VERSION "HNNBNNNYNNNNNNNNNNNNNNNNNNNNNNNNNNNNNNNNNN/4/%%%/4/'%**4NNN///"

NS_ :

BS_:

BU_: AFS AFS_LMod_L AFS_LMod_R BCM1 BVS FCM GLW_LMod_L GLW_LMod_R LCM_L LCM_R LED_DK3_LM_L LED_DK3_LM_R LED_LM_L LED_LM_R LLP_L LLP_R LWR_MXB_L LWR_MXB_R MXB MXB_LM_L MXB_LM_R ZFAS

BO_ 1389 LED_Mess_LM_L_01: 8 LED_LM_L
 SG_ LED_L_Uspg_Schutz : 23|1@1+ (1,0) [0|1] ""  AFS,BCM1,FCM,MXB
 SG_ LED_L_Spannung_KL15 : 24|7@1+ (0.1,6) [6|18.5] "Unit_Volt"  AFS,BCM1,FCM,MXB
 SG_ LED_L_Spannung_KL56a : 31|7@1+ (0.1,6) [6|18.5] "Unit_Volt"  AFS,BCM1,FCM,MXB
 SG_ LED_L_Spannung_KL56b : 38|7@1+ (0.1,6) [6|18.5] "Unit_Volt"  AFS,BCM1,FCM,MXB
 SG_ LED_L_Spannung_TFL : 45|7@1+ (0.1,6) [6|18.5] "Unit_Volt"  AFS,BCM1,FCM,MXB
 SG_ LED_L_Temp_Schutz : 52|1@1+ (1,0) [0|1] ""  AFS,BCM1,FCM,MXB
 SG_ LED_L_Temp_Mux M : 53|3@1+ (1,0) [0|7] ""  AFS,BCM1,FCM,MXB
 SG_ LED_L_Temp_SG_Intern m0 : 56|8@1+ (1,-50) [-50|204] "Unit_DegreCelsi"  AFS,BCM1,FCM,MXB
 SG_ LED_L_Temp_Kanal1_Master m1 : 56|8@1+ (1,-50) [-50|204] "Unit_DegreCelsi"  AFS,BCM1,FCM,MXB
 SG_ LED_L_Temp_Kanal1_Master2 m2 : 56|8@1+ (1,-50) [-50|204] "Unit_DegreCelsi"  AFS,BCM1,FCM,MXB
 SG_ LED_L_Temp_Kanal1_Slave m3 : 56|8@1+ (1,-50) [-50|204] "Unit_DegreCelsi"  AFS,BCM1,FCM,MXB
 SG_ LED_L_Temp_Kanal2_Master m4 : 56|8@1+ (1,-50) [-50|204] "Unit_DegreCelsi"  AFS,BCM1,FCM,MXB
 SG_ LED_L_Temp_Kanal2_Slave m5 : 56|8@1+ (1,-50) [-50|204] "Unit_DegreCelsi"  AFS,BCM1,FCM,MXB
 SG_ LED_L_Temp_Kanal3_Master m6 : 56|8@1+ (1,-50) [-50|204] "Unit_DegreCelsi"  AFS,BCM1,FCM,MXB
 SG_ LED_L_Temp_Kanal3_Slave m7 : 56|8@1+ (1,-50) [-50|204] "Unit_DegreCelsi"  AFS,BCM1,FCM,MXB

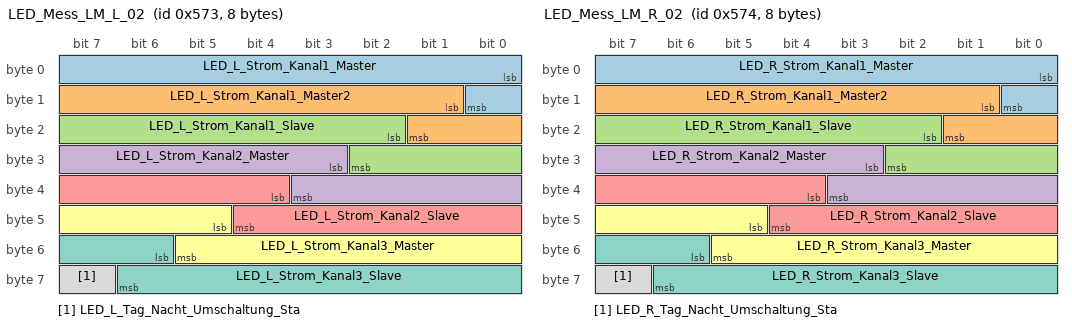
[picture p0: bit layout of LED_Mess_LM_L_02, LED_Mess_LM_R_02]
BO_ 1395 LED_Mess_LM_L_02: 8 LED_LM_L
 SG_ LED_L_Strom_Kanal1_Master : 0|9@1+ (3,0) [0|1515] "Unit_MilliAmper"  AFS,BCM1,FCM,MXB
 SG_ LED_L_Strom_Kanal1_Master2 : 9|9@1+ (3,0) [0|1515] "Unit_MilliAmper"  AFS,BCM1,FCM,MXB
 SG_ LED_L_Strom_Kanal1_Slave : 18|9@1+ (3,0) [0|1515] "Unit_MilliAmper"  AFS,BCM1,FCM,MXB
 SG_ LED_L_Strom_Kanal2_Master : 27|9@1+ (3,0) [0|1515] "Unit_MilliAmper"  AFS,BCM1,FCM,MXB
 SG_ LED_L_Strom_Kanal2_Slave : 36|9@1+ (3,0) [0|1515] "Unit_MilliAmper"  AFS,BCM1,FCM,MXB
 SG_ LED_L_Strom_Kanal3_Master : 45|9@1+ (3,0) [0|1515] "Unit_MilliAmper"  AFS,BCM1,FCM,MXB
 SG_ LED_L_Strom_Kanal3_Slave : 54|9@1+ (3,0) [0|1515] "Unit_MilliAmper"  AFS,BCM1,FCM,MXB
 SG_ LED_L_Tag_Nacht_Umschaltung_Sta : 63|1@1+ (1,0) [0|1] ""  AFS,BCM1,FCM,MXB

BO_ 1390 LED_Mess_LM_R_01: 8 LED_LM_R
 SG_ LED_R_Uspg_Schutz : 23|1@1+ (1,0) [0|1] ""  AFS,BCM1,FCM,MXB
 SG_ LED_R_Spannung_KL15 : 24|7@1+ (0.1,6) [6|18.5] "Unit_Volt"  AFS,BCM1,FCM,MXB
 SG_ LED_R_Spannung_KL56a : 31|7@1+ (0.1,6) [6|18.5] "Unit_Volt"  AFS,BCM1,FCM,MXB
 SG_ LED_R_Spannung_KL56b : 38|7@1+ (0.1,6) [6|18.5] "Unit_Volt"  AFS,BCM1,FCM,MXB
 SG_ LED_R_Spannung_TFL : 45|7@1+ (0.1,6) [6|18.5] "Unit_Volt"  AFS,BCM1,FCM,MXB
 SG_ LED_R_Temp_Schutz : 52|1@1+ (1,0) [0|1] ""  AFS,BCM1,FCM,MXB
 SG_ LED_R_Temp_Mux M : 53|3@1+ (1,0) [0|7] ""  AFS,BCM1,FCM,MXB
 SG_ LED_R_Temp_SG_Intern m0 : 56|8@1+ (1,-50) [-50|204] "Unit_DegreCelsi"  AFS,BCM1,FCM,MXB
 SG_ LED_R_Temp_Kanal1_Master m1 : 56|8@1+ (1,-50) [-50|204] "Unit_DegreCelsi"  AFS,BCM1,FCM,MXB
 SG_ LED_R_Temp_Kanal1_Master2 m2 : 56|8@1+ (1,-50) [-50|204] "Unit_DegreCelsi"  AFS,BCM1,FCM,MXB
 SG_ LED_R_Temp_Kanal1_Slave m3 : 56|8@1+ (1,-50) [-50|204] "Unit_DegreCelsi"  AFS,BCM1,FCM,MXB
 SG_ LED_R_Temp_Kanal2_Master m4 : 56|8@1+ (1,-50) [-50|204] "Unit_DegreCelsi"  AFS,BCM1,FCM,MXB
 SG_ LED_R_Temp_Kanal2_Slave m5 : 56|8@1+ (1,-50) [-50|204] "Unit_DegreCelsi"  AFS,BCM1,FCM,MXB
 SG_ LED_R_Temp_Kanal3_Master m6 : 56|8@1+ (1,-50) [-50|204] "Unit_DegreCelsi"  AFS,BCM1,FCM,MXB
 SG_ LED_R_Temp_Kanal3_Slave m7 : 56|8@1+ (1,-50) [-50|204] "Unit_DegreCelsi"  AFS,BCM1,FCM,MXB

BO_ 1396 LED_Mess_LM_R_02: 8 LED_LM_R
 SG_ LED_R_Strom_Kanal1_Master : 0|9@1+ (3,0) [0|1515] "Unit_MilliAmper"  AFS,BCM1,FCM,MXB
 SG_ LED_R_Strom_Kanal1_Master2 : 9|9@1+ (3,0) [0|1515] "Unit_MilliAmper"  AFS,BCM1,FCM,MXB
 SG_ LED_R_Strom_Kanal1_Slave : 18|9@1+ (3,0) [0|1515] "Unit_MilliAmper"  AFS,BCM1,FCM,MXB
 SG_ LED_R_Strom_Kanal2_Master : 27|9@1+ (3,0) [0|1515] "Unit_MilliAmper"  AFS,BCM1,FCM,MXB
 SG_ LED_R_Strom_Kanal2_Slave : 36|9@1+ (3,0) [0|1515] "Unit_MilliAmper"  AFS,BCM1,FCM,MXB
 SG_ LED_R_Strom_Kanal3_Master : 45|9@1+ (3,0) [0|1515] "Unit_MilliAmper"  AFS,BCM1,FCM,MXB
 SG_ LED_R_Strom_Kanal3_Slave : 54|9@1+ (3,0) [0|1515] "Unit_MilliAmper"  AFS,BCM1,FCM,MXB
 SG_ LED_R_Tag_Nacht_Umschaltung_Sta : 63|1@1+ (1,0) [0|1] ""  AFS,BCM1,FCM,MXB

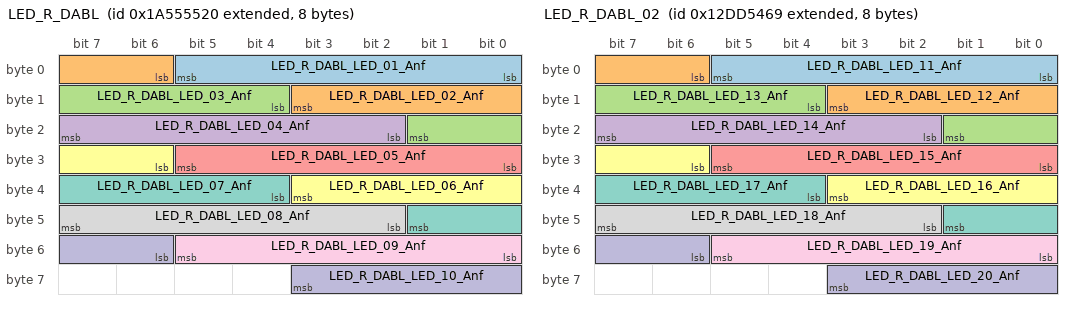
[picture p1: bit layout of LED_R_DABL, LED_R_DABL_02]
BO_ 2589283616 LED_R_DABL: 8 ZFAS
 SG_ LED_R_DABL_LED_01_Anf : 0|6@1+ (1.6,0) [0|100.8] "Unit_PerCent"  LED_DK3_LM_R,LLP_R
 SG_ LED_R_DABL_LED_02_Anf : 6|6@1+ (1.6,0) [0|100.8] "Unit_PerCent"  LED_DK3_LM_R,LLP_R
 SG_ LED_R_DABL_LED_03_Anf : 12|6@1+ (1.6,0) [0|100.8] "Unit_PerCent"  LED_DK3_LM_R,LLP_R
 SG_ LED_R_DABL_LED_04_Anf : 18|6@1+ (1.6,0) [0|100.8] "Unit_PerCent"  LED_DK3_LM_R,LLP_R
 SG_ LED_R_DABL_LED_05_Anf : 24|6@1+ (1.6,0) [0|100.8] "Unit_PerCent"  LED_DK3_LM_R,LLP_R
 SG_ LED_R_DABL_LED_06_Anf : 30|6@1+ (1.6,0) [0|100.8] "Unit_PerCent"  LED_DK3_LM_R,LLP_R
 SG_ LED_R_DABL_LED_07_Anf : 36|6@1+ (1.6,0) [0|100.8] "Unit_PerCent"  LED_DK3_LM_R,LLP_R
 SG_ LED_R_DABL_LED_08_Anf : 42|6@1+ (1.6,0) [0|100.8] "Unit_PerCent"  LED_DK3_LM_R,LLP_R
 SG_ LED_R_DABL_LED_09_Anf : 48|6@1+ (1.6,0) [0|100.8] "Unit_PerCent"  LED_DK3_LM_R,LLP_R
 SG_ LED_R_DABL_LED_10_Anf : 54|6@1+ (1.6,0) [0|100.8] "Unit_PerCent"  LED_DK3_LM_R,LLP_R

BO_ 2463978601 LED_R_DABL_02: 8 ZFAS
 SG_ LED_R_DABL_LED_11_Anf : 0|6@1+ (1.6,0) [0|100.8] "Unit_PerCent"  LED_DK3_LM_R,LLP_R
 SG_ LED_R_DABL_LED_12_Anf : 6|6@1+ (1.6,0) [0|100.8] "Unit_PerCent"  LED_DK3_LM_R,LLP_R
 SG_ LED_R_DABL_LED_13_Anf : 12|6@1+ (1.6,0) [0|100.8] "Unit_PerCent"  LED_DK3_LM_R,LLP_R
 SG_ LED_R_DABL_LED_14_Anf : 18|6@1+ (1.6,0) [0|100.8] "Unit_PerCent"  LED_DK3_LM_R,LLP_R
 SG_ LED_R_DABL_LED_15_Anf : 24|6@1+ (1.6,0) [0|100.8] "Unit_PerCent"  LED_DK3_LM_R,LLP_R
 SG_ LED_R_DABL_LED_16_Anf : 30|6@1+ (1.6,0) [0|100.8] "Unit_PerCent"  LED_DK3_LM_R,LLP_R
 SG_ LED_R_DABL_LED_17_Anf : 36|6@1+ (1.6,0) [0|100.8] "Unit_PerCent"  LED_DK3_LM_R,LLP_R
 SG_ LED_R_DABL_LED_18_Anf : 42|6@1+ (1.6,0) [0|100.8] "Unit_PerCent"  LED_DK3_LM_R,LLP_R
 SG_ LED_R_DABL_LED_19_Anf : 48|6@1+ (1.6,0) [0|100.8] "Unit_PerCent"  LED_DK3_LM_R,LLP_R
 SG_ LED_R_DABL_LED_20_Anf : 54|6@1+ (1.6,0) [0|100.8] "Unit_PerCent"  LED_DK3_LM_R,LLP_R

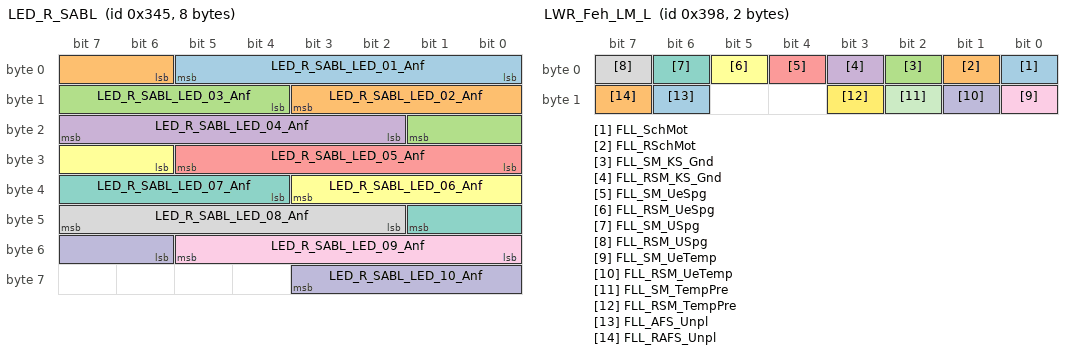
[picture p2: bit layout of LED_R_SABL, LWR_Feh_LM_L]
BO_ 837 LED_R_SABL: 8 BCM1
 SG_ LED_R_SABL_LED_01_Anf : 0|6@1+ (1.6,0) [0|100.8] "Unit_PerCent"  LED_DK3_LM_R,LLP_R
 SG_ LED_R_SABL_LED_02_Anf : 6|6@1+ (1.6,0) [0|100.8] "Unit_PerCent"  LED_DK3_LM_R,LLP_R
 SG_ LED_R_SABL_LED_03_Anf : 12|6@1+ (1.6,0) [0|100.8] "Unit_PerCent"  LED_DK3_LM_R,LLP_R
 SG_ LED_R_SABL_LED_04_Anf : 18|6@1+ (1.6,0) [0|100.8] "Unit_PerCent"  LED_DK3_LM_R,LLP_R
 SG_ LED_R_SABL_LED_05_Anf : 24|6@1+ (1.6,0) [0|100.8] "Unit_PerCent"  LED_DK3_LM_R,LLP_R
 SG_ LED_R_SABL_LED_06_Anf : 30|6@1+ (1.6,0) [0|100.8] "Unit_PerCent"  LED_DK3_LM_R,LLP_R
 SG_ LED_R_SABL_LED_07_Anf : 36|6@1+ (1.6,0) [0|100.8] "Unit_PerCent"  LED_DK3_LM_R,LLP_R
 SG_ LED_R_SABL_LED_08_Anf : 42|6@1+ (1.6,0) [0|100.8] "Unit_PerCent"  LED_DK3_LM_R,LLP_R
 SG_ LED_R_SABL_LED_09_Anf : 48|6@1+ (1.6,0) [0|100.8] "Unit_PerCent"  LED_DK3_LM_R,LLP_R
 SG_ LED_R_SABL_LED_10_Anf : 54|6@1+ (1.6,0) [0|100.8] "Unit_PerCent"  LED_DK3_LM_R,LLP_R

BO_ 404 LED_Soll_Fkt0: 8 AFS
 SG_ LED_L_Abblendl_Anf : 0|1@1+ (1,0) [0|1] ""  BVS,LCM_L,LED_DK3_LM_L,LED_LM_L,LLP_L,ZFAS
 SG_ LED_L_Abblendl_Schaltart : 1|1@1+ (1,0) [0|1] ""  BVS,LED_DK3_LM_L,LED_LM_L,LLP_L,ZFAS
 SG_ LED_R_Abblendl_Anf : 2|1@1+ (1,0) [0|1] ""  BVS,LCM_R,LED_DK3_LM_R,LED_LM_R,LLP_R,ZFAS
 SG_ LED_R_Abblendl_Schaltart : 3|1@1+ (1,0) [0|1] ""  BVS,LED_DK3_LM_R,LED_LM_R,LLP_R,ZFAS
 SG_ LED_L_Fernl_LH_Anf : 4|1@1+ (1,0) [0|1] ""  BVS,LED_DK3_LM_L,LED_LM_L,LLP_L,ZFAS
 SG_ LED_L_Fernl_LH_Schaltart : 5|1@1+ (1,0) [0|1] ""  BVS,LED_DK3_LM_L,LED_LM_L,LLP_L,ZFAS
 SG_ LED_R_Fernl_LH_Anf : 6|1@1+ (1,0) [0|1] ""  BVS,LED_DK3_LM_R,LED_LM_R,LLP_R,ZFAS
 SG_ LED_R_Fernl_LH_Schaltart : 7|1@1+ (1,0) [0|1] ""  BVS,LED_DK3_LM_R,LED_LM_R,LLP_R,ZFAS
 SG_ LED_L_Nebel_All_Anf : 8|1@1+ (1,0) [0|1] ""  BVS,LED_DK3_LM_L,LED_LM_L,LLP_L,ZFAS
 SG_ LED_L_Nebel_All_Schaltart : 9|1@1+ (1,0) [0|1] ""  BVS,LED_DK3_LM_L,LED_LM_L,LLP_L,ZFAS
 SG_ LED_R_Nebel_All_Anf : 10|1@1+ (1,0) [0|1] ""  BVS,LED_DK3_LM_R,LED_LM_R,LLP_R,ZFAS
 SG_ LED_R_Nebel_All_Schaltart : 11|1@1+ (1,0) [0|1] ""  BVS,LED_DK3_LM_R,LED_LM_R,LLP_R,ZFAS
 SG_ LED_Sta_Diag : 12|4@1+ (1,0) [0|15] ""  LED_LM_L,LED_LM_R
 SG_ LED_L_Zus_Fernl_LH_Anf : 16|1@1+ (1,0) [0|1] ""  BVS,LED_DK3_LM_L,LED_LM_L,LLP_L,ZFAS
 SG_ LED_L_Zus_Fernl_LH_Schaltart : 17|1@1+ (1,0) [0|1] ""  BVS,LED_DK3_LM_L,LED_LM_L,LLP_L,ZFAS
 SG_ LED_R_Zus_Fernl_LH_Anf : 18|1@1+ (1,0) [0|1] ""  BVS,LED_DK3_LM_R,LED_LM_R,LLP_R,ZFAS
 SG_ LED_R_Zus_Fernl_LH_Schaltart : 19|1@1+ (1,0) [0|1] ""  BVS,LED_DK3_LM_R,LED_LM_R,LLP_R,ZFAS

BO_ 405 LED_Soll_Fkt1: 8 AFS
 SG_ LED_L_Abbiegel_Anf : 0|1@1+ (1,0) [0|1] ""  BVS,LED_DK3_LM_L,LED_LM_L,LLP_L,ZFAS
 SG_ LED_L_Abbiegel_Schaltart : 1|1@1+ (1,0) [0|1] ""  BVS,LED_DK3_LM_L,LED_LM_L,LLP_L,ZFAS
 SG_ LED_R_Abbiegel_Anf : 2|1@1+ (1,0) [0|1] ""  BVS,LED_DK3_LM_R,LED_LM_R,LLP_R,ZFAS
 SG_ LED_R_Abbiegel_Schaltart : 3|1@1+ (1,0) [0|1] ""  BVS,LED_DK3_LM_R,LED_LM_R,LLP_R,ZFAS
 SG_ LED_L_Autobahnl_Anf : 4|1@1+ (1,0) [0|1] ""  BVS,LED_DK3_LM_L,LED_LM_L,LLP_L,ZFAS
 SG_ LED_L_Autobahnl_Schaltart : 5|1@1+ (1,0) [0|1] ""  BVS,LED_DK3_LM_L,LED_LM_L,LLP_L,ZFAS
 SG_ LED_R_Autobahnl_Anf : 6|1@1+ (1,0) [0|1] ""  BVS,LED_DK3_LM_R,LED_LM_R,LLP_R,ZFAS
 SG_ LED_R_Autobahnl_Schaltart : 7|1@1+ (1,0) [0|1] ""  BVS,LED_DK3_LM_R,LED_LM_R,LLP_R,ZFAS
 SG_ LED_L_Eco_Mode_1_Anf : 8|1@1+ (1,0) [0|1] ""  BVS,LED_DK3_LM_L,LED_LM_L,LLP_L,ZFAS
 SG_ LED_L_Eco_Mode_1_Schaltart : 9|1@1+ (1,0) [0|1] ""  BVS,LED_DK3_LM_L,LED_LM_L,LLP_L,ZFAS
 SG_ LED_R_Eco_Mode_1_Anf : 10|1@1+ (1,0) [0|1] ""  BVS,LED_DK3_LM_R,LED_LM_R,LLP_R,ZFAS
 SG_ LED_R_Eco_Mode_1_Schaltart : 11|1@1+ (1,0) [0|1] ""  BVS,LED_DK3_LM_R,LED_LM_R,LLP_R,ZFAS
 SG_ LED_L_Eco_Mode_2_Anf : 12|1@1+ (1,0) [0|1] ""  BVS,LED_DK3_LM_L,LED_LM_L,LLP_L,ZFAS
 SG_ LED_L_Eco_Mode_2_Schaltart : 13|1@1+ (1,0) [0|1] ""  BVS,LED_DK3_LM_L,LED_LM_L,LLP_L,ZFAS
 SG_ LED_R_Eco_Mode_2_Anf : 14|1@1+ (1,0) [0|1] ""  BVS,LED_DK3_LM_R,LED_LM_R,LLP_R,ZFAS
 SG_ LED_R_Eco_Mode_2_Schaltart : 15|1@1+ (1,0) [0|1] ""  BVS,LED_DK3_LM_R,LED_LM_R,LLP_R,ZFAS
 SG_ LED_L_Rennl_Anf : 16|1@1+ (1,0) [0|1] ""  BVS,LED_DK3_LM_L,LED_LM_L,LLP_L,ZFAS
 SG_ LED_L_Rennl_Schaltart : 17|1@1+ (1,0) [0|1] ""  BVS,LED_DK3_LM_L,LED_LM_L,LLP_L,ZFAS
 SG_ LED_R_Rennl_Anf : 18|1@1+ (1,0) [0|1] ""  BVS,LED_DK3_LM_R,LED_LM_R,LLP_R,ZFAS
 SG_ LED_R_Rennl_Schaltart : 19|1@1+ (1,0) [0|1] ""  BVS,LED_DK3_LM_R,LED_LM_R,LLP_R,ZFAS
 SG_ LED_L_Stadtl_Anf : 20|1@1+ (1,0) [0|1] ""  BVS,LED_DK3_LM_L,LED_LM_L,LLP_L,ZFAS
 SG_ LED_L_Stadtl_Schaltart : 21|1@1+ (1,0) [0|1] ""  BVS,LED_DK3_LM_L,LED_LM_L,LLP_L,ZFAS
 SG_ LED_R_Stadtl_Anf : 22|1@1+ (1,0) [0|1] ""  BVS,LED_DK3_LM_R,LED_LM_R,LLP_R,ZFAS
 SG_ LED_R_Stadtl_Schaltart : 23|1@1+ (1,0) [0|1] ""  BVS,LED_DK3_LM_R,LED_LM_R,LLP_R,ZFAS
 SG_ LED_L_TFL_Anf : 24|2@1+ (1,0) [0|3] ""  BVS,LED_DK3_LM_L,LED_LM_L,LLP_L,ZFAS
 SG_ LED_L_TFL_Schaltart : 26|1@1+ (1,0) [0|1] ""  BVS,LED_DK3_LM_L,LED_LM_L,LLP_L,ZFAS
 SG_ LED_R_TFL_Anf : 27|2@1+ (1,0) [0|3] ""  BVS,LED_DK3_LM_R,LED_LM_R,LLP_R,ZFAS
 SG_ LED_R_TFL_Schaltart : 29|1@1+ (1,0) [0|1] ""  BVS,LED_DK3_LM_R,LED_LM_R,LLP_R,ZFAS
 SG_ LED_L_Touristenl_Anf : 30|1@1+ (1,0) [0|1] ""  BVS,LED_DK3_LM_L,LED_LM_L,LLP_L,ZFAS
 SG_ LED_L_Touristenl_Schaltart : 31|1@1+ (1,0) [0|1] ""  BVS,LED_DK3_LM_L,LED_LM_L,LLP_L,ZFAS
 SG_ LED_R_Touristenl_Anf : 32|1@1+ (1,0) [0|1] ""  BVS,LED_DK3_LM_R,LED_LM_R,LLP_R,ZFAS
 SG_ LED_R_Touristenl_Schaltart : 33|1@1+ (1,0) [0|1] ""  BVS,LED_DK3_LM_R,LED_LM_R,LLP_R,ZFAS
 SG_ LED_ECE_SAE_Umschaltung_Anf : 34|1@1+ (1,0) [0|1] ""  BVS,LED_DK3_LM_L,LED_DK3_LM_R,LED_LM_L,LED_LM_R,LLP_L,LLP_R,ZFAS
 SG_ LED_Tag_Nacht_Umschaltung_Anf : 35|1@1+ (1,0) [0|1] ""  BVS,LED_DK3_LM_L,LED_DK3_LM_R,LED_LM_L,LED_LM_R,LLP_L,LLP_R,ZFAS
 SG_ LED_Sta_Diag : 36|4@1+ (1,0) [0|15] ""  LED_LM_L,LED_LM_R
 SG_ LED_L_Abbiegel_Dimmung : 40|8@1+ (0.4,0) [0|100] "Unit_PerCent"  BVS,LED_DK3_LM_L,LED_LM_L,LLP_L,ZFAS
 SG_ LED_R_Abbiegel_Dimmung : 48|8@1+ (0.4,0) [0|100] "Unit_PerCent"  BVS,LED_DK3_LM_R,LED_LM_R,LLP_R,ZFAS

BO_ 351 LED_Soll_Fkt2: 8 BCM1
 SG_ LED_Soll_Fkt2_CRC : 0|8@1+ (1,0) [0|255] ""  LED_DK3_LM_L,LED_DK3_LM_R,LLP_L,LLP_R
 SG_ LED_Soll_Fkt2_BZ : 8|4@1+ (1,0) [0|15] ""  LED_DK3_LM_L,LED_DK3_LM_R,LLP_L,LLP_R
 SG_ LED_L_Abblendl_Anf : 12|1@1+ (1,0) [0|1] ""  LED_DK3_LM_L,LLP_L
 SG_ LED_L_Abblendl_Schaltart : 13|1@1+ (1,0) [0|1] ""  LED_DK3_LM_L,LLP_L
 SG_ LED_R_Abblendl_Anf : 14|1@1+ (1,0) [0|1] ""  LED_DK3_LM_R,LLP_R
 SG_ LED_R_Abblendl_Schaltart : 15|1@1+ (1,0) [0|1] ""  LED_DK3_LM_R,LLP_R
 SG_ LED_L_Fernl_LH_Anf : 16|1@1+ (1,0) [0|1] ""  LED_DK3_LM_L,LLP_L
 SG_ LED_L_Fernl_LH_Schaltart : 17|1@1+ (1,0) [0|1] ""  LED_DK3_LM_L,LLP_L
 SG_ LED_R_Fernl_LH_Anf : 18|1@1+ (1,0) [0|1] ""  LED_DK3_LM_R,LLP_R
 SG_ LED_R_Fernl_LH_Schaltart : 19|1@1+ (1,0) [0|1] ""  LED_DK3_LM_R,LLP_R
 SG_ LED_L_Nebel_All_Anf : 20|1@1+ (1,0) [0|1] ""  LED_DK3_LM_L,LLP_L
 SG_ LED_L_Nebel_All_Schaltart : 21|1@1+ (1,0) [0|1] ""  LED_DK3_LM_L,LLP_L
 SG_ LED_R_Nebel_All_Anf : 22|1@1+ (1,0) [0|1] ""  LED_DK3_LM_R,LLP_R
 SG_ LED_R_Nebel_All_Schaltart : 23|1@1+ (1,0) [0|1] ""  LED_DK3_LM_R,LLP_R
 SG_ LED_Sta_Diag : 24|4@1+ (1,0) [0|15] ""  LED_DK3_LM_L,LED_DK3_LM_R,LLP_L,LLP_R
 SG_ LED_L_Zus_Fernl_LH_Anf : 28|1@1+ (1,0) [0|1] ""  LED_DK3_LM_L,LLP_L
 SG_ LED_L_Zus_Fernl_LH_Schaltart : 29|1@1+ (1,0) [0|1] ""  LED_DK3_LM_L,LLP_L
 SG_ LED_R_Zus_Fernl_LH_Anf : 30|1@1+ (1,0) [0|1] ""  LED_DK3_LM_R,LLP_R
 SG_ LED_R_Zus_Fernl_LH_Schaltart : 31|1@1+ (1,0) [0|1] ""  LED_DK3_LM_R,LLP_R
 SG_ BCM1_CH_aktiv : 45|1@1+ (1,0) [0|1] ""  LED_DK3_LM_L,LED_DK3_LM_R,LLP_L,LLP_R
 SG_ BCM1_LH_aktiv : 46|1@1+ (1,0) [0|1] ""  LED_DK3_LM_L,LED_DK3_LM_R,LLP_L,LLP_R

BO_ 920 LWR_Feh_LM_L: 2 AFS_LMod_L
 SG_ FLL_SchMot : 0|1@1+ (1,0) [0|1] ""  AFS,BCM1,FCM,MXB
 SG_ FLL_RSchMot : 1|1@1+ (1,0) [0|1] ""  AFS,BCM1,FCM,MXB
 SG_ FLL_SM_KS_Gnd : 2|1@1+ (1,0) [0|1] ""  AFS,BCM1,FCM,MXB
 SG_ FLL_RSM_KS_Gnd : 3|1@1+ (1,0) [0|1] ""  AFS,BCM1,FCM,MXB
 SG_ FLL_SM_UeSpg : 4|1@1+ (1,0) [0|1] ""  AFS,BCM1,FCM,MXB
 SG_ FLL_RSM_UeSpg : 5|1@1+ (1,0) [0|1] ""  AFS,BCM1,FCM,MXB
 SG_ FLL_SM_USpg : 6|1@1+ (1,0) [0|1] ""  AFS,BCM1,FCM,MXB
 SG_ FLL_RSM_USpg : 7|1@1+ (1,0) [0|1] ""  AFS,BCM1,FCM,MXB
 SG_ FLL_SM_UeTemp : 8|1@1+ (1,0) [0|1] ""  AFS,BCM1,FCM,MXB
 SG_ FLL_RSM_UeTemp : 9|1@1+ (1,0) [0|1] ""  AFS,BCM1,FCM,MXB
 SG_ FLL_SM_TempPre : 10|1@1+ (1,0) [0|1] ""  AFS,BCM1,FCM,MXB
 SG_ FLL_RSM_TempPre : 11|1@1+ (1,0) [0|1] ""  AFS,BCM1,FCM,MXB
 SG_ FLL_AFS_Unpl : 14|1@1+ (1,0) [0|1] ""  AFS,BCM1,FCM,MXB
 SG_ FLL_RAFS_Unpl : 15|1@1+ (1,0) [0|1] ""  AFS,BCM1,FCM,MXB

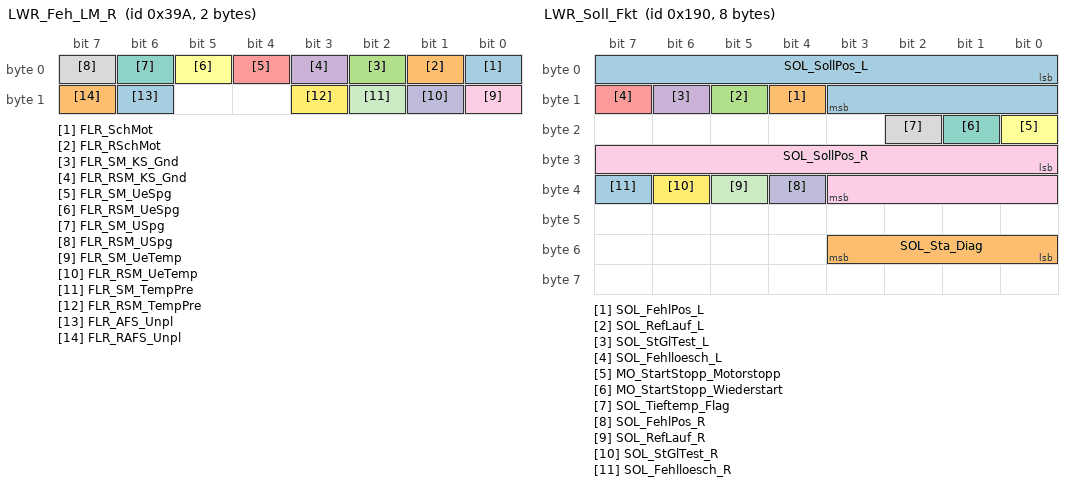
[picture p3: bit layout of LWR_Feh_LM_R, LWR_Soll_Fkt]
BO_ 922 LWR_Feh_LM_R: 2 AFS_LMod_R
 SG_ FLR_SchMot : 0|1@1+ (1,0) [0|1] ""  AFS,BCM1,FCM,MXB
 SG_ FLR_RSchMot : 1|1@1+ (1,0) [0|1] ""  AFS,BCM1,FCM,MXB
 SG_ FLR_SM_KS_Gnd : 2|1@1+ (1,0) [0|1] ""  AFS,BCM1,FCM,MXB
 SG_ FLR_RSM_KS_Gnd : 3|1@1+ (1,0) [0|1] ""  AFS,BCM1,FCM,MXB
 SG_ FLR_SM_UeSpg : 4|1@1+ (1,0) [0|1] ""  AFS,BCM1,FCM,MXB
 SG_ FLR_RSM_UeSpg : 5|1@1+ (1,0) [0|1] ""  AFS,BCM1,FCM,MXB
 SG_ FLR_SM_USpg : 6|1@1+ (1,0) [0|1] ""  AFS,BCM1,FCM,MXB
 SG_ FLR_RSM_USpg : 7|1@1+ (1,0) [0|1] ""  AFS,BCM1,FCM,MXB
 SG_ FLR_SM_UeTemp : 8|1@1+ (1,0) [0|1] ""  AFS,BCM1,FCM,MXB
 SG_ FLR_RSM_UeTemp : 9|1@1+ (1,0) [0|1] ""  AFS,BCM1,FCM,MXB
 SG_ FLR_SM_TempPre : 10|1@1+ (1,0) [0|1] ""  AFS,BCM1,FCM,MXB
 SG_ FLR_RSM_TempPre : 11|1@1+ (1,0) [0|1] ""  AFS,BCM1,FCM,MXB
 SG_ FLR_AFS_Unpl : 14|1@1+ (1,0) [0|1] ""  AFS,BCM1,FCM,MXB
 SG_ FLR_RAFS_Unpl : 15|1@1+ (1,0) [0|1] ""  AFS,BCM1,FCM,MXB

BO_ 400 LWR_Soll_Fkt: 8 AFS
 SG_ SOL_SollPos_L : 0|12@1+ (0.5,-1023) [-1023|1022.5] "Unit_MilliMeter"  AFS_LMod_L,BVS,GLW_LMod_L,LCM_L,LLP_L,LWR_MXB_L,ZFAS
 SG_ SOL_FehlPos_L : 12|1@1+ (1,0) [0|1] ""  AFS_LMod_L,BVS,GLW_LMod_L,LCM_L,LLP_L,LWR_MXB_L,ZFAS
 SG_ SOL_RefLauf_L : 13|1@1+ (1,0) [0|1] ""  AFS_LMod_L,BVS,GLW_LMod_L,LCM_L,LLP_L,LWR_MXB_L,ZFAS
 SG_ SOL_StGlTest_L : 14|1@1+ (1,0) [0|1] ""  AFS_LMod_L,BVS,GLW_LMod_L,LCM_L,LLP_L,LWR_MXB_L,ZFAS
 SG_ SOL_Fehlloesch_L : 15|1@1+ (1,0) [0|1] ""  AFS_LMod_L,GLW_LMod_L,LWR_MXB_L
 SG_ MO_StartStopp_Motorstopp : 16|1@1+ (1,0) [0|1] ""  AFS_LMod_L,AFS_LMod_R,GLW_LMod_L,GLW_LMod_R,LED_DK3_LM_L,LED_DK3_LM_R,LED_LM_L,LED_LM_R,LLP_L,LLP_R,LWR_MXB_L,LWR_MXB_R,MXB_LM_L,MXB_LM_R
 SG_ MO_StartStopp_Wiederstart : 17|1@1+ (1,0) [0|1] ""  AFS_LMod_L,AFS_LMod_R,GLW_LMod_L,GLW_LMod_R,LED_DK3_LM_L,LED_DK3_LM_R,LED_LM_L,LED_LM_R,LLP_L,LLP_R,LWR_MXB_L,LWR_MXB_R,MXB_LM_L,MXB_LM_R
 SG_ SOL_Tieftemp_Flag : 18|1@1+ (1,0) [0|1] ""  AFS_LMod_L,AFS_LMod_R,BVS,GLW_LMod_L,GLW_LMod_R,LCM_L,LCM_R,LLP_L,LLP_R,LWR_MXB_L,LWR_MXB_R,ZFAS
 SG_ SOL_SollPos_R : 24|12@1+ (0.5,-1023) [-1023|1022.5] "Unit_MilliMeter"  AFS_LMod_R,BVS,GLW_LMod_R,LCM_R,LLP_R,LWR_MXB_R,ZFAS
 SG_ SOL_FehlPos_R : 36|1@1+ (1,0) [0|1] ""  AFS_LMod_R,BVS,GLW_LMod_R,LCM_R,LLP_R,LWR_MXB_R,ZFAS
 SG_ SOL_RefLauf_R : 37|1@1+ (1,0) [0|1] ""  AFS_LMod_R,BVS,GLW_LMod_R,LCM_R,LLP_R,LWR_MXB_R,ZFAS
 SG_ SOL_StGlTest_R : 38|1@1+ (1,0) [0|1] ""  AFS_LMod_R,BVS,GLW_LMod_R,LCM_R,LLP_R,LWR_MXB_R,ZFAS
 SG_ SOL_Fehlloesch_R : 39|1@1+ (1,0) [0|1] ""  AFS_LMod_R,GLW_LMod_R,LWR_MXB_R
 SG_ SOL_Sta_Diag : 48|4@1+ (1,0) [0|15] ""  AFS_LMod_L,AFS_LMod_R,BVS,GLW_LMod_L,GLW_LMod_R,LWR_MXB_L,LWR_MXB_R,MXB_LM_L,MXB_LM_R,ZFAS

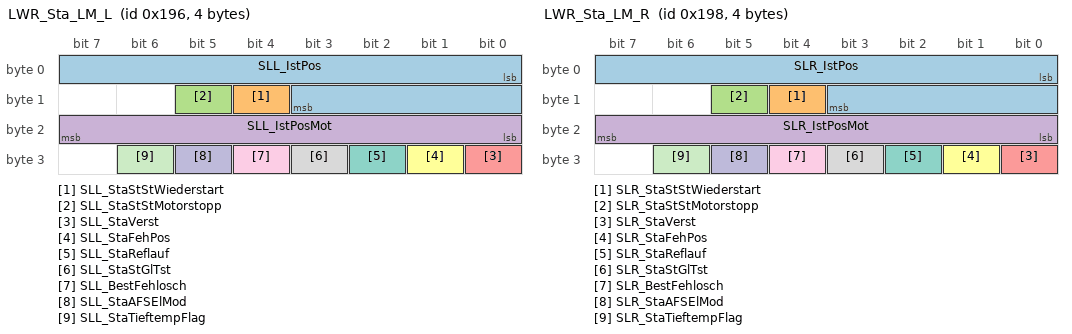
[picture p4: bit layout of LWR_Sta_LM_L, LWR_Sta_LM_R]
BO_ 406 LWR_Sta_LM_L: 4 AFS_LMod_L
 SG_ SLL_IstPos : 0|12@1+ (0.5,-1023) [-1023|1022.5] "Unit_MilliMeter"  AFS,BCM1,FCM,MXB
 SG_ SLL_StaStStWiederstart : 12|1@1+ (1,0) [0|1] ""  AFS,BCM1,FCM,LED_LM_L,MXB,MXB_LM_L
 SG_ SLL_StaStStMotorstopp : 13|1@1+ (1,0) [0|1] ""  AFS,BCM1,FCM,LED_LM_L,MXB,MXB_LM_L
 SG_ SLL_IstPosMot : 16|8@1+ (0.4,0) [0|100] "Unit_PerCent"  AFS,BCM1,FCM,MXB
 SG_ SLL_StaVerst : 24|1@1+ (1,0) [0|1] ""  AFS,BCM1,FCM,MXB
 SG_ SLL_StaFehPos : 25|1@1+ (1,0) [0|1] ""  AFS,BCM1,FCM,MXB
 SG_ SLL_StaReflauf : 26|1@1+ (1,0) [0|1] ""  AFS,BCM1,BVS,FCM,MXB,ZFAS
 SG_ SLL_StaStGlTst : 27|1@1+ (1,0) [0|1] ""  AFS,BCM1,FCM,MXB
 SG_ SLL_BestFehlosch : 28|1@1+ (1,0) [0|1] ""  AFS,BCM1,FCM,MXB
 SG_ SLL_StaAFSElMod : 29|1@1+ (1,0) [0|1] ""  AFS,BCM1,FCM,MXB
 SG_ SLL_StaTieftempFlag : 30|1@1+ (1,0) [0|1] ""  AFS,BCM1,FCM,MXB

BO_ 408 LWR_Sta_LM_R: 4 AFS_LMod_R
 SG_ SLR_IstPos : 0|12@1+ (0.5,-1023) [-1023|1022.5] "Unit_MilliMeter"  AFS,BCM1,FCM,MXB
 SG_ SLR_StaStStWiederstart : 12|1@1+ (1,0) [0|1] ""  AFS,BCM1,FCM,LED_LM_R,MXB,MXB_LM_R
 SG_ SLR_StaStStMotorstopp : 13|1@1+ (1,0) [0|1] ""  AFS,BCM1,FCM,LED_LM_R,MXB,MXB_LM_R
 SG_ SLR_IstPosMot : 16|8@1+ (0.4,0) [0|100] "Unit_PerCent"  AFS,BCM1,FCM,MXB
 SG_ SLR_StaVerst : 24|1@1+ (1,0) [0|1] ""  AFS,BCM1,FCM,MXB
 SG_ SLR_StaFehPos : 25|1@1+ (1,0) [0|1] ""  AFS,BCM1,FCM,MXB
 SG_ SLR_StaReflauf : 26|1@1+ (1,0) [0|1] ""  AFS,BCM1,BVS,FCM,MXB,ZFAS
 SG_ SLR_StaStGlTst : 27|1@1+ (1,0) [0|1] ""  AFS,BCM1,FCM,MXB
 SG_ SLR_BestFehlosch : 28|1@1+ (1,0) [0|1] ""  AFS,BCM1,FCM,MXB
 SG_ SLR_StaAFSElMod : 29|1@1+ (1,0) [0|1] ""  AFS,BCM1,FCM,MXB
 SG_ SLR_StaTieftempFlag : 30|1@1+ (1,0) [0|1] ""  AFS,BCM1,FCM,MXB

BO_ 958 Motor_14: 8 AFS
 SG_ Motor_14_CRC : 0|8@1+ (1,0) [0|255] "" Vector__XXX
 SG_ Motor_14_BZ : 8|4@1+ (1,0) [0|15] "" Vector__XXX
 SG_ MO_StartStopp_Status : 12|2@1+ (1,0) [0|3] "" Vector__XXX
 SG_ MO_StartStopp_Wiederstart : 14|1@1+ (1,0) [0|1] ""  LCM_L,LCM_R,LLP_L,LLP_R
 SG_ MO_StartStopp_Motorstopp : 15|1@1+ (1,0) [0|1] ""  LCM_L,LCM_R,LLP_L,LLP_R
 SG_ MO_Freig_Reku : 16|2@1+ (1,0) [0|3] "" Vector__XXX
 SG_ MO_Kl_75 : 18|1@1+ (1,0) [0|1] ""  LCM_L,LCM_R,LLP_L,LLP_R
 SG_ MO_Kl_50 : 19|1@1+ (1,0) [0|1] "" Vector__XXX
 SG_ MO_Gangposition : 20|4@1+ (1,0) [0|15] "" Vector__XXX
 SG_ MO_StartStopp_Fahrerwunsch : 24|2@1+ (1,0) [0|3] "" Vector__XXX
 SG_ MO_HYB_Fahrbereitschaft : 26|1@1+ (1,0) [0|1] "" Vector__XXX
 SG_ MO_Ext_E_Fahrt_aktiv : 27|1@1+ (1,0) [0|1] "" Vector__XXX
 SG_ MO_Fahrer_bremst : 28|1@1+ (1,0) [0|1] "" Vector__XXX
 SG_ MO_QBit_Fahrer_bremst : 29|1@1+ (1,0) [0|1] "" Vector__XXX
 SG_ MO_BLS : 30|1@1+ (1,0) [0|1] "" Vector__XXX
 SG_ MO_Konsistenz_Bremsped : 31|1@1+ (1,0) [0|1] "" Vector__XXX
 SG_ MO_KomFehler_ESP : 32|1@1+ (1,0) [0|1] "" Vector__XXX
 SG_ MO_Klima_Eingr : 33|2@1+ (1,0) [0|3] "" Vector__XXX
 SG_ MO_Aussp_Anlass : 35|1@1+ (1,0) [0|1] "" Vector__XXX
 SG_ MO_Freig_Anlass : 36|1@1+ (1,0) [0|1] "" Vector__XXX
 SG_ MO_Kuppl_schalter : 37|1@1+ (1,0) [0|1] "" Vector__XXX
 SG_ MO_Interlock : 38|1@1+ (1,0) [0|1] "" Vector__XXX
 SG_ MO_Motor_laeuft : 39|1@1+ (1,0) [0|1] "" Vector__XXX
 SG_ MO_Kickdown : 40|1@1+ (1,0) [0|1] "" Vector__XXX
 SG_ MO_QBit_KL_75 : 41|1@1+ (1,0) [0|1] "" Vector__XXX
 SG_ MO_EKlKomLeiRed : 42|2@1+ (1,0) [0|3] "" Vector__XXX
 SG_ MO_Handshake_STH : 44|1@1+ (1,0) [0|1] "" Vector__XXX
 SG_ MO_BKV_Unterdruckwarnung : 45|1@1+ (1,0) [0|1] "" Vector__XXX
 SG_ MO_Freigabe_Segeln : 46|1@1+ (1,0) [0|1] "" Vector__XXX
 SG_ MO_PTC_Status : 47|3@1+ (1,0) [0|7] "" Vector__XXX
 SG_ MO_QBit_Gangposition : 50|1@1+ (1,0) [0|1] "" Vector__XXX
 SG_ MO_Signalquelle_Gangposition : 51|1@1+ (1,0) [0|1] "" Vector__XXX
 SG_ MO_Remotestart_Betrieb : 52|1@1+ (1,0) [0|1] "" Vector__XXX
 SG_ MO_Remotestart_moeglich : 53|1@1+ (1,0) [0|1] "" Vector__XXX
 SG_ MO_FMAus_aktiv : 55|1@1+ (1,0) [0|1] "" Vector__XXX
 SG_ MO_FMAus_Startvariante : 56|2@1+ (1,0) [0|3] "" Vector__XXX
 SG_ MO_BMS_NV_Anf_stuetzen : 58|1@1+ (1,0) [0|1] "" Vector__XXX
 SG_ MO_Zylinderabschaltung : 59|2@1+ (1,0) [0|3] "" Vector__XXX
 SG_ MO_HYB_VM_aktiv : 61|1@1+ (1,0) [0|1] "" Vector__XXX
 SG_ MO_StartVorauss_erfuellt : 62|2@1+ (1,0) [0|3] "" Vector__XXX

BO_ 994 MXB_01: 8 BVS
 SG_ MXB_Allgemein_li_defekt : 12|1@1+ (1,0) [0|1] ""  BCM1
 SG_ MXB_Allgemein_re_defekt : 13|1@1+ (1,0) [0|1] ""  BCM1
 SG_ MXB_Fernlicht_li_defekt : 14|1@1+ (1,0) [0|1] ""  BCM1
 SG_ MXB_Fernlicht_re_defekt : 15|1@1+ (1,0) [0|1] ""  BCM1
 SG_ MXB_Fernlicht_Status : 16|1@1+ (1,0) [0|1] ""  BCM1
 SG_ MXB_Sicherheitspos_li_Anf : 17|1@1+ (1,0) [0|1] ""  BCM1
 SG_ MXB_Sicherheitspos_re_Anf : 18|1@1+ (1,0) [0|1] ""  BCM1
 SG_ MXB_Verfuegbarkeit : 19|1@1+ (1,0) [0|1] ""  BCM1
 SG_ Kamera_Sensor_blockiert : 20|1@1+ (1,0) [0|1] ""  BCM1
 SG_ AFS_Allwetterlicht_Unterdrueck : 21|1@1+ (1,0) [0|1] ""  BCM1
 SG_ AFS_Autobahnlicht_Unterdrueckung : 22|1@1+ (1,0) [0|1] ""  BCM1
 SG_ AFS_Blinkermode_BVS : 23|1@1+ (1,0) [0|1] ""  BCM1
 SG_ AFS_Fehlertext_BVS : 24|1@1+ (1,0) [0|1] ""  BCM1
 SG_ AFS_Lampe_BVS : 25|1@1+ (1,0) [0|1] ""  BCM1
 SG_ AFS_Stadtlicht_Unterdrueckung : 26|1@1+ (1,0) [0|1] ""  BCM1
 SG_ MXB_Z_Fernlicht_L_Anf : 32|1@1+ (1,0) [0|1] ""  BCM1
 SG_ MXB_Z_Fernlicht_L_Schaltart : 33|1@1+ (1,0) [0|1] ""  BCM1
 SG_ MXB_Z_Fernlicht_R_Anf : 34|1@1+ (1,0) [0|1] ""  BCM1
 SG_ MXB_Z_Fernlicht_R_Schaltart : 35|1@1+ (1,0) [0|1] ""  BCM1

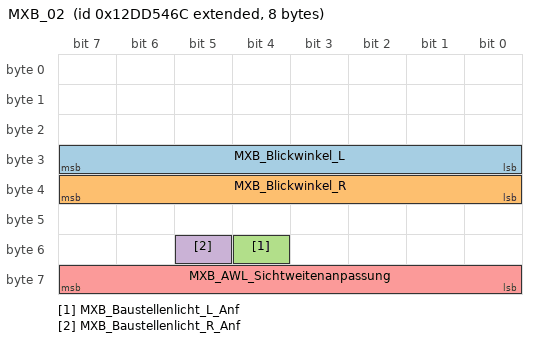
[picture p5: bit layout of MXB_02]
BO_ 2463978604 MXB_02: 8 ZFAS
 SG_ MXB_Blickwinkel_L : 24|8@1+ (0.5,0) [0|90] "Unit_DegreOfArc"  BCM1
 SG_ MXB_Blickwinkel_R : 32|8@1+ (0.5,0) [0|90] "Unit_DegreOfArc"  BCM1
 SG_ MXB_Baustellenlicht_L_Anf : 52|1@1+ (1,0) [0|1] ""  BCM1
 SG_ MXB_Baustellenlicht_R_Anf : 53|1@1+ (1,0) [0|1] ""  BCM1
 SG_ MXB_AWL_Sichtweitenanpassung : 56|8@1+ (2,0) [0|508] "Unit_Meter"  BCM1

BO_ 1358 MXB_Feh_LM_L: 8 LED_DK3_LM_L
 SG_ MXB_L_Fernl_MXB_Def_1 : 0|1@1+ (1,0) [0|1] ""  AFS,FCM,MXB
 SG_ MXB_L_Fernl_MXB_Def_2 : 1|1@1+ (1,0) [0|1] ""  AFS,FCM,MXB
 SG_ MXB_L_Fernl_MXB_Def_3 : 2|1@1+ (1,0) [0|1] ""  AFS,FCM,MXB
 SG_ MXB_L_Fernl_MXB_Def_4 : 3|1@1+ (1,0) [0|1] ""  AFS,FCM,MXB
 SG_ MXB_L_Fernl_MXB_Def_5 : 4|1@1+ (1,0) [0|1] ""  AFS,FCM,MXB
 SG_ MXB_L_Fernl_MXB_Def_6 : 5|1@1+ (1,0) [0|1] ""  AFS,FCM,MXB
 SG_ MXB_L_Fernl_MXB_Def_7 : 6|1@1+ (1,0) [0|1] ""  AFS,FCM,MXB
 SG_ MXB_L_Fernl_MXB_Def_Err_Gultig : 7|1@1+ (1,0) [0|1] ""  AFS,FCM,MXB
 SG_ MXB_L_Allg_Elektr_Def_1 : 8|1@1+ (1,0) [0|1] ""  AFS,FCM,MXB
 SG_ MXB_L_Allg_Elektr_Def_2 : 9|1@1+ (1,0) [0|1] ""  AFS,FCM,MXB
 SG_ MXB_L_Allg_Elektr_Def_3 : 10|1@1+ (1,0) [0|1] ""  AFS,FCM,MXB
 SG_ MXB_L_Allg_Elektr_Def_4 : 11|1@1+ (1,0) [0|1] ""  AFS,FCM,MXB
 SG_ MXB_L_Allg_Elektr_Def_5 : 12|1@1+ (1,0) [0|1] ""  AFS,FCM,MXB
 SG_ MXB_L_Allg_Elektr_Def_6 : 13|1@1+ (1,0) [0|1] ""  AFS,FCM,MXB
 SG_ MXB_L_Allg_Elektr_Def_7 : 14|1@1+ (1,0) [0|1] ""  AFS,FCM,MXB
 SG_ MXB_L_Allg_Elektr_Def_8 : 15|1@1+ (1,0) [0|1] ""  AFS,FCM,MXB
 SG_ MXB_L_Allg_Elektr_Def_Err_Gultig : 16|1@1+ (1,0) [0|1] ""  AFS,FCM,MXB
 SG_ MXB_L_Luefter_1_Def_1 : 17|1@1+ (1,0) [0|1] ""  AFS,FCM,MXB
 SG_ MXB_L_Luefter_1_Def_2 : 18|1@1+ (1,0) [0|1] ""  AFS,FCM,MXB
 SG_ MXB_L_Luefter_1_Def_3 : 19|1@1+ (1,0) [0|1] ""  AFS,FCM,MXB
 SG_ MXB_L_Luefter_1_Def_4 : 20|1@1+ (1,0) [0|1] ""  AFS,FCM,MXB
 SG_ MXB_L_Luefter_2_Def_1 : 21|1@1+ (1,0) [0|1] ""  AFS,FCM,MXB
 SG_ MXB_L_Luefter_2_Def_2 : 22|1@1+ (1,0) [0|1] ""  AFS,FCM,MXB
 SG_ MXB_L_Luefter_2_Def_3 : 23|1@1+ (1,0) [0|1] ""  AFS,FCM,MXB
 SG_ MXB_L_Luefter_2_Def_4 : 24|1@1+ (1,0) [0|1] ""  AFS,FCM,MXB
 SG_ MXB_L_Luefter_1_Def_Err_Gultig : 25|1@1+ (1,0) [0|1] ""  AFS,FCM,MXB
 SG_ MXB_L_Luefter_2_Def_Err_Gultig : 26|1@1+ (1,0) [0|1] ""  AFS,FCM,MXB
 SG_ MXB_L_Allg_Elektr_Def : 27|1@1+ (1,0) [0|1] ""  AFS,BCM1,BVS,FCM,MXB,ZFAS
 SG_ MXB_L_Fernl_MXB_Def : 28|1@1+ (1,0) [0|1] ""  AFS,BCM1,BVS,FCM,MXB,ZFAS

BO_TX_BU_ 404 : AFS,BCM1,FCM,MXB;
BO_TX_BU_ 405 : AFS,BCM1,FCM,MXB;
BO_TX_BU_ 920 : AFS_LMod_L,GLW_LMod_L,LWR_MXB_L;
BO_TX_BU_ 922 : AFS_LMod_R,GLW_LMod_R,LWR_MXB_R;
BO_TX_BU_ 400 : AFS,BCM1,FCM,MXB;
BO_TX_BU_ 406 : AFS_LMod_L,GLW_LMod_L,LCM_L,LLP_L,LWR_MXB_L;
BO_TX_BU_ 408 : AFS_LMod_R,GLW_LMod_R,LCM_R,LLP_R,LWR_MXB_R;
BO_TX_BU_ 958 : AFS,BCM1,FCM,MXB;
BO_TX_BU_ 994 : BVS,ZFAS;
BO_TX_BU_ 1358 : LED_DK3_LM_L,LED_LM_L,LLP_L,LWR_MXB_L,MXB_LM_L;
CM_ SG_ 1389 LED_L_Uspg_Schutz "Stromreduzierung aus Gründen des Unterspannungs-Schutzes in mind. einem der drei Kanäle aktiv";
CM_ SG_ 1389 LED_L_Spannung_KL15 "Klemmenspannung";
CM_ SG_ 1389 LED_L_Spannung_KL56a "Klemmenspannung";
CM_ SG_ 1389 LED_L_Spannung_KL56b "Klemmenspannung";
CM_ SG_ 1389 LED_L_Spannung_TFL "Klemmenspannung";
CM_ SG_ 1389 LED_L_Temp_Schutz "Temperatur-Schutz ";
CM_ SG_ 1389 LED_L_Temp_Mux "Multiplexor zur Umschaltung der verschiedenen Temperaturkanäle";
CM_ SG_ 1389 LED_L_Temp_SG_Intern "Temperaturwert an Hot Spot SG_Intern";
CM_ SG_ 1389 LED_L_Temp_Kanal1_Master "Temperaturwert an Hot Spot Kanal1_Master";
CM_ SG_ 1389 LED_L_Temp_Kanal1_Master2 "Temperaturwert an Hot Spot Kanal1_Master2";
CM_ SG_ 1389 LED_L_Temp_Kanal1_Slave "Temperaturwert an Hot Spot Kanal1_Slave";
CM_ SG_ 1389 LED_L_Temp_Kanal2_Master "Temperaturwert an Hot Spot Kanal2_Master";
CM_ SG_ 1389 LED_L_Temp_Kanal2_Slave "Temperaturwert an Hot Spot Kanal2_Slave";
CM_ SG_ 1389 LED_L_Temp_Kanal3_Master "Temperaturwert an Hot Spot Kanal3_Master";
CM_ SG_ 1389 LED_L_Temp_Kanal3_Slave "Temperaturwert an Hot Spot Kanal3_Slave";
CM_ SG_ 1395 LED_L_Strom_Kanal1_Master "Segment Stromwert";
CM_ SG_ 1395 LED_L_Strom_Kanal1_Master2 "Segment Stromwert";
CM_ SG_ 1395 LED_L_Strom_Kanal1_Slave "Segment Stromwert";
CM_ SG_ 1395 LED_L_Strom_Kanal2_Master "Segment Stromwert";
CM_ SG_ 1395 LED_L_Strom_Kanal2_Slave "Segment Stromwert";
CM_ SG_ 1395 LED_L_Strom_Kanal3_Master "Segment Stromwert";
CM_ SG_ 1395 LED_L_Strom_Kanal3_Slave "Segment Stromwert";
CM_ SG_ 1395 LED_L_Tag_Nacht_Umschaltung_Sta "Status Tag/ Nacht-Umschaltung";
CM_ SG_ 1390 LED_R_Uspg_Schutz "Stromreduzierung aus Gründen des Unterspannungs-Schutzes in mind. einem der drei Kanäle aktiv";
CM_ SG_ 1390 LED_R_Spannung_KL15 "Klemmenspannung";
CM_ SG_ 1390 LED_R_Spannung_KL56a "Klemmenspannung";
CM_ SG_ 1390 LED_R_Spannung_KL56b "Klemmenspannung";
CM_ SG_ 1390 LED_R_Spannung_TFL "Klemmenspannung";
CM_ SG_ 1390 LED_R_Temp_Schutz "Temperatur-Schutz";
CM_ SG_ 1390 LED_R_Temp_Mux "Multiplexor zur Umschaltung der verschiedenen Temperaturkanäle";
CM_ SG_ 1390 LED_R_Temp_SG_Intern "Temperaturwert an Hot Spot SG_Intern";
CM_ SG_ 1390 LED_R_Temp_Kanal1_Master "Temperaturwert an Hot Spot Kanal1_Master";
CM_ SG_ 1390 LED_R_Temp_Kanal1_Master2 "Temperaturwert an Hot Spot Kanal1_Master2";
CM_ SG_ 1390 LED_R_Temp_Kanal1_Slave "Temperaturwert an Hot Spot Kanal1_Slave";
CM_ SG_ 1390 LED_R_Temp_Kanal2_Master "Temperaturwert an Hot Spot Kanal2_Master";
CM_ SG_ 1390 LED_R_Temp_Kanal2_Slave "Temperaturwert an Hot Spot Kanal2_Slave";
CM_ SG_ 1390 LED_R_Temp_Kanal3_Master "Temperaturwert an Hot Spot Kanal3_Master";
CM_ SG_ 1390 LED_R_Temp_Kanal3_Slave "Temperaturwert an Hot Spot Kanal3_Slave";
CM_ SG_ 1396 LED_R_Strom_Kanal1_Master "Segment Stromwert";
CM_ SG_ 1396 LED_R_Strom_Kanal1_Master2 "Segment Stromwert";
CM_ SG_ 1396 LED_R_Strom_Kanal1_Slave "Segment Stromwert";
CM_ SG_ 1396 LED_R_Strom_Kanal2_Master "Segment Stromwert";
CM_ SG_ 1396 LED_R_Strom_Kanal2_Slave "Segment Stromwert";
CM_ SG_ 1396 LED_R_Strom_Kanal3_Master "Segment Stromwert";
CM_ SG_ 1396 LED_R_Strom_Kanal3_Slave "Segment Stromwert";
CM_ SG_ 1396 LED_R_Tag_Nacht_Umschaltung_Sta "Status Tag/ Nacht-Umschaltung";
CM_ SG_ 2589283616 LED_R_DABL_LED_01_Anf "LED PWM Ansteuerung
Die Skalierung erfolgt von 0% - 100%  je nach Kennlinie im LEIMO";
CM_ SG_ 2589283616 LED_R_DABL_LED_02_Anf "LED PWM Ansteuerung
Die Skalierung erfolgt von 0% - 100%  je nach Kennlinie im LEIMO";
CM_ SG_ 2589283616 LED_R_DABL_LED_03_Anf "LED PWM Ansteuerung
Die Skalierung erfolgt von 0% - 100%  je nach Kennlinie im LEIMO";
CM_ SG_ 2589283616 LED_R_DABL_LED_04_Anf "LED PWM Ansteuerung
Die Skalierung erfolgt von 0% - 100%  je nach Kennlinie im LEIMO";
CM_ SG_ 2589283616 LED_R_DABL_LED_05_Anf "LED PWM Ansteuerung
Die Skalierung erfolgt von 0% - 100%  je nach Kennlinie im LEIMO";
CM_ SG_ 2589283616 LED_R_DABL_LED_06_Anf "LED PWM Ansteuerung
Die Skalierung erfolgt von 0% - 100%  je nach Kennlinie im LEIMO";
CM_ SG_ 2589283616 LED_R_DABL_LED_07_Anf "LED PWM Ansteuerung
Die Skalierung erfolgt von 0% - 100%  je nach Kennlinie im LEIMO";
CM_ SG_ 2589283616 LED_R_DABL_LED_08_Anf "LED PWM Ansteuerung
Die Skalierung erfolgt von 0% - 100%  je nach Kennlinie im LEIMO";
CM_ SG_ 2589283616 LED_R_DABL_LED_09_Anf "LED PWM Ansteuerung
Die Skalierung erfolgt von 0% - 100%  je nach Kennlinie im LEIMO";
CM_ SG_ 2589283616 LED_R_DABL_LED_10_Anf "LED PWM Ansteuerung
Die Skalierung erfolgt von 0% - 100%  je nach Kennlinie im LEIMO";
CM_ SG_ 2463978601 LED_R_DABL_LED_11_Anf "LED PWM Ansteuerung
Die Skalierung erfolgt von 0% - 100%  je nach Kennlinie im LEIMO";
CM_ SG_ 2463978601 LED_R_DABL_LED_12_Anf "LED PWM Ansteuerung
Die Skalierung erfolgt von 0% - 100%  je nach Kennlinie im LEIMO";
CM_ SG_ 2463978601 LED_R_DABL_LED_13_Anf "LED PWM Ansteuerung
Die Skalierung erfolgt von 0% - 100%  je nach Kennlinie im LEIMO";
CM_ SG_ 2463978601 LED_R_DABL_LED_14_Anf "LED PWM Ansteuerung
Die Skalierung erfolgt von 0% - 100%  je nach Kennlinie im LEIMO";
CM_ SG_ 2463978601 LED_R_DABL_LED_15_Anf "LED PWM Ansteuerung
Die Skalierung erfolgt von 0% - 100%  je nach Kennlinie im LEIMO";
CM_ SG_ 2463978601 LED_R_DABL_LED_16_Anf "LED PWM Ansteuerung
Die Skalierung erfolgt von 0% - 100%  je nach Kennlinie im LEIMO";
CM_ SG_ 2463978601 LED_R_DABL_LED_17_Anf "LED PWM Ansteuerung
Die Skalierung erfolgt von 0% - 100%  je nach Kennlinie im LEIMO";
CM_ SG_ 2463978601 LED_R_DABL_LED_18_Anf "LED PWM Ansteuerung
Die Skalierung erfolgt von 0% - 100%  je nach Kennlinie im LEIMO";
CM_ SG_ 2463978601 LED_R_DABL_LED_19_Anf "LED PWM Ansteuerung
Die Skalierung erfolgt von 0% - 100%  je nach Kennlinie im LEIMO";
CM_ SG_ 2463978601 LED_R_DABL_LED_20_Anf "LED PWM Ansteuerung
Die Skalierung erfolgt von 0% - 100%  je nach Kennlinie im LEIMO";
CM_ SG_ 837 LED_R_SABL_LED_01_Anf "LED PWM Ansteuerung
Die Skalierung erfolgt von 0% - 100%  je nach Kennlinie im LEIMO";
CM_ SG_ 837 LED_R_SABL_LED_02_Anf "LED PWM Ansteuerung
Die Skalierung erfolgt von 0% - 100%  je nach Kennlinie im LEIMO";
CM_ SG_ 837 LED_R_SABL_LED_03_Anf "LED PWM Ansteuerung
Die Skalierung erfolgt von 0% - 100%  je nach Kennlinie im LEIMO";
CM_ SG_ 837 LED_R_SABL_LED_04_Anf "LED PWM Ansteuerung
Die Skalierung erfolgt von 0% - 100%  je nach Kennlinie im LEIMO";
CM_ SG_ 837 LED_R_SABL_LED_05_Anf "LED PWM Ansteuerung
Die Skalierung erfolgt von 0% - 100%  je nach Kennlinie im LEIMO";
CM_ SG_ 837 LED_R_SABL_LED_06_Anf "LED PWM Ansteuerung
Die Skalierung erfolgt von 0% - 100%  je nach Kennlinie im LEIMO";
CM_ SG_ 837 LED_R_SABL_LED_07_Anf "LED PWM Ansteuerung
Die Skalierung erfolgt von 0% - 100%  je nach Kennlinie im LEIMO";
CM_ SG_ 837 LED_R_SABL_LED_08_Anf "LED PWM Ansteuerung
Die Skalierung erfolgt von 0% - 100%  je nach Kennlinie im LEIMO";
CM_ SG_ 837 LED_R_SABL_LED_09_Anf "LED PWM Ansteuerung
Die Skalierung erfolgt von 0% - 100%  je nach Kennlinie im LEIMO";
CM_ SG_ 837 LED_R_SABL_LED_10_Anf "LED PWM Ansteuerung
Die Skalierung erfolgt von 0% - 100%  je nach Kennlinie im LEIMO";
CM_ SG_ 404 LED_L_Abblendl_Anf "Abblendlicht-Anforderung";
CM_ SG_ 404 LED_L_Abblendl_Schaltart "Signal entscheidet, ob Abblendlicht gedimmt oder unmittelbar ein- bzw. ausgeschaltet wird
(Eine eventuelle Dimmung ist im LED-LM abzulegen)";
CM_ SG_ 404 LED_R_Abblendl_Anf "Abblendlicht-Anforderung";
CM_ SG_ 404 LED_R_Abblendl_Schaltart "Signal entscheidet, ob Abblendlicht gedimmt oder unmittelbar ein- bzw. ausgeschaltet wird
(Eine eventuelle Dimmung ist im LED-LM abzulegen)";
CM_ SG_ 404 LED_L_Fernl_LH_Schaltart "Signal entscheidet, ob Fernlicht gedimmt oder unmittelbar ein- bzw. ausgeschaltet wird (Eine eventuelle Dimmung ist im LED-LM abzulegen)";
CM_ SG_ 404 LED_R_Fernl_LH_Schaltart "Signal entscheidet, ob Fernlicht gedimmt oder unmittelbar ein- bzw. ausgeschaltet wird (Eine eventuelle Dimmung ist im LED-LM abzulegen)";
CM_ SG_ 404 LED_Sta_Diag "1010: Normalbetrieb: Diagnose nicht eingeleitet. Eine Umcodierung, Stellgliedtest, und Fehlerspeicherlöschen der Slaves ist über diese Bitreihenfolge verriegelt!
0101: Diagnosebetrieb. Diagnose mit VAS Tester läuft. Ein Stellgliedtest, und Fehlerspeicher";
CM_ SG_ 404 LED_L_Zus_Fernl_LH_Anf "Anforderung LED Zusatzfernlicht links ";
CM_ SG_ 404 LED_L_Zus_Fernl_LH_Schaltart "Signal entscheidet, ob Fernlicht gedimmt oder unmittelbar ein- bzw. ausgeschaltet wird (Eine eventuelle Dimmung ist im LED-LM abzulegen)";
CM_ SG_ 404 LED_R_Zus_Fernl_LH_Anf "Anforderung LED Zusatzfernlicht rechts";
CM_ SG_ 404 LED_R_Zus_Fernl_LH_Schaltart "Signal entscheidet, ob Fernlicht gedimmt oder unmittelbar ein- bzw. ausgeschaltet wird (Eine eventuelle Dimmung ist im LED-LM abzulegen)";
CM_ SG_ 405 LED_L_Eco_Mode_1_Anf "Anforderung Eco-Mode, d. h. einer gedimmten Ansteuerung des Abblendlichtes (anhand im LED_LM_L/R hinterlegter Dimmwerte)";
CM_ SG_ 405 LED_L_Eco_Mode_1_Schaltart "LED_LM_L (Abblendlicht), LED_LM_R (Abblendlicht)";
CM_ SG_ 405 LED_R_Eco_Mode_1_Anf "Anforderung Eco-Mode, d. h. einer gedimmten Ansteuerung des Abblendlichtes (anhand im LED_LM_L/R hinterlegter Dimmwerte)";
CM_ SG_ 405 LED_R_Eco_Mode_1_Schaltart "LED_LM_L (Abblendlicht), LED_LM_R (Abblendlicht)";
CM_ SG_ 405 LED_L_Eco_Mode_2_Anf "Anforderung Eco-Mode, d. h. einer gedimmten Ansteuerung des Abblendlichtes (anhand im LED_LM_L/R hinterlegter Dimmwerte)";
CM_ SG_ 405 LED_L_Eco_Mode_2_Schaltart "LED_LM_L (Abblendlicht), LED_LM_R (Abblendlicht)";
CM_ SG_ 405 LED_R_Eco_Mode_2_Anf "Anforderung Eco-Mode, d. h. einer gedimmten Ansteuerung des Abblendlichtes (anhand im LED_LM_L/R hinterlegter Dimmwerte)";
CM_ SG_ 405 LED_R_Eco_Mode_2_Schaltart "LED_LM_L (Abblendlicht), LED_LM_R (Abblendlicht)";
CM_ SG_ 405 LED_L_TFL_Schaltart "LED_LM_L (Abblendlicht), LED_LM_R (Abblendlicht)";
CM_ SG_ 405 LED_R_TFL_Schaltart "LED_LM_L (Abblendlicht), LED_LM_R (Abblendlicht)";
CM_ SG_ 405 LED_L_Touristenl_Schaltart "Signal entscheidet, ob Touristenlicht gedimmt oder unmittelbar ein- bzw. ausgeschaltet wird
(Eine eventuelle Dimmung ist im LED-LM abzulegen)";
CM_ SG_ 405 LED_R_Touristenl_Schaltart "Signal entscheidet, ob Touristenlicht gedimmt oder unmittelbar ein- bzw. ausgeschaltet wird
(Eine eventuelle Dimmung ist im LED-LM abzulegen)";
CM_ SG_ 405 LED_Tag_Nacht_Umschaltung_Anf "Anforderung Tag/Nacht-Umschaltung";
CM_ SG_ 405 LED_Sta_Diag "1010: Normalbetrieb: Diagnose nicht eingeleitet. Eine Umcodierung, Stellgliedtest, und Fehlerspeicherlöschen der Slaves ist über diese Bitreihenfolge verriegelt!
0101: Diagnosebetrieb. Diagnose mit VAS Tester läuft. Ein Stellgliedtest, und Fehlerspeicher";
CM_ SG_ 405 LED_L_Abbiegel_Dimmung "Dimmung des linken Abbiegelichtes in %PWM, bezogen auf die Versorgungsspannung";
CM_ SG_ 405 LED_R_Abbiegel_Dimmung "Dimmung des rechten Abbiegelichtes in %PWM, bezogen auf die Versorgungsspannung";
CM_ SG_ 351 LED_Soll_Fkt2_CRC "Checksumme für Botschaft LED_Soll_Fkt2 auf FL-CAN";
CM_ SG_ 351 LED_Soll_Fkt2_BZ "Botschaftszähler für LED_Soll_Fkt2-Botschaft auf FL-CAN";
CM_ SG_ 351 LED_L_Abblendl_Anf "Abblendlicht-Anforderung";
CM_ SG_ 351 LED_L_Abblendl_Schaltart "Signal entscheidet, ob Abblendlicht gedimmt oder unmittelbar ein- bzw. ausgeschaltet wird
(Eine eventuelle Dimmung ist im LED-LM abzulegen)";
CM_ SG_ 351 LED_R_Abblendl_Anf "Abblendlicht-Anforderung";
CM_ SG_ 351 LED_R_Abblendl_Schaltart "Signal entscheidet, ob Abblendlicht gedimmt oder unmittelbar ein- bzw. ausgeschaltet wird
(Eine eventuelle Dimmung ist im LED-LM abzulegen)";
CM_ SG_ 351 LED_L_Fernl_LH_Schaltart "Signal entscheidet, ob Fernlicht gedimmt oder unmittelbar ein- bzw. ausgeschaltet wird (Eine eventuelle Dimmung ist im LED-LM abzulegen)";
CM_ SG_ 351 LED_R_Fernl_LH_Schaltart "Signal entscheidet, ob Fernlicht gedimmt oder unmittelbar ein- bzw. ausgeschaltet wird (Eine eventuelle Dimmung ist im LED-LM abzulegen)";
CM_ SG_ 351 LED_Sta_Diag "1010: Normalbetrieb: Diagnose nicht eingeleitet. Eine Umcodierung, Stellgliedtest, und Fehlerspeicherlöschen der Slaves ist über diese Bitreihenfolge verriegelt!
0101: Diagnosebetrieb. Diagnose mit VAS Tester läuft. Ein Stellgliedtest, und Fehlerspeicher";
CM_ SG_ 351 LED_L_Zus_Fernl_LH_Anf "Anforderung LED Zusatzfernlicht links ";
CM_ SG_ 351 LED_L_Zus_Fernl_LH_Schaltart "Signal entscheidet, ob Fernlicht gedimmt oder unmittelbar ein- bzw. ausgeschaltet wird (Eine eventuelle Dimmung ist im LED-LM abzulegen)";
CM_ SG_ 351 LED_R_Zus_Fernl_LH_Anf "Anforderung LED Zusatzfernlicht rechts";
CM_ SG_ 351 LED_R_Zus_Fernl_LH_Schaltart "Signal entscheidet, ob Fernlicht gedimmt oder unmittelbar ein- bzw. ausgeschaltet wird (Eine eventuelle Dimmung ist im LED-LM abzulegen)";
CM_ SG_ 351 BCM1_CH_aktiv "Coming Home (zusätzlich zum Signal 'BCM1_CH_LH_aktiv' in der Botschaft BCM1_01)";
CM_ SG_ 351 BCM1_LH_aktiv "Leaving Home (zusätzlich zum Signal 'BCM1_CH_LH_aktiv' in der Botschaft BCM1_01)";
CM_ SG_ 920 FLL_SchMot "Kurzschluss nach Plus
Offene Leitung
Kurzschluß gegeneinander";
CM_ SG_ 920 FLL_RSchMot "Das Readyness-Bit dient als Indikator dafür, das der Fehlerbaum sauber durchlaufen wurde. Erst beim Setzen des Readyness-Bits auf '0' wird das dazugehörige Fehlerbit gesetzt";
CM_ SG_ 920 FLL_SM_KS_Gnd "Kurzschluss nach Masse";
CM_ SG_ 920 FLL_RSM_KS_Gnd "Das Readyness-Bit dient als Indikator dafür, das der Fehlerbaum sauber durchlaufen wurde. Erst beim Setzen des Readyness-Bits auf '0' wird das dazugehörige Fehlerbit gesetzt";
CM_ SG_ 920 FLL_SM_UeSpg "Abschaltung Schrittmotor Überspannung";
CM_ SG_ 920 FLL_RSM_UeSpg "Das Readyness-Bit dient als Indikator dafür, das der Fehlerbaum sauber durchlaufen wurde. Erst beim Setzen des Readyness-Bits auf '0' wird das dazugehörige Fehlerbit gesetzt";
CM_ SG_ 920 FLL_SM_USpg "Abschaltung Schrittmotor Unterspannung";
CM_ SG_ 920 FLL_RSM_USpg "Das Readyness-Bit dient als Indikator dafür, das der Fehlerbaum sauber durchlaufen wurde. Erst beim Setzen des Readyness-Bits auf '0' wird das dazugehörige Fehlerbit gesetzt";
CM_ SG_ 920 FLL_SM_UeTemp "Abschaltung Schrittmotor Übertemperatur";
CM_ SG_ 920 FLL_RSM_UeTemp "Das Readyness-Bit dient als Indikator dafür, das der Fehlerbaum sauber durchlaufen wurde. Erst beim Setzen des Readyness-Bits auf '0' wird das dazugehörige Fehlerbit gesetzt";
CM_ SG_ 920 FLL_SM_TempPre "Abschaltung Schrittmotor Übertemperatur";
CM_ SG_ 920 FLL_RSM_TempPre "Das Readyness-Bit dient als Indikator dafür, das der Fehlerbaum sauber durchlaufen wurde. Erst beim Setzen des Readyness-Bits auf '0' wird das dazugehörige Fehlerbit gesetzt";
CM_ SG_ 920 FLL_AFS_Unpl "KL. 15 Überspannung
(eingeschränkte Funktion, aber AFS-CAN läuft!)
siehe VW 801/01";
CM_ SG_ 920 FLL_RAFS_Unpl "Das Readyness-Bit dient als Indikator dafür, das der Fehlerbaum sauber durchlaufen wurde. Erst beim Setzen des Readyness-Bits auf '0' wird das dazugehörige Fehlerbit gesetzt";
CM_ SG_ 922 FLR_SchMot "Kurzschluss nach Plus
Offene Leitung
Kurzschluß gegeneinander";
CM_ SG_ 922 FLR_RSchMot "Das Readyness-Bit dient als Indikator dafür, das der Fehlerbaum sauber durchlaufen wurde. Erst beim Setzen des Readyness-Bits auf '0' wird das dazugehörige Fehlerbit gesetzt";
CM_ SG_ 922 FLR_SM_KS_Gnd "Kurzschluss nach Masse";
CM_ SG_ 922 FLR_RSM_KS_Gnd "Das Readyness-Bit dient als Indikator dafür, das der Fehlerbaum sauber durchlaufen wurde. Erst beim Setzen des Readyness-Bits auf '0' wird das dazugehörige Fehlerbit gesetzt";
CM_ SG_ 922 FLR_SM_UeSpg "Abschaltung Schrittmotor Überspannung";
CM_ SG_ 922 FLR_RSM_UeSpg "Das Readyness-Bit dient als Indikator dafür, das der Fehlerbaum sauber durchlaufen wurde. Erst beim Setzen des Readyness-Bits auf '0' wird das dazugehörige Fehlerbit gesetzt";
CM_ SG_ 922 FLR_SM_USpg "Abschaltung Schrittmotor Überspannung";
CM_ SG_ 922 FLR_RSM_USpg "Das Readyness-Bit dient als Indikator dafür, das der Fehlerbaum sauber durchlaufen wurde. Erst beim Setzen des Readyness-Bits auf '0' wird das dazugehörige Fehlerbit gesetzt";
CM_ SG_ 922 FLR_SM_UeTemp "Abschaltung Schrittmotor Übertemperatur";
CM_ SG_ 922 FLR_RSM_UeTemp "Das Readyness-Bit dient als Indikator dafür, das der Fehlerbaum sauber durchlaufen wurde. Erst beim Setzen des Readyness-Bits auf '0' wird das dazugehörige Fehlerbit gesetzt";
CM_ SG_ 922 FLR_SM_TempPre "Abschaltung Schrittmotor Übertemperatur";
CM_ SG_ 922 FLR_RSM_TempPre "Das Readyness-Bit dient als Indikator dafür, das der Fehlerbaum sauber durchlaufen wurde. Erst beim Setzen des Readyness-Bits auf '0' wird das dazugehörige Fehlerbit gesetzt";
CM_ SG_ 922 FLR_AFS_Unpl "KL. 15 Überspannung
(eingeschränkte Funktion, aber AFS-CAN läuft!)
siehe VW 801/01";
CM_ SG_ 922 FLR_RAFS_Unpl "Das Readyness-Bit dient als Indikator dafür, das der Fehlerbaum sauber durchlaufen wurde. Erst beim Setzen des Readyness-Bits auf '0' wird das dazugehörige Fehlerbit gesetzt";
CM_ SG_ 400 SOL_SollPos_L "Sollneigung in [mm] des linken Abblendlichtbündels in 10 m Entfernung bezogen auf die Grundeinstellung des Abblendlichtes (-1,0% Neigung am leeren Fahrzeug)
z.B. 0 mm heißt -1,0% Neigung des Abblendlichtbündels (Änderung des Wertebereichs)
negatives Vor";
CM_ SG_ 400 SOL_FehlPos_L "LWR Fehlerfallposition des linken Schrittmotors
Fehlerposition bei 'Bus Off' -200 mm";
CM_ SG_ 400 SOL_RefLauf_L "Referenzlauf des linken Schrittmotors
[erfolgt defaultmäßig beim Motorstart]
(Exakte Position siehe: 'Sollposition LWR Schrittmotor')";
CM_ SG_ 400 SOL_StGlTest_L "(Exakte Position siehe: 'Sollposition LWR Schrittmotor')";
CM_ SG_ 400 SOL_Fehlloesch_L "Aufforderung zum Fehlerspeicher löschen im linken AFS Elektronik Modul!";
CM_ SG_ 400 MO_StartStopp_Motorstopp "Motor-Stopp durch Start/Stopp-Koordinator
HYBRID:
Wenn MO_Hybridfahrzeug = 1 gilt:
Verbrennungsmotor durch Hybrid-Koordinator im MSG ausgeschaltet. 
Die definierten Start/Stopp-Signale beziehen sich nur auf den Verbrennungsmotor!";
CM_ SG_ 400 MO_StartStopp_Wiederstart "Motorwiederstart durch Start/Stopp-Koordinator
HYBRID:
Wenn MO_Hybridfahrzeug =1 gilt:
Warnung vor Spannungseinbruch beim Zustart des Verbrennungsmotors. 
-nicht relevant, da derzeit kein Start über 12V-Starter geplant-
Dieses Signal wird nur vom Hyb";
CM_ SG_ 400 SOL_Tieftemp_Flag "Dieses Bit wird bei einer über das Bordnetz gemessenen Außentemperatur kleiner als -30°C auf den Wert '1' gesetzt";
CM_ SG_ 400 SOL_SollPos_R "Sollneigung in [mm] des rechten Abblendlichtbündels in 10 m Entfernung bezogen auf die Grundeinstellung des Abblendlichtes (-1,0% Neigung am leeren Fahrzeug)
z.B. 0 mm heißt -1,0% Neigung des Abblendlichtbündels (Änderung des Wertebereichs)
negatives Vo";
CM_ SG_ 400 SOL_FehlPos_R "LWR Fehlerfallposition des rechten Schrittmotors";
CM_ SG_ 400 SOL_RefLauf_R "Referenzlauf des rechten Schrittmotors
[erfolgt defaultmäßig beim Motorstart]
(Exakte Position siehe: 'Sollposition LWR Schrittmotor')";
CM_ SG_ 400 SOL_StGlTest_R "(Exakte Position siehe: 'Sollposition LWR Schrittmotor')";
CM_ SG_ 400 SOL_Fehlloesch_R "Aufforderung zum Fehlerspeicher löschen im rechten AFS Elektronik Modul!";
CM_ SG_ 400 SOL_Sta_Diag "1010: Normalbetrieb: Diagnose nicht eingeleitet. Eine Umcodierung, Stellgliedtest, und Fehlerspeicherlöschen der Slaves ist über diese Bitreihenfolge verriegelt!
0101: Diagnosebetrieb. Diagnose mit VAS Tester läuft. Ein Stellgliedtest, und Fehlerspeicher";
CM_ SG_ 406 SLL_IstPos "Istneigung des linken Abblendlichtbündels in 10 m Entfernung bezogen auf die Grundeinstellung des Abblendlichtes (-1,0% Neigung am leeren Fahrzeug)
z.B. 0 mm heißt -1,0% Neigung des Abblendlichtbündels
negatives Vorzeichen entspricht Richtung Abblenden";
CM_ SG_ 406 SLL_StaStStWiederstart "gespiegeltes Bit aus der Sollbotschaft:
Der Slave muss die Soll-Information unabhängig von diesem Bit unterstützen.
Master wertet dieses Bit nicht aus!";
CM_ SG_ 406 SLL_StaStStMotorstopp "gespiegeltes Bit aus der Sollbotschaft:
Der Slave muss die Soll-Information unabhängig von diesem Bit unterstützen.
Master wertet dieses Bit nicht aus!";
CM_ SG_ 406 SLL_IstPosMot "Position des Aktuators in Prozent des maximalen Stellweges;
vor dem Initialisierungslauf (z.Zt. Motorstart) wird der Initwert ausgegeben
0% ist tiefste Position (auf Block) des Schrittmotors
100% maximaler Verstellweg des Schrittmotors (nicht die Grenz";
CM_ SG_ 406 SLL_StaReflauf "(Nach erfolgtem Referenzlauf wird Zustand '1' eingenommen.)";
CM_ SG_ 406 SLL_BestFehlosch "Der Fehlerspeicher im linken AFS-Leistungs-Modul wurde gelöscht!";
CM_ SG_ 406 SLL_StaAFSElMod "Betrieb mit reduzierter Verstellgeschwindigkeit für LWR und AFS wegen Unterspannung oder Übertemperatur (dies ist kein Fehler-BIT!)";
CM_ SG_ 406 SLL_StaTieftempFlag "Bei gesetztem Flag unterstützt der Slave die Funktion und die Funktion ist gerade aktiv.
(z.B. Stromerhöhung, um den Anlauf der Schrittmotoren zu verbessern)";
CM_ SG_ 408 SLR_IstPos "Istneigung des rechten Abblendlichtbündels in 10 m Entfernung bezogen auf die Grundeinstellung des Abblendlichtes (-1,0% Neigung am leeren Fahrzeug)
z.B. 0 mm heißt -1,0% Neigung des Abblendlichtbündels
negatives Vorzeichen entspricht Richtung Abblenden";
CM_ SG_ 408 SLR_StaStStWiederstart "gespiegeltes Bit aus der Sollbotschaft:
Der Slave muss die Soll-Information unabhängig von diesem Bit unterstützen.
Master wertet dieses Bit nicht aus!";
CM_ SG_ 408 SLR_StaStStMotorstopp "gespiegeltes Bit aus der Sollbotschaft:
Der Slave muss die Soll-Information unabhängig von diesem Bit unterstützen.
Master wertet dieses Bit nicht aus!";
CM_ SG_ 408 SLR_IstPosMot "Position des Aktuators in Prozent des maximalen Stellweges;
vor dem Initialisierungslauf (z.Zt. Motorstart) wird der Initwert ausgegeben
0% ist tiefste Position (auf Block) des Schrittmotors
100% maximaler Verstellweg des Schrittmotors (nicht die Grenz";
CM_ SG_ 408 SLR_StaReflauf "(Nach erfolgtem Referenzlauf wird Zustand '1' eingenommen.)";
CM_ SG_ 408 SLR_BestFehlosch "Der Fehlerspeicher im rechten AFS-Leistungs-Modul wurde gelöscht!";
CM_ SG_ 408 SLR_StaAFSElMod "Betrieb mit reduzierter Verstellgeschwindigkeit für LWR und AFS wegen Unterspannung oder Übertemperatur (dies ist kein Fehler-BIT!)";
CM_ SG_ 408 SLR_StaTieftempFlag "Bei gesetztem Flag unterstützt der Slave die Funktion und die Funktion ist gerade aktiv.
(z.B. Stromerhöhung, um den Anlauf der Schrittmotoren zu verbessern)";
CM_ SG_ 958 Motor_14_CRC "Ab MQB und MLBevo:
'Berechnung siehe Lastenheft 'End-to-End Kommunikationsabsicherung'

Endwerte siehe Begleitdokument 'S-PDU Kennungsfolgen'";
CM_ SG_ 958 MO_StartStopp_Status "Aktivitätsstatus Start/Stopp-Koordinator
HYBRID:
Wenn MO_Hybridfahrzeug = 1 gilt:
Signal bezieht sich nur auf den Verbrennungsmotor, nicht auf den Hybridantrieb
";
CM_ SG_ 958 MO_StartStopp_Wiederstart "Motorwiederstart durch Start/Stopp-Koordinator
HYBRID:
Wenn MO_Hybridfahrzeug =1 gilt:
Warnung vor Spannungseinbruch beim Zustart des Verbrennungsmotors. 
-nicht relevant, da derzeit kein Start über 12V-Starter geplant-
Dieses Signal wird nur vom Hyb";
CM_ SG_ 958 MO_StartStopp_Motorstopp "Motor-Stopp durch Start/Stopp-Koordinator
HYBRID:
Wenn MO_Hybridfahrzeug = 1 gilt:
Verbrennungsmotor durch Hybrid-Koordinator im MSG ausgeschaltet. 
Die definierten Start/Stopp-Signale beziehen sich nur auf den Verbrennungsmotor!";
CM_ SG_ 958 MO_Freig_Reku "Empfehlung des Motor-SG's zur Spannungsabsenkung/-anhebung für den Rekuperationsbetrieb";
CM_ SG_ 958 MO_Kl_75 "Klemme X
";
CM_ SG_ 958 MO_Kl_50 "Klemme 50: Startausführung

MLB: nicht von allen Motoren gesendet
MQB/MLBevo: gesendet von allen Motoren ";
CM_ SG_ 958 MO_Gangposition "MLB:
Stellung des Wählhebels in der Schaltgasse des Handschaltgetriebes.
MLBevo: 
Ausweitung der Bedienung auch auf Automatikgetriebe;
Routing des Signals GE_Fahrstufe: 
1. Position_R (dez. 6) auf MO_Gangposition: Gang_R (dez. 13) wegen Entfall Signa";
CM_ SG_ 958 MO_StartStopp_Fahrerwunsch "Fahreraktivität Start/Stop";
CM_ SG_ 958 MO_HYB_Fahrbereitschaft "Signal steuert u.a. in der Lenkhilfe zusammen mit weiteren Informationen den Modewechsel in den 'Drivemode'
Grüne Anzeige im Kombiinstrument zur Signalisierung der Bereitschaft des Hybridsystems.";
CM_ SG_ 958 MO_Ext_E_Fahrt_aktiv "Funktionsrückmeldung zum erw. E-Fahr-Betrieb über Lampe/LED im E-Mode-Taster";
CM_ SG_ 958 MO_Fahrer_bremst "Redundante Bremsinformation vom Motor.

MLB:
AUDI D4: Zykluszeit: 10ms (siehe Zykluszeit schnell/Cycletime Fast)
Im AUDI B8 wird in diesem Bit der Wert der ESP-CAN-Information 'ESP_Fahrer_bremst' ausgegeben.

Achtung:
Reduktion der Zykluszeit Motor";
CM_ SG_ 958 MO_QBit_Fahrer_bremst "MLB:
AUDI D4: Zykluszeit: 10ms (siehe Zykluszeit schnell/Cycletime Fast)

Achtung:
Reduktion der Zykluszeit Motor_03 auf 10ms geplant.
Projektabhängig soll künftig mit 10ms gesendet werden.
Empfänger die in weiteren Konzern-Projekten eingesetzt werd";
CM_ SG_ 958 MO_BLS "Ungefiltertes Rohsignal des Bremslichtschalters, nur wenn HW-Eingang bestückt und ausgewertet wird. Bei Motoren ohne genutzten HW-Eingang wird kein Ersatzwert (bspw. SW-Signal über CAN) ausgegeben!
Bei AUDI muss das Signal wg. Bremslichtfunktion immer be";
CM_ SG_ 958 MO_Konsistenz_Bremsped "MLB:

AUDI D4: Zykluszeit: 10ms (siehe Zykluszeit schnell/Cycletime Fast)
Siehe 'Funktionsspezifikation Bremslichtinfo B8'

Achtung:
Reduktion der Zykluszeit Motor_03 auf 10ms geplant.
Projektabhängig soll künftig mit 10ms gesendet werden.
Empfäng";
CM_ SG_ 958 MO_KomFehler_ESP "Anzeige Kommunikationsfehler bei Empfang vom ESP";
CM_ SG_ 958 MO_Klima_Eingr "Eingriffe des Motor bei der Klima";
CM_ SG_ 958 MO_Aussp_Anlass "Das Signal zeigt an, ob die Wiederholstartsperre aktiv ist. D. h. eine Ansteuerung des Anlassers wird auch bei erfüllten Startvoraussetzungen (HS: Interlock betätigt bzw. AT: P/N eingelegt und Bremse betätigt) nicht erfolgen.";
CM_ SG_ 958 MO_Freig_Anlass "Bit wird gesetzt, wenn der Motor beim Automatikstart gestartet werden darf (Motorstillstand, Emissionsmaßnahmen sind erfüllt).";
CM_ SG_ 958 MO_Kuppl_schalter "MLB:
Das Motorsteuergerät gibt die Information aus, ab wann der Kupplungsschalter durch das Motorsteuergerät als getreten gesehen wird
0x0: Schalter sagt betätigt (Ausgekuppelt)
0x1: Schalter sagt nicht betätigt (Eingekuppelt)

MQB:
Nur Handschalter";
CM_ SG_ 958 MO_Interlock "Das Motorsteuergerät gibt die Information aus, ab wann der Kupplungsschalter durch das Motorsteuergerät als getreten gesehen wird.
Bei Systemen für Start Stopp muss das Interlocksignal für einen Start durch das MSG generiert werden, sobald der Schalthebe";
CM_ SG_ 958 MO_Motor_laeuft "Das Motorsteuergerät gibt die Information aus, ab wann der Motor verbrennungsbedingt autark läuft und durch zuschaltbare Nebenaggregate mechanisch belastbar ist (z.B. durch Generator, Klimakompressor, etc.).

Die 'Motor läuft' Information wird ausgegebe";
CM_ SG_ 958 MO_Kickdown "Es gilt: Signalspec MO_Kickdown v1.0";
CM_ SG_ 958 MO_QBit_KL_75 "Q - Bit für das KL 75 Signal zur Vermeidung der fehlerhaften Erkennung von Motorstarts. 
Wird auf 1 gesetzt, solange das Motorsteuergerät KL15 = AUS erkannt hat.";
CM_ SG_ 958 MO_EKlKomLeiRed "Anforderung an die Klimasteuerung, die Leistungsaufnahme des E-Kompressors bei schlechtem SOC und in bestimmten Fahrsituationen zu begrenzen. (Das bereits bestehende Signal 'Klimakompressor aus' als stets umzusetzende Anforderung bleibt unverändert besteh";
CM_ SG_ 958 MO_Handshake_STH "Es gilt: Signalspec MO_Handshake v1.0

Handshake zwischen MSG und STH. Wenn das MSG die EKP aufgrund einer STH-Anforderung ansteuert und kein Fehlereintrag bzgl. EKP/KPE/NDR vorliegt, wird das Bit gesetzt.";
CM_ SG_ 958 MO_BKV_Unterdruckwarnung "Über die Unterdruckwarnung signalisiert das MSG dem ESP, dass kein ausreichender Unterdruck für den BKV zur Verfügung gestellt werden kann.";
CM_ SG_ 958 MO_Freigabe_Segeln "Freigabebit des Segelbetriebs im Getriebe. Bedingt durch bestimmte Diagnosen und Adaptionen des MSGs, die nur im Schub möglich sind, darf nicht jede Schubphase für einen Segelbetrieb genutzt werden. Eine Freigabe bleibt auch außerhalb einer Schubphase bes";
CM_ SG_ 958 MO_PTC_Status "Status-Rückmeldung vom MSG zum aktuellen PTC-Status (stufiges PTC, Relais am MSG). Bei Ansteuerung eines stufigen PTC durch ein anderes SG beschreibt das Signal die vom MSG freigegebene PTC-Stufe.";
CM_ SG_ 958 MO_QBit_Gangposition "Qualitätsbit zum Signal MO_Gangposition";
CM_ SG_ 958 MO_Signalquelle_Gangposition "Signalquelle des Signals MO_Gangposition
0: Signalquelle Gangpositionssensor
1: Signalquelle Modellwert (v/n)";
CM_ SG_ 958 MO_Remotestart_Betrieb "Das MSG ist für den Remotestart-Betrieb bereit. Nach Empfang der Motorstartanforderung für RSt-Betrieb durch BCM wird der Fahrzeugmotor gestartet und solange der Motor läuft, bleibt dieses Bit aktiv. Dieses Signal ist nur zur Verwendung durch das BCM zur ";
CM_ SG_ 958 MO_Remotestart_moeglich "Wenn Bit gesetzt, würde das MSG bei entsprechender Anforderung durch das BCM den Remotestartbetrieb einleiten, d.h. das MSG ist remotestartfähig und es liegen aktuell keine relevanten Fehler oder andere Abbruchgründe vor.";
CM_ SG_ 958 MO_FMAus_aktiv "Das Signal gibt Rückmeldung ob Freilauf Motor aus aktiv ist. Beleibt auch 0km/h (unterhalb der StartStopp Schwelle) weiterhin aktiv.";
CM_ SG_ 958 MO_FMAus_Startvariante "Startvariante beim Motorstart aus der Freilauf-Motor-AUS Phase";
CM_ SG_ 958 MO_BMS_NV_Anf_stuetzen "Garantierte Unterstützung des Zusatzspeichers ist erforderlich. Zusatzspeicher muss an das Versorgungsnezt angebunden werden. ";
CM_ SG_ 958 MO_Zylinderabschaltung "Status Zylinderabschaltung Motor";
CM_ SG_ 958 MO_HYB_VM_aktiv "0 = VMotor wird nicht aktiv gehalten (nVM < n_min und keine LL-Regelung aktiv)
1 = VMotor aktiv (ab der ersten Einspritzung; gilt auch für Schubbetrieb, wenn VMotor spätestens durch LLRegelung befeuert würde)
Verwendet zur Bestimmung des Ist-Zustandes";
CM_ SG_ 958 MO_StartVorauss_erfuellt "Dient der Fallunterscheidung bei ZAT-Betätigung im Zustand 'KL15 ein' (bei nicht gesetztem Signal folgt KL15 aus, bei gesetztem Signal folgt setzen KL50-Anf.)

0: Signal nicht bedient 
1: Voraussetzungen zur Antriebsstrangaktivierung / Startvoraussetzu";
CM_ SG_ 994 MXB_Allgemein_li_defekt "Sammelfehler für die Elektronikumfänge des linken Scheinwerfers";
CM_ SG_ 994 MXB_Allgemein_re_defekt "Sammelfehler für die Elektronikumfänge des rechten Scheinwerfers";
CM_ SG_ 994 MXB_Fernlicht_li_defekt "Beschreibt ob das Fernlicht des linken Scheinwerfers defekt ist";
CM_ SG_ 994 MXB_Fernlicht_re_defekt "Beschreibt ob das Fernlicht des rechten Scheinwerfers defekt ist";
CM_ SG_ 994 MXB_Fernlicht_Status "Beschreibt ob das Fernlicht aktiv oder inaktiv ist";
CM_ SG_ 994 MXB_Sicherheitspos_li_Anf "Anforderung der Sicherheitsposition des linken Scheinwerfers.";
CM_ SG_ 994 MXB_Sicherheitspos_re_Anf "Anforderung der Sicherheitsposition des rechten Scheinwerfers.";
CM_ SG_ 994 MXB_Verfuegbarkeit "Beschreibt die Verfügbarkeit von MatrixBeam/ Fernlichtassistenz - Verfügbarkeit bedeutet, dass die Funktion möglich ist";
CM_ SG_ 994 Kamera_Sensor_blockiert "Das Signal zeigt an, dass die Kamera zur Zeit keine Sicht hat. Verhalten wie Fernlichassistent. Weiterleitung des Signals vom BCM an das Kombi.";
CM_ SG_ 994 AFS_Allwetterlicht_Unterdrueck "Signal zur Unterdrückung des Allwetterlichtes im BCM1";
CM_ SG_ 994 AFS_Autobahnlicht_Unterdrueckung "Signal zur Unterdrückung des Autobahnlichtes im BCM1";
CM_ SG_ 994 AFS_Blinkermode_BVS "Lampe soll im Warnfall mit 1Hz blinken, wenn das Bit gesetzt ist";
CM_ SG_ 994 AFS_Fehlertext_BVS "Fehlertext wird im Kombi angezeigt";
CM_ SG_ 994 AFS_Lampe_BVS "Status der Fehlerlampe: aktuell anliegender Fehlerzustand des MXB-Systems";
CM_ SG_ 994 AFS_Stadtlicht_Unterdrueckung "Signal zur Unterdrückung des Stadtlichtes im BCM";
CM_ SG_ 994 MXB_Z_Fernlicht_L_Anf "Anforderung aus dem MXB Algo zur Aktivierung des Zusatzfernlichtes links";
CM_ SG_ 994 MXB_Z_Fernlicht_L_Schaltart "Schaltart für das über den MXB Algo angeforderte Zusatzfernlicht links";
CM_ SG_ 994 MXB_Z_Fernlicht_R_Anf "Anforderung aus dem MXB Algo zur Aktivierung des Zusatzfernlichtes rechts";
CM_ SG_ 994 MXB_Z_Fernlicht_R_Schaltart "Schaltart für das über den MXB Algo angeforderte Zusatzfernlicht rechts";
CM_ SG_ 2463978604 MXB_Blickwinkel_L "Winkelangabe für blickgeführte Ansteuerung des dynamischen Abblendlichts";
CM_ SG_ 2463978604 MXB_Blickwinkel_R "Winkelangabe für blickgeführte Ansteuerung des dynamischen Abblendlichts";
CM_ SG_ 2463978604 MXB_Baustellenlicht_L_Anf "Anforderung des Baustellenlichts";
CM_ SG_ 2463978604 MXB_Baustellenlicht_R_Anf "Anforderung des Baustellenlichts";
CM_ SG_ 2463978604 MXB_AWL_Sichtweitenanpassung "Steuersignal zur sichtweitenbedingten Anpassung der Allwetterlichts";
CM_ SG_ 1358 MXB_L_Fernl_MXB_Def_1 "Unterspannung";
CM_ SG_ 1358 MXB_L_Fernl_MXB_Def_2 "Ueberspannung";
CM_ SG_ 1358 MXB_L_Fernl_MXB_Def_3 "Abweichung_CAN_Info_zu_Klemmenspg";
CM_ SG_ 1358 MXB_L_Fernl_MXB_Def_4 "Fehler_Stromcodierung";
CM_ SG_ 1358 MXB_L_Fernl_MXB_Def_5 "Fehler_Temperatursensor";
CM_ SG_ 1358 MXB_L_Fernl_MXB_Def_6 "Uebertemperatur";
CM_ SG_ 1358 MXB_L_Fernl_MXB_Def_7 "Fehler_Lichtfunktion";
CM_ SG_ 1358 MXB_L_Allg_Elektr_Def_1 "Fehler_Versorgungsspannung";
CM_ SG_ 1358 MXB_L_Allg_Elektr_Def_2 "Uebertemperatur";
CM_ SG_ 1358 MXB_L_Allg_Elektr_Def_3 "Fehler_RAM_Check";
CM_ SG_ 1358 MXB_L_Allg_Elektr_Def_4 "Fehler_ROM_Check";
CM_ SG_ 1358 MXB_L_Allg_Elektr_Def_5 "Fehler_EEPROM";
CM_ SG_ 1358 MXB_L_Allg_Elektr_Def_6 "Fehler_interner_Temperatursensor";
CM_ SG_ 1358 MXB_L_Allg_Elektr_Def_7 "Fehler_R_L_Erkennung";
CM_ SG_ 1358 MXB_L_Allg_Elektr_Def_8 "Sonstige_Fehler";
CM_ SG_ 1358 MXB_L_Luefter_1_Def_1 "Luefter_1_Open_Load";
CM_ SG_ 1358 MXB_L_Luefter_1_Def_2 "Luefter_1_Kurzschluss";
CM_ SG_ 1358 MXB_L_Luefter_1_Def_3 "Luefter_1_Unterspannung";
CM_ SG_ 1358 MXB_L_Luefter_1_Def_4 "Luefter_1_Ueberspannung";
CM_ SG_ 1358 MXB_L_Luefter_2_Def_1 "Luefter_2_Open_Load";
CM_ SG_ 1358 MXB_L_Luefter_2_Def_2 "Luefter_2_Kurzschluss";
CM_ SG_ 1358 MXB_L_Luefter_2_Def_3 "Luefter_2_Unterspannung";
CM_ SG_ 1358 MXB_L_Luefter_2_Def_4 "Luefter_2_Ueberspannung";
CM_ SG_ 1358 MXB_L_Allg_Elektr_Def "MXB-Leimo defekt";
CM_ SG_ 1358 MXB_L_Fernl_MXB_Def "MXB-Fernlicht defekt";
BA_DEF_ BO_  "DiagRequest" ENUM  "No","Yes";
BA_DEF_ BO_  "DiagResponse" ENUM  "No","Yes";
BA_DEF_ BO_  "DiagState" ENUM  "No","Yes";
BA_DEF_ BO_  "GenMsgChkConstant" HEX 0 4095;
BA_DEF_ BO_  "GenMsgCycleTime" INT 0 65535;
BA_DEF_ BO_  "GenMsgCycleTimeFast" INT 0 65535;
BA_DEF_ BO_  "GenMsgDelayTime" INT 0 100000;
BA_DEF_ BO_  "GenMsgILSupport" ENUM  "No","Yes";
BA_DEF_ BO_  "GenMsgNrOfRepetition" INT 0 100;
BA_DEF_ BO_  "GenMsgPDUConstants" STRING ;
BA_DEF_ BO_  "GenMsgSendType" ENUM  "Cyclic","not_used","not_used","not_used","not_used","not_used","not_used","IfActive","NoMsgSendType";
BA_DEF_ BO_  "GenMsgStartDelayTime" INT 0 100000;
BA_DEF_ BO_  "NmMessage" ENUM  "No","Yes";
BA_DEF_ BO_  "NmhMessage" ENUM  "No","Yes";
BA_DEF_ BO_  "MsgType" ENUM  "Application","NM ","NMH","TP2.0","ISO-TP ","BAP","EID","KS";
BA_DEF_ BO_  "VAGTP20_API" HEX 0 255;
BA_DEF_ BO_  "VAGTP20_DynConnection" ENUM  "No","Yes";
BA_DEF_ BO_  "VAGTP20_DynSetup" ENUM  "No","Yes";
BA_DEF_ BO_  "VAGTP20_StatConnection" ENUM  "No","Yes";
BA_DEF_ SG_  "GenSigActiveRepetitions" INT -2147483648 2147483647;
BA_DEF_ SG_  "GenSigSendType" ENUM  "Cyclic","OnWrite","OnWriteWithRepetition","OnChange","OnChangeWithRepetition","IfActive","IfActiveWithRepetition","NoSigSendType","OnChangeAndIfActive","OnChangeAndIfActiveWithRepetition";
BA_DEF_ SG_  "GenSigStartValue" INT -2147483648 2147483647;
BA_DEF_ SG_  "NWM-WakeupAllowed" ENUM  "No","Yes";
BA_DEF_ SG_  "GenSigFuncType" ENUM  "NoFunction","MsgCounter","CRC-8","XOR","XOR-2","DatedBit","SW-Kl15","CHK","Constant","Protocol","CRC-8-SAE_J1850";
BA_DEF_ SG_  "GenSigSwitchedByIgnition" ENUM  "No","Yes";
BA_DEF_ SG_  "Fehlerwert" HEX 0 2147483647;
BA_DEF_ SG_  "GenSigMissingSourceValue" HEX 0 2147483647;
BA_DEF_REL_ BU_SG_REL_  "GenSigTimeoutTime" INT 0 65535;
BA_DEF_DEF_  "DiagRequest" "No";
BA_DEF_DEF_  "DiagResponse" "No";
BA_DEF_DEF_  "DiagState" "No";
BA_DEF_DEF_  "GenMsgChkConstant" 0;
BA_DEF_DEF_  "GenMsgCycleTime" 0;
BA_DEF_DEF_  "GenMsgCycleTimeFast" 0;
BA_DEF_DEF_  "GenMsgDelayTime" 0;
BA_DEF_DEF_  "GenMsgILSupport" "No";
BA_DEF_DEF_  "GenMsgNrOfRepetition" 0;
BA_DEF_DEF_  "GenMsgPDUConstants" "";
BA_DEF_DEF_  "GenMsgSendType" "NoMsgSendType";
BA_DEF_DEF_  "GenMsgStartDelayTime" 0;
BA_DEF_DEF_  "NmMessage" "No";
BA_DEF_DEF_  "NmhMessage" "No";
BA_DEF_DEF_  "MsgType" "Application";
BA_DEF_DEF_  "VAGTP20_API" 0;
BA_DEF_DEF_  "VAGTP20_DynConnection" "No";
BA_DEF_DEF_  "VAGTP20_DynSetup" "No";
BA_DEF_DEF_  "VAGTP20_StatConnection" "No";
BA_DEF_DEF_  "GenSigActiveRepetitions" 0;
BA_DEF_DEF_  "GenSigSendType" "NoSigSendType";
BA_DEF_DEF_  "GenSigStartValue" 0;
BA_DEF_DEF_  "NWM-WakeupAllowed" "No";
BA_DEF_DEF_  "GenSigFuncType" "NoFunction";
BA_DEF_DEF_  "GenSigSwitchedByIgnition" "Yes";
BA_DEF_DEF_  "Fehlerwert" 0;
BA_DEF_DEF_  "GenSigMissingSourceValue" 0;
BA_DEF_DEF_REL_ "GenSigTimeoutTime" 0;
BA_ "GenMsgCycleTime" BO_ 1389 1000;
BA_ "GenMsgILSupport" BO_ 1389 1;
BA_ "GenMsgSendType" BO_ 1389 0;
BA_ "GenMsgCycleTime" BO_ 1395 1000;
BA_ "GenMsgILSupport" BO_ 1395 1;
BA_ "GenMsgSendType" BO_ 1395 0;
BA_ "GenMsgCycleTime" BO_ 1390 1000;
BA_ "GenMsgILSupport" BO_ 1390 1;
BA_ "GenMsgSendType" BO_ 1390 0;
BA_ "GenMsgCycleTime" BO_ 1396 1000;
BA_ "GenMsgILSupport" BO_ 1396 1;
BA_ "GenMsgSendType" BO_ 1396 0;
BA_ "GenMsgCycleTime" BO_ 2589283616 200;
BA_ "GenMsgDelayTime" BO_ 2589283616 20;
BA_ "GenMsgILSupport" BO_ 2589283616 1;
BA_ "GenMsgSendType" BO_ 2589283616 0;
BA_ "GenMsgCycleTime" BO_ 2463978601 200;
BA_ "GenMsgDelayTime" BO_ 2463978601 20;
BA_ "GenMsgILSupport" BO_ 2463978601 1;
BA_ "GenMsgSendType" BO_ 2463978601 0;
BA_ "GenMsgCycleTime" BO_ 837 200;
BA_ "GenMsgDelayTime" BO_ 837 20;
BA_ "GenMsgILSupport" BO_ 837 1;
BA_ "GenMsgSendType" BO_ 837 0;
BA_ "GenMsgCycleTime" BO_ 404 20;
BA_ "GenMsgILSupport" BO_ 404 1;
BA_ "GenMsgSendType" BO_ 404 0;
BA_ "GenMsgCycleTime" BO_ 405 20;
BA_ "GenMsgILSupport" BO_ 405 1;
BA_ "GenMsgSendType" BO_ 405 0;
BA_ "GenMsgCycleTime" BO_ 351 20;
BA_ "GenMsgILSupport" BO_ 351 1;
BA_ "GenMsgSendType" BO_ 351 0;
BA_ "GenMsgCycleTime" BO_ 920 100;
BA_ "GenMsgILSupport" BO_ 920 1;
BA_ "GenMsgSendType" BO_ 920 0;
BA_ "GenMsgCycleTime" BO_ 922 100;
BA_ "GenMsgILSupport" BO_ 922 1;
BA_ "GenMsgSendType" BO_ 922 0;
BA_ "GenMsgCycleTime" BO_ 400 10;
BA_ "GenMsgILSupport" BO_ 400 1;
BA_ "GenMsgSendType" BO_ 400 0;
BA_ "GenMsgCycleTime" BO_ 406 10;
BA_ "GenMsgILSupport" BO_ 406 1;
BA_ "GenMsgSendType" BO_ 406 0;
BA_ "GenMsgCycleTime" BO_ 408 10;
BA_ "GenMsgILSupport" BO_ 408 1;
BA_ "GenMsgSendType" BO_ 408 0;
BA_ "GenMsgCycleTime" BO_ 958 100;
BA_ "GenMsgDelayTime" BO_ 958 10;
BA_ "GenMsgILSupport" BO_ 958 1;
BA_ "GenMsgSendType" BO_ 958 0;
BA_ "GenMsgCycleTime" BO_ 994 1000;
BA_ "GenMsgDelayTime" BO_ 994 50;
BA_ "GenMsgILSupport" BO_ 994 1;
BA_ "GenMsgSendType" BO_ 994 0;
BA_ "GenMsgCycleTime" BO_ 2463978604 100;
BA_ "GenMsgDelayTime" BO_ 2463978604 20;
BA_ "GenMsgILSupport" BO_ 2463978604 1;
BA_ "GenMsgSendType" BO_ 2463978604 0;
BA_ "GenMsgCycleTime" BO_ 1358 200;
BA_ "GenMsgILSupport" BO_ 1358 1;
BA_ "GenMsgSendType" BO_ 1358 0;
BA_ "GenSigSendType" SG_ 1389 LED_L_Uspg_Schutz 0;
BA_ "GenSigSendType" SG_ 1389 LED_L_Spannung_KL15 0;
BA_ "GenSigStartValue" SG_ 1389 LED_L_Spannung_KL15 126;
BA_ "Fehlerwert" SG_ 1389 LED_L_Spannung_KL15 127;
BA_ "GenSigSendType" SG_ 1389 LED_L_Spannung_KL56a 0;
BA_ "GenSigStartValue" SG_ 1389 LED_L_Spannung_KL56a 126;
BA_ "Fehlerwert" SG_ 1389 LED_L_Spannung_KL56a 127;
BA_ "GenSigSendType" SG_ 1389 LED_L_Spannung_KL56b 0;
BA_ "GenSigStartValue" SG_ 1389 LED_L_Spannung_KL56b 126;
BA_ "Fehlerwert" SG_ 1389 LED_L_Spannung_KL56b 127;
BA_ "GenSigSendType" SG_ 1389 LED_L_Spannung_TFL 0;
BA_ "GenSigStartValue" SG_ 1389 LED_L_Spannung_TFL 126;
BA_ "Fehlerwert" SG_ 1389 LED_L_Spannung_TFL 127;
BA_ "GenSigSendType" SG_ 1389 LED_L_Temp_Schutz 0;
BA_ "GenSigSendType" SG_ 1389 LED_L_Temp_Mux 0;
BA_ "Fehlerwert" SG_ 1389 LED_L_Temp_SG_Intern 255;
BA_ "Fehlerwert" SG_ 1389 LED_L_Temp_Kanal1_Master 255;
BA_ "Fehlerwert" SG_ 1389 LED_L_Temp_Kanal1_Master2 255;
BA_ "Fehlerwert" SG_ 1389 LED_L_Temp_Kanal1_Slave 255;
BA_ "Fehlerwert" SG_ 1389 LED_L_Temp_Kanal2_Master 255;
BA_ "Fehlerwert" SG_ 1389 LED_L_Temp_Kanal2_Slave 255;
BA_ "Fehlerwert" SG_ 1389 LED_L_Temp_Kanal3_Master 255;
BA_ "Fehlerwert" SG_ 1389 LED_L_Temp_Kanal3_Slave 255;
BA_ "GenSigSendType" SG_ 1395 LED_L_Strom_Kanal1_Master 0;
BA_ "GenSigStartValue" SG_ 1395 LED_L_Strom_Kanal1_Master 510;
BA_ "GenSigSendType" SG_ 1395 LED_L_Strom_Kanal1_Master2 0;
BA_ "GenSigStartValue" SG_ 1395 LED_L_Strom_Kanal1_Master2 510;
BA_ "GenSigSendType" SG_ 1395 LED_L_Strom_Kanal1_Slave 0;
BA_ "GenSigStartValue" SG_ 1395 LED_L_Strom_Kanal1_Slave 510;
BA_ "GenSigSendType" SG_ 1395 LED_L_Strom_Kanal2_Master 0;
BA_ "GenSigStartValue" SG_ 1395 LED_L_Strom_Kanal2_Master 510;
BA_ "GenSigSendType" SG_ 1395 LED_L_Strom_Kanal2_Slave 0;
BA_ "GenSigStartValue" SG_ 1395 LED_L_Strom_Kanal2_Slave 510;
BA_ "GenSigSendType" SG_ 1395 LED_L_Strom_Kanal3_Master 0;
BA_ "GenSigStartValue" SG_ 1395 LED_L_Strom_Kanal3_Master 510;
BA_ "GenSigSendType" SG_ 1395 LED_L_Strom_Kanal3_Slave 0;
BA_ "GenSigStartValue" SG_ 1395 LED_L_Strom_Kanal3_Slave 510;
BA_ "GenSigSendType" SG_ 1395 LED_L_Tag_Nacht_Umschaltung_Sta 0;
BA_ "GenSigSendType" SG_ 1390 LED_R_Uspg_Schutz 0;
BA_ "GenSigSendType" SG_ 1390 LED_R_Spannung_KL15 0;
BA_ "GenSigStartValue" SG_ 1390 LED_R_Spannung_KL15 126;
BA_ "Fehlerwert" SG_ 1390 LED_R_Spannung_KL15 127;
BA_ "GenSigSendType" SG_ 1390 LED_R_Spannung_KL56a 0;
BA_ "GenSigStartValue" SG_ 1390 LED_R_Spannung_KL56a 126;
BA_ "Fehlerwert" SG_ 1390 LED_R_Spannung_KL56a 127;
BA_ "GenSigSendType" SG_ 1390 LED_R_Spannung_KL56b 0;
BA_ "GenSigStartValue" SG_ 1390 LED_R_Spannung_KL56b 126;
BA_ "Fehlerwert" SG_ 1390 LED_R_Spannung_KL56b 127;
BA_ "GenSigSendType" SG_ 1390 LED_R_Spannung_TFL 0;
BA_ "GenSigStartValue" SG_ 1390 LED_R_Spannung_TFL 126;
BA_ "Fehlerwert" SG_ 1390 LED_R_Spannung_TFL 127;
BA_ "GenSigSendType" SG_ 1390 LED_R_Temp_Schutz 0;
BA_ "GenSigSendType" SG_ 1390 LED_R_Temp_Mux 0;
BA_ "Fehlerwert" SG_ 1390 LED_R_Temp_SG_Intern 255;
BA_ "Fehlerwert" SG_ 1390 LED_R_Temp_Kanal1_Master 255;
BA_ "Fehlerwert" SG_ 1390 LED_R_Temp_Kanal1_Master2 255;
BA_ "Fehlerwert" SG_ 1390 LED_R_Temp_Kanal1_Slave 255;
BA_ "Fehlerwert" SG_ 1390 LED_R_Temp_Kanal2_Master 255;
BA_ "Fehlerwert" SG_ 1390 LED_R_Temp_Kanal2_Slave 255;
BA_ "Fehlerwert" SG_ 1390 LED_R_Temp_Kanal3_Master 255;
BA_ "Fehlerwert" SG_ 1390 LED_R_Temp_Kanal3_Slave 255;
BA_ "GenSigSendType" SG_ 1396 LED_R_Strom_Kanal1_Master 0;
BA_ "GenSigStartValue" SG_ 1396 LED_R_Strom_Kanal1_Master 510;
BA_ "GenSigSendType" SG_ 1396 LED_R_Strom_Kanal1_Master2 0;
BA_ "GenSigStartValue" SG_ 1396 LED_R_Strom_Kanal1_Master2 510;
BA_ "GenSigSendType" SG_ 1396 LED_R_Strom_Kanal1_Slave 0;
BA_ "GenSigStartValue" SG_ 1396 LED_R_Strom_Kanal1_Slave 510;
BA_ "GenSigSendType" SG_ 1396 LED_R_Strom_Kanal2_Master 0;
BA_ "GenSigStartValue" SG_ 1396 LED_R_Strom_Kanal2_Master 510;
BA_ "GenSigSendType" SG_ 1396 LED_R_Strom_Kanal2_Slave 0;
BA_ "GenSigStartValue" SG_ 1396 LED_R_Strom_Kanal2_Slave 510;
BA_ "GenSigSendType" SG_ 1396 LED_R_Strom_Kanal3_Master 0;
BA_ "GenSigStartValue" SG_ 1396 LED_R_Strom_Kanal3_Master 510;
BA_ "GenSigSendType" SG_ 1396 LED_R_Strom_Kanal3_Slave 0;
BA_ "GenSigStartValue" SG_ 1396 LED_R_Strom_Kanal3_Slave 510;
BA_ "GenSigSendType" SG_ 1396 LED_R_Tag_Nacht_Umschaltung_Sta 0;
BA_ "GenSigSendType" SG_ 2589283616 LED_R_DABL_LED_01_Anf 3;
BA_ "GenSigSendType" SG_ 2589283616 LED_R_DABL_LED_02_Anf 3;
BA_ "GenSigSendType" SG_ 2589283616 LED_R_DABL_LED_03_Anf 3;
BA_ "GenSigSendType" SG_ 2589283616 LED_R_DABL_LED_04_Anf 3;
BA_ "GenSigSendType" SG_ 2589283616 LED_R_DABL_LED_05_Anf 3;
BA_ "GenSigSendType" SG_ 2589283616 LED_R_DABL_LED_06_Anf 3;
BA_ "GenSigSendType" SG_ 2589283616 LED_R_DABL_LED_07_Anf 3;
BA_ "GenSigSendType" SG_ 2589283616 LED_R_DABL_LED_08_Anf 3;
BA_ "GenSigSendType" SG_ 2589283616 LED_R_DABL_LED_09_Anf 3;
BA_ "GenSigSendType" SG_ 2589283616 LED_R_DABL_LED_10_Anf 3;
BA_ "GenSigSendType" SG_ 2463978601 LED_R_DABL_LED_11_Anf 3;
BA_ "GenSigSendType" SG_ 2463978601 LED_R_DABL_LED_12_Anf 3;
BA_ "GenSigSendType" SG_ 2463978601 LED_R_DABL_LED_13_Anf 3;
BA_ "GenSigSendType" SG_ 2463978601 LED_R_DABL_LED_14_Anf 3;
BA_ "GenSigSendType" SG_ 2463978601 LED_R_DABL_LED_15_Anf 3;
BA_ "GenSigSendType" SG_ 2463978601 LED_R_DABL_LED_16_Anf 3;
BA_ "GenSigSendType" SG_ 2463978601 LED_R_DABL_LED_17_Anf 3;
BA_ "GenSigSendType" SG_ 2463978601 LED_R_DABL_LED_18_Anf 3;
BA_ "GenSigSendType" SG_ 2463978601 LED_R_DABL_LED_19_Anf 3;
BA_ "GenSigSendType" SG_ 2463978601 LED_R_DABL_LED_20_Anf 3;
BA_ "GenSigSendType" SG_ 837 LED_R_SABL_LED_01_Anf 3;
BA_ "GenSigSendType" SG_ 837 LED_R_SABL_LED_02_Anf 3;
BA_ "GenSigSendType" SG_ 837 LED_R_SABL_LED_03_Anf 3;
BA_ "GenSigSendType" SG_ 837 LED_R_SABL_LED_04_Anf 3;
BA_ "GenSigSendType" SG_ 837 LED_R_SABL_LED_05_Anf 3;
BA_ "GenSigSendType" SG_ 837 LED_R_SABL_LED_06_Anf 3;
BA_ "GenSigSendType" SG_ 837 LED_R_SABL_LED_07_Anf 3;
BA_ "GenSigSendType" SG_ 837 LED_R_SABL_LED_08_Anf 3;
BA_ "GenSigSendType" SG_ 837 LED_R_SABL_LED_09_Anf 3;
BA_ "GenSigSendType" SG_ 837 LED_R_SABL_LED_10_Anf 3;
BA_ "GenSigSendType" SG_ 404 LED_L_Abblendl_Anf 0;
BA_ "GenSigSendType" SG_ 404 LED_L_Abblendl_Schaltart 0;
BA_ "GenSigSendType" SG_ 404 LED_R_Abblendl_Anf 0;
BA_ "GenSigSendType" SG_ 404 LED_R_Abblendl_Schaltart 0;
BA_ "GenSigSendType" SG_ 404 LED_L_Fernl_LH_Anf 0;
BA_ "GenSigSendType" SG_ 404 LED_L_Fernl_LH_Schaltart 0;
BA_ "GenSigSendType" SG_ 404 LED_R_Fernl_LH_Anf 0;
BA_ "GenSigSendType" SG_ 404 LED_R_Fernl_LH_Schaltart 0;
BA_ "GenSigSendType" SG_ 404 LED_L_Nebel_All_Anf 0;
BA_ "GenSigSendType" SG_ 404 LED_L_Nebel_All_Schaltart 0;
BA_ "GenSigSendType" SG_ 404 LED_R_Nebel_All_Anf 0;
BA_ "GenSigSendType" SG_ 404 LED_R_Nebel_All_Schaltart 0;
BA_ "GenSigSendType" SG_ 404 LED_Sta_Diag 0;
BA_ "GenSigSendType" SG_ 404 LED_L_Zus_Fernl_LH_Anf 0;
BA_ "GenSigSendType" SG_ 404 LED_L_Zus_Fernl_LH_Schaltart 0;
BA_ "GenSigSendType" SG_ 404 LED_R_Zus_Fernl_LH_Anf 0;
BA_ "GenSigSendType" SG_ 404 LED_R_Zus_Fernl_LH_Schaltart 0;
BA_ "GenSigSendType" SG_ 405 LED_L_Abbiegel_Anf 0;
BA_ "GenSigSendType" SG_ 405 LED_L_Abbiegel_Schaltart 0;
BA_ "GenSigSendType" SG_ 405 LED_R_Abbiegel_Anf 0;
BA_ "GenSigSendType" SG_ 405 LED_R_Abbiegel_Schaltart 0;
BA_ "GenSigSendType" SG_ 405 LED_L_Autobahnl_Anf 0;
BA_ "GenSigSendType" SG_ 405 LED_L_Autobahnl_Schaltart 0;
BA_ "GenSigSendType" SG_ 405 LED_R_Autobahnl_Anf 0;
BA_ "GenSigSendType" SG_ 405 LED_R_Autobahnl_Schaltart 0;
BA_ "GenSigSendType" SG_ 405 LED_L_Eco_Mode_1_Anf 0;
BA_ "GenSigSendType" SG_ 405 LED_L_Eco_Mode_1_Schaltart 0;
BA_ "GenSigSendType" SG_ 405 LED_R_Eco_Mode_1_Anf 0;
BA_ "GenSigSendType" SG_ 405 LED_R_Eco_Mode_1_Schaltart 0;
BA_ "GenSigSendType" SG_ 405 LED_L_Eco_Mode_2_Anf 0;
BA_ "GenSigSendType" SG_ 405 LED_L_Eco_Mode_2_Schaltart 0;
BA_ "GenSigSendType" SG_ 405 LED_R_Eco_Mode_2_Anf 0;
BA_ "GenSigSendType" SG_ 405 LED_R_Eco_Mode_2_Schaltart 0;
BA_ "GenSigSendType" SG_ 405 LED_L_Rennl_Anf 0;
BA_ "GenSigSendType" SG_ 405 LED_L_Rennl_Schaltart 0;
BA_ "GenSigSendType" SG_ 405 LED_R_Rennl_Anf 0;
BA_ "GenSigSendType" SG_ 405 LED_R_Rennl_Schaltart 0;
BA_ "GenSigSendType" SG_ 405 LED_L_Stadtl_Anf 0;
BA_ "GenSigSendType" SG_ 405 LED_L_Stadtl_Schaltart 0;
BA_ "GenSigSendType" SG_ 405 LED_R_Stadtl_Anf 0;
BA_ "GenSigSendType" SG_ 405 LED_R_Stadtl_Schaltart 0;
BA_ "GenSigSendType" SG_ 405 LED_L_TFL_Anf 0;
BA_ "GenSigSendType" SG_ 405 LED_L_TFL_Schaltart 0;
BA_ "GenSigSendType" SG_ 405 LED_R_TFL_Anf 0;
BA_ "GenSigSendType" SG_ 405 LED_R_TFL_Schaltart 0;
BA_ "GenSigSendType" SG_ 405 LED_L_Touristenl_Anf 0;
BA_ "GenSigSendType" SG_ 405 LED_L_Touristenl_Schaltart 0;
BA_ "GenSigSendType" SG_ 405 LED_R_Touristenl_Anf 0;
BA_ "GenSigSendType" SG_ 405 LED_R_Touristenl_Schaltart 0;
BA_ "GenSigSendType" SG_ 405 LED_ECE_SAE_Umschaltung_Anf 0;
BA_ "GenSigSendType" SG_ 405 LED_Tag_Nacht_Umschaltung_Anf 0;
BA_ "GenSigSendType" SG_ 405 LED_Sta_Diag 0;
BA_ "GenSigSendType" SG_ 405 LED_L_Abbiegel_Dimmung 0;
BA_ "Fehlerwert" SG_ 405 LED_L_Abbiegel_Dimmung 255;
BA_ "GenSigSendType" SG_ 405 LED_R_Abbiegel_Dimmung 0;
BA_ "Fehlerwert" SG_ 405 LED_R_Abbiegel_Dimmung 255;
BA_ "GenSigSendType" SG_ 351 LED_Soll_Fkt2_CRC 0;
BA_ "GenSigFuncType" SG_ 351 LED_Soll_Fkt2_CRC 2;
BA_ "GenSigSwitchedByIgnition" SG_ 351 LED_Soll_Fkt2_CRC 0;
BA_ "GenSigSendType" SG_ 351 LED_Soll_Fkt2_BZ 0;
BA_ "GenSigFuncType" SG_ 351 LED_Soll_Fkt2_BZ 1;
BA_ "GenSigSwitchedByIgnition" SG_ 351 LED_Soll_Fkt2_BZ 0;
BA_ "GenSigSendType" SG_ 351 LED_L_Abblendl_Anf 0;
BA_ "GenSigSendType" SG_ 351 LED_L_Abblendl_Schaltart 0;
BA_ "GenSigSendType" SG_ 351 LED_R_Abblendl_Anf 0;
BA_ "GenSigSendType" SG_ 351 LED_R_Abblendl_Schaltart 0;
BA_ "GenSigSendType" SG_ 351 LED_L_Fernl_LH_Anf 0;
BA_ "GenSigSendType" SG_ 351 LED_L_Fernl_LH_Schaltart 0;
BA_ "GenSigSendType" SG_ 351 LED_R_Fernl_LH_Anf 0;
BA_ "GenSigSendType" SG_ 351 LED_R_Fernl_LH_Schaltart 0;
BA_ "GenSigSendType" SG_ 351 LED_L_Nebel_All_Anf 0;
BA_ "GenSigSendType" SG_ 351 LED_L_Nebel_All_Schaltart 0;
BA_ "GenSigSendType" SG_ 351 LED_R_Nebel_All_Anf 0;
BA_ "GenSigSendType" SG_ 351 LED_R_Nebel_All_Schaltart 0;
BA_ "GenSigSendType" SG_ 351 LED_Sta_Diag 0;
BA_ "GenSigSendType" SG_ 351 LED_L_Zus_Fernl_LH_Anf 0;
BA_ "GenSigSendType" SG_ 351 LED_L_Zus_Fernl_LH_Schaltart 0;
BA_ "GenSigSendType" SG_ 351 LED_R_Zus_Fernl_LH_Anf 0;
BA_ "GenSigSendType" SG_ 351 LED_R_Zus_Fernl_LH_Schaltart 0;
BA_ "NWM-WakeupAllowed" SG_ 351 BCM1_CH_aktiv 1;
BA_ "GenSigSwitchedByIgnition" SG_ 351 BCM1_CH_aktiv 0;
BA_ "NWM-WakeupAllowed" SG_ 351 BCM1_LH_aktiv 1;
BA_ "GenSigSwitchedByIgnition" SG_ 351 BCM1_LH_aktiv 0;
BA_ "GenSigSendType" SG_ 920 FLL_SchMot 0;
BA_ "Fehlerwert" SG_ 920 FLL_SchMot 1;
BA_ "GenSigSendType" SG_ 920 FLL_RSchMot 0;
BA_ "GenSigStartValue" SG_ 920 FLL_RSchMot 1;
BA_ "GenSigSendType" SG_ 920 FLL_SM_KS_Gnd 0;
BA_ "Fehlerwert" SG_ 920 FLL_SM_KS_Gnd 1;
BA_ "GenSigSendType" SG_ 920 FLL_RSM_KS_Gnd 0;
BA_ "GenSigStartValue" SG_ 920 FLL_RSM_KS_Gnd 1;
BA_ "GenSigSendType" SG_ 920 FLL_SM_UeSpg 0;
BA_ "Fehlerwert" SG_ 920 FLL_SM_UeSpg 1;
BA_ "GenSigSendType" SG_ 920 FLL_RSM_UeSpg 0;
BA_ "GenSigStartValue" SG_ 920 FLL_RSM_UeSpg 1;
BA_ "GenSigSendType" SG_ 920 FLL_SM_USpg 0;
BA_ "Fehlerwert" SG_ 920 FLL_SM_USpg 1;
BA_ "GenSigSendType" SG_ 920 FLL_RSM_USpg 0;
BA_ "GenSigStartValue" SG_ 920 FLL_RSM_USpg 1;
BA_ "GenSigSendType" SG_ 920 FLL_SM_UeTemp 0;
BA_ "Fehlerwert" SG_ 920 FLL_SM_UeTemp 1;
BA_ "GenSigSendType" SG_ 920 FLL_RSM_UeTemp 0;
BA_ "GenSigStartValue" SG_ 920 FLL_RSM_UeTemp 1;
BA_ "GenSigSendType" SG_ 920 FLL_SM_TempPre 0;
BA_ "GenSigSendType" SG_ 920 FLL_RSM_TempPre 0;
BA_ "GenSigStartValue" SG_ 920 FLL_RSM_TempPre 1;
BA_ "GenSigSendType" SG_ 920 FLL_AFS_Unpl 0;
BA_ "GenSigSendType" SG_ 920 FLL_RAFS_Unpl 0;
BA_ "GenSigStartValue" SG_ 920 FLL_RAFS_Unpl 1;
BA_ "GenSigSendType" SG_ 922 FLR_SchMot 0;
BA_ "Fehlerwert" SG_ 922 FLR_SchMot 1;
BA_ "GenSigSendType" SG_ 922 FLR_RSchMot 0;
BA_ "GenSigStartValue" SG_ 922 FLR_RSchMot 1;
BA_ "GenSigSendType" SG_ 922 FLR_SM_KS_Gnd 0;
BA_ "Fehlerwert" SG_ 922 FLR_SM_KS_Gnd 1;
BA_ "GenSigSendType" SG_ 922 FLR_RSM_KS_Gnd 0;
BA_ "GenSigStartValue" SG_ 922 FLR_RSM_KS_Gnd 1;
BA_ "GenSigSendType" SG_ 922 FLR_SM_UeSpg 0;
BA_ "Fehlerwert" SG_ 922 FLR_SM_UeSpg 1;
BA_ "GenSigSendType" SG_ 922 FLR_RSM_UeSpg 0;
BA_ "GenSigStartValue" SG_ 922 FLR_RSM_UeSpg 1;
BA_ "GenSigSendType" SG_ 922 FLR_SM_USpg 0;
BA_ "Fehlerwert" SG_ 922 FLR_SM_USpg 1;
BA_ "GenSigSendType" SG_ 922 FLR_RSM_USpg 0;
BA_ "GenSigStartValue" SG_ 922 FLR_RSM_USpg 1;
BA_ "GenSigSendType" SG_ 922 FLR_SM_UeTemp 0;
BA_ "Fehlerwert" SG_ 922 FLR_SM_UeTemp 1;
BA_ "GenSigSendType" SG_ 922 FLR_RSM_UeTemp 0;
BA_ "GenSigStartValue" SG_ 922 FLR_RSM_UeTemp 1;
BA_ "GenSigSendType" SG_ 922 FLR_SM_TempPre 0;
BA_ "GenSigSendType" SG_ 922 FLR_RSM_TempPre 0;
BA_ "GenSigStartValue" SG_ 922 FLR_RSM_TempPre 1;
BA_ "GenSigSendType" SG_ 922 FLR_AFS_Unpl 0;
BA_ "GenSigSendType" SG_ 922 FLR_RAFS_Unpl 0;
BA_ "GenSigStartValue" SG_ 922 FLR_RAFS_Unpl 1;
BA_ "GenSigSendType" SG_ 400 SOL_SollPos_L 0;
BA_ "GenSigStartValue" SG_ 400 SOL_SollPos_L 4094;
BA_ "Fehlerwert" SG_ 400 SOL_SollPos_L 4095;
BA_ "GenSigSendType" SG_ 400 SOL_FehlPos_L 0;
BA_ "GenSigSendType" SG_ 400 SOL_RefLauf_L 0;
BA_ "GenSigSendType" SG_ 400 SOL_StGlTest_L 0;
BA_ "GenSigSendType" SG_ 400 SOL_Fehlloesch_L 0;
BA_ "GenSigSendType" SG_ 400 MO_StartStopp_Motorstopp 0;
BA_ "GenSigSendType" SG_ 400 MO_StartStopp_Wiederstart 0;
BA_ "GenSigSendType" SG_ 400 SOL_Tieftemp_Flag 0;
BA_ "GenSigSendType" SG_ 400 SOL_SollPos_R 0;
BA_ "GenSigStartValue" SG_ 400 SOL_SollPos_R 4094;
BA_ "Fehlerwert" SG_ 400 SOL_SollPos_R 4095;
BA_ "GenSigSendType" SG_ 400 SOL_FehlPos_R 0;
BA_ "GenSigSendType" SG_ 400 SOL_RefLauf_R 0;
BA_ "GenSigSendType" SG_ 400 SOL_StGlTest_R 0;
BA_ "GenSigSendType" SG_ 400 SOL_Fehlloesch_R 0;
BA_ "GenSigSendType" SG_ 400 SOL_Sta_Diag 0;
BA_ "GenSigSendType" SG_ 406 SLL_IstPos 0;
BA_ "GenSigStartValue" SG_ 406 SLL_IstPos 4094;
BA_ "Fehlerwert" SG_ 406 SLL_IstPos 4095;
BA_ "GenSigSendType" SG_ 406 SLL_StaStStWiederstart 0;
BA_ "GenSigSendType" SG_ 406 SLL_StaStStMotorstopp 0;
BA_ "GenSigSendType" SG_ 406 SLL_IstPosMot 0;
BA_ "GenSigStartValue" SG_ 406 SLL_IstPosMot 254;
BA_ "Fehlerwert" SG_ 406 SLL_IstPosMot 255;
BA_ "GenSigSendType" SG_ 406 SLL_StaVerst 0;
BA_ "GenSigSendType" SG_ 406 SLL_StaFehPos 0;
BA_ "GenSigSendType" SG_ 406 SLL_StaReflauf 0;
BA_ "GenSigSendType" SG_ 406 SLL_StaStGlTst 0;
BA_ "GenSigSendType" SG_ 406 SLL_BestFehlosch 0;
BA_ "GenSigSendType" SG_ 406 SLL_StaAFSElMod 0;
BA_ "GenSigSendType" SG_ 406 SLL_StaTieftempFlag 0;
BA_ "GenSigSendType" SG_ 408 SLR_IstPos 0;
BA_ "GenSigStartValue" SG_ 408 SLR_IstPos 4094;
BA_ "Fehlerwert" SG_ 408 SLR_IstPos 4095;
BA_ "GenSigSendType" SG_ 408 SLR_StaStStWiederstart 0;
BA_ "GenSigSendType" SG_ 408 SLR_StaStStMotorstopp 0;
BA_ "GenSigSendType" SG_ 408 SLR_IstPosMot 0;
BA_ "GenSigStartValue" SG_ 408 SLR_IstPosMot 254;
BA_ "Fehlerwert" SG_ 408 SLR_IstPosMot 255;
BA_ "GenSigSendType" SG_ 408 SLR_StaVerst 0;
BA_ "GenSigSendType" SG_ 408 SLR_StaFehPos 0;
BA_ "GenSigSendType" SG_ 408 SLR_StaReflauf 0;
BA_ "GenSigSendType" SG_ 408 SLR_StaStGlTst 0;
BA_ "GenSigSendType" SG_ 408 SLR_BestFehlosch 0;
BA_ "GenSigSendType" SG_ 408 SLR_StaAFSElMod 0;
BA_ "GenSigSendType" SG_ 408 SLR_StaTieftempFlag 0;
BA_ "GenSigSendType" SG_ 958 Motor_14_CRC 0;
BA_ "GenSigFuncType" SG_ 958 Motor_14_CRC 2;
BA_ "GenSigSendType" SG_ 958 Motor_14_BZ 0;
BA_ "GenSigFuncType" SG_ 958 Motor_14_BZ 1;
BA_ "GenSigSendType" SG_ 958 MO_StartStopp_Status 3;
BA_ "GenSigSendType" SG_ 958 MO_StartStopp_Wiederstart 3;
BA_ "GenSigSendType" SG_ 958 MO_StartStopp_Motorstopp 3;
BA_ "GenSigSendType" SG_ 958 MO_Freig_Reku 0;
BA_ "GenSigSendType" SG_ 958 MO_Kl_75 3;
BA_ "GenSigSendType" SG_ 958 MO_Kl_50 3;
BA_ "GenSigSendType" SG_ 958 MO_Gangposition 3;
BA_ "GenSigStartValue" SG_ 958 MO_Gangposition 14;
BA_ "Fehlerwert" SG_ 958 MO_Gangposition 15;
BA_ "GenSigSendType" SG_ 958 MO_StartStopp_Fahrerwunsch 0;
BA_ "GenSigSendType" SG_ 958 MO_HYB_Fahrbereitschaft 0;
BA_ "GenSigSendType" SG_ 958 MO_Ext_E_Fahrt_aktiv 3;
BA_ "NWM-WakeupAllowed" SG_ 958 MO_Ext_E_Fahrt_aktiv 1;
BA_ "GenSigSendType" SG_ 958 MO_Fahrer_bremst 3;
BA_ "GenSigSendType" SG_ 958 MO_QBit_Fahrer_bremst 3;
BA_ "GenSigStartValue" SG_ 958 MO_QBit_Fahrer_bremst 1;
BA_ "GenSigSendType" SG_ 958 MO_BLS 3;
BA_ "GenSigSendType" SG_ 958 MO_Konsistenz_Bremsped 3;
BA_ "GenSigSendType" SG_ 958 MO_KomFehler_ESP 3;
BA_ "Fehlerwert" SG_ 958 MO_KomFehler_ESP 1;
BA_ "GenSigSendType" SG_ 958 MO_Klima_Eingr 0;
BA_ "GenSigSendType" SG_ 958 MO_Aussp_Anlass 3;
BA_ "GenSigSendType" SG_ 958 MO_Freig_Anlass 3;
BA_ "GenSigSendType" SG_ 958 MO_Kuppl_schalter 3;
BA_ "GenSigSendType" SG_ 958 MO_Interlock 3;
BA_ "GenSigSendType" SG_ 958 MO_Motor_laeuft 3;
BA_ "GenSigSendType" SG_ 958 MO_Kickdown 3;
BA_ "GenSigSendType" SG_ 958 MO_QBit_KL_75 3;
BA_ "GenSigStartValue" SG_ 958 MO_QBit_KL_75 1;
BA_ "GenSigSendType" SG_ 958 MO_EKlKomLeiRed 0;
BA_ "GenSigSendType" SG_ 958 MO_Handshake_STH 0;
BA_ "GenSigSendType" SG_ 958 MO_BKV_Unterdruckwarnung 0;
BA_ "GenSigSendType" SG_ 958 MO_Freigabe_Segeln 0;
BA_ "GenSigSendType" SG_ 958 MO_PTC_Status 0;
BA_ "GenSigSendType" SG_ 958 MO_QBit_Gangposition 3;
BA_ "GenSigStartValue" SG_ 958 MO_QBit_Gangposition 1;
BA_ "GenSigSendType" SG_ 958 MO_Signalquelle_Gangposition 0;
BA_ "GenSigSendType" SG_ 958 MO_Remotestart_Betrieb 3;
BA_ "GenSigSendType" SG_ 958 MO_Remotestart_moeglich 0;
BA_ "GenSigSendType" SG_ 958 MO_FMAus_aktiv 3;
BA_ "GenSigSendType" SG_ 958 MO_FMAus_Startvariante 3;
BA_ "GenSigSendType" SG_ 958 MO_BMS_NV_Anf_stuetzen 3;
BA_ "GenSigSendType" SG_ 958 MO_Zylinderabschaltung 3;
BA_ "GenSigSendType" SG_ 958 MO_HYB_VM_aktiv 3;
BA_ "GenSigSendType" SG_ 958 MO_StartVorauss_erfuellt 3;
BA_ "GenSigStartValue" SG_ 958 MO_StartVorauss_erfuellt 1;
BA_ "GenSigSendType" SG_ 994 MXB_Allgemein_li_defekt 3;
BA_ "Fehlerwert" SG_ 994 MXB_Allgemein_li_defekt 1;
BA_ "GenSigSendType" SG_ 994 MXB_Allgemein_re_defekt 3;
BA_ "Fehlerwert" SG_ 994 MXB_Allgemein_re_defekt 1;
BA_ "GenSigSendType" SG_ 994 MXB_Fernlicht_li_defekt 3;
BA_ "GenSigSendType" SG_ 994 MXB_Fernlicht_re_defekt 3;
BA_ "GenSigSendType" SG_ 994 MXB_Fernlicht_Status 3;
BA_ "GenSigSendType" SG_ 994 MXB_Sicherheitspos_li_Anf 3;
BA_ "GenSigSendType" SG_ 994 MXB_Sicherheitspos_re_Anf 3;
BA_ "GenSigSendType" SG_ 994 MXB_Verfuegbarkeit 3;
BA_ "GenSigSendType" SG_ 994 Kamera_Sensor_blockiert 3;
BA_ "GenSigSendType" SG_ 994 AFS_Allwetterlicht_Unterdrueck 3;
BA_ "GenSigSendType" SG_ 994 AFS_Autobahnlicht_Unterdrueckung 3;
BA_ "GenSigSendType" SG_ 994 AFS_Blinkermode_BVS 3;
BA_ "GenSigSendType" SG_ 994 AFS_Fehlertext_BVS 3;
BA_ "GenSigSendType" SG_ 994 AFS_Lampe_BVS 3;
BA_ "GenSigSendType" SG_ 994 AFS_Stadtlicht_Unterdrueckung 3;
BA_ "GenSigSendType" SG_ 994 MXB_Z_Fernlicht_L_Anf 3;
BA_ "GenSigSendType" SG_ 994 MXB_Z_Fernlicht_L_Schaltart 3;
BA_ "GenSigSendType" SG_ 994 MXB_Z_Fernlicht_R_Anf 3;
BA_ "GenSigSendType" SG_ 994 MXB_Z_Fernlicht_R_Schaltart 3;
BA_ "GenSigSendType" SG_ 2463978604 MXB_Blickwinkel_L 3;
BA_ "GenSigStartValue" SG_ 2463978604 MXB_Blickwinkel_L 254;
BA_ "Fehlerwert" SG_ 2463978604 MXB_Blickwinkel_L 255;
BA_ "GenSigSendType" SG_ 2463978604 MXB_Blickwinkel_R 3;
BA_ "GenSigStartValue" SG_ 2463978604 MXB_Blickwinkel_R 254;
BA_ "Fehlerwert" SG_ 2463978604 MXB_Blickwinkel_R 255;
BA_ "GenSigSendType" SG_ 2463978604 MXB_Baustellenlicht_L_Anf 3;
BA_ "GenSigSwitchedByIgnition" SG_ 2463978604 MXB_Baustellenlicht_L_Anf 0;
BA_ "GenSigSendType" SG_ 2463978604 MXB_Baustellenlicht_R_Anf 3;
BA_ "GenSigSwitchedByIgnition" SG_ 2463978604 MXB_Baustellenlicht_R_Anf 0;
BA_ "GenSigSendType" SG_ 2463978604 MXB_AWL_Sichtweitenanpassung 3;
BA_ "GenSigSwitchedByIgnition" SG_ 2463978604 MXB_AWL_Sichtweitenanpassung 0;
BA_ "Fehlerwert" SG_ 2463978604 MXB_AWL_Sichtweitenanpassung 255;
BA_ "GenSigSendType" SG_ 1358 MXB_L_Fernl_MXB_Def_1 0;
BA_ "Fehlerwert" SG_ 1358 MXB_L_Fernl_MXB_Def_1 1;
BA_ "GenSigSendType" SG_ 1358 MXB_L_Fernl_MXB_Def_2 0;
BA_ "Fehlerwert" SG_ 1358 MXB_L_Fernl_MXB_Def_2 1;
BA_ "GenSigSendType" SG_ 1358 MXB_L_Fernl_MXB_Def_3 0;
BA_ "Fehlerwert" SG_ 1358 MXB_L_Fernl_MXB_Def_3 1;
BA_ "GenSigSendType" SG_ 1358 MXB_L_Fernl_MXB_Def_4 0;
BA_ "Fehlerwert" SG_ 1358 MXB_L_Fernl_MXB_Def_4 1;
BA_ "GenSigSendType" SG_ 1358 MXB_L_Fernl_MXB_Def_5 0;
BA_ "Fehlerwert" SG_ 1358 MXB_L_Fernl_MXB_Def_5 1;
BA_ "GenSigSendType" SG_ 1358 MXB_L_Fernl_MXB_Def_6 0;
BA_ "Fehlerwert" SG_ 1358 MXB_L_Fernl_MXB_Def_6 1;
BA_ "GenSigSendType" SG_ 1358 MXB_L_Fernl_MXB_Def_7 0;
BA_ "Fehlerwert" SG_ 1358 MXB_L_Fernl_MXB_Def_7 1;
BA_ "GenSigSendType" SG_ 1358 MXB_L_Fernl_MXB_Def_Err_Gultig 0;
BA_ "GenSigSendType" SG_ 1358 MXB_L_Allg_Elektr_Def_1 0;
BA_ "Fehlerwert" SG_ 1358 MXB_L_Allg_Elektr_Def_1 1;
BA_ "GenSigSendType" SG_ 1358 MXB_L_Allg_Elektr_Def_2 0;
BA_ "Fehlerwert" SG_ 1358 MXB_L_Allg_Elektr_Def_2 1;
BA_ "GenSigSendType" SG_ 1358 MXB_L_Allg_Elektr_Def_3 0;
BA_ "Fehlerwert" SG_ 1358 MXB_L_Allg_Elektr_Def_3 1;
BA_ "GenSigSendType" SG_ 1358 MXB_L_Allg_Elektr_Def_4 0;
BA_ "Fehlerwert" SG_ 1358 MXB_L_Allg_Elektr_Def_4 1;
BA_ "GenSigSendType" SG_ 1358 MXB_L_Allg_Elektr_Def_5 0;
BA_ "Fehlerwert" SG_ 1358 MXB_L_Allg_Elektr_Def_5 1;
BA_ "GenSigSendType" SG_ 1358 MXB_L_Allg_Elektr_Def_6 0;
BA_ "Fehlerwert" SG_ 1358 MXB_L_Allg_Elektr_Def_6 1;
BA_ "GenSigSendType" SG_ 1358 MXB_L_Allg_Elektr_Def_7 0;
BA_ "Fehlerwert" SG_ 1358 MXB_L_Allg_Elektr_Def_7 1;
BA_ "GenSigSendType" SG_ 1358 MXB_L_Allg_Elektr_Def_8 0;
BA_ "Fehlerwert" SG_ 1358 MXB_L_Allg_Elektr_Def_8 1;
BA_ "GenSigSendType" SG_ 1358 MXB_L_Allg_Elektr_Def_Err_Gultig 0;
BA_ "GenSigSendType" SG_ 1358 MXB_L_Luefter_1_Def_1 0;
BA_ "Fehlerwert" SG_ 1358 MXB_L_Luefter_1_Def_1 1;
BA_ "GenSigSendType" SG_ 1358 MXB_L_Luefter_1_Def_2 0;
BA_ "Fehlerwert" SG_ 1358 MXB_L_Luefter_1_Def_2 1;
BA_ "GenSigSendType" SG_ 1358 MXB_L_Luefter_1_Def_3 0;
BA_ "Fehlerwert" SG_ 1358 MXB_L_Luefter_1_Def_3 1;
BA_ "GenSigSendType" SG_ 1358 MXB_L_Luefter_1_Def_4 0;
BA_ "Fehlerwert" SG_ 1358 MXB_L_Luefter_1_Def_4 1;
BA_ "GenSigSendType" SG_ 1358 MXB_L_Luefter_2_Def_1 0;
BA_ "Fehlerwert" SG_ 1358 MXB_L_Luefter_2_Def_1 1;
BA_ "GenSigSendType" SG_ 1358 MXB_L_Luefter_2_Def_2 0;
BA_ "Fehlerwert" SG_ 1358 MXB_L_Luefter_2_Def_2 1;
BA_ "GenSigSendType" SG_ 1358 MXB_L_Luefter_2_Def_3 0;
BA_ "Fehlerwert" SG_ 1358 MXB_L_Luefter_2_Def_3 1;
BA_ "GenSigSendType" SG_ 1358 MXB_L_Luefter_2_Def_4 0;
BA_ "Fehlerwert" SG_ 1358 MXB_L_Luefter_2_Def_4 1;
BA_ "GenSigSendType" SG_ 1358 MXB_L_Luefter_1_Def_Err_Gultig 0;
BA_ "GenSigSendType" SG_ 1358 MXB_L_Luefter_2_Def_Err_Gultig 0;
BA_ "GenSigSendType" SG_ 1358 MXB_L_Allg_Elektr_Def 0;
BA_ "GenSigSendType" SG_ 1358 MXB_L_Fernl_MXB_Def 0;
BA_REL_ "GenSigTimeoutTime" BU_SG_REL_ AFS SG_ 1389 LED_L_Uspg_Schutz 5000;
BA_REL_ "GenSigTimeoutTime" BU_SG_REL_ BCM1 SG_ 1389 LED_L_Uspg_Schutz 5000;
BA_REL_ "GenSigTimeoutTime" BU_SG_REL_ FCM SG_ 1389 LED_L_Uspg_Schutz 5000;
BA_REL_ "GenSigTimeoutTime" BU_SG_REL_ MXB SG_ 1389 LED_L_Uspg_Schutz 5000;
BA_REL_ "GenSigTimeoutTime" BU_SG_REL_ AFS SG_ 1389 LED_L_Spannung_KL15 5000;
BA_REL_ "GenSigTimeoutTime" BU_SG_REL_ BCM1 SG_ 1389 LED_L_Spannung_KL15 5000;
BA_REL_ "GenSigTimeoutTime" BU_SG_REL_ FCM SG_ 1389 LED_L_Spannung_KL15 5000;
BA_REL_ "GenSigTimeoutTime" BU_SG_REL_ MXB SG_ 1389 LED_L_Spannung_KL15 5000;
BA_REL_ "GenSigTimeoutTime" BU_SG_REL_ AFS SG_ 1389 LED_L_Spannung_KL56a 5000;
BA_REL_ "GenSigTimeoutTime" BU_SG_REL_ BCM1 SG_ 1389 LED_L_Spannung_KL56a 5000;
BA_REL_ "GenSigTimeoutTime" BU_SG_REL_ FCM SG_ 1389 LED_L_Spannung_KL56a 5000;
BA_REL_ "GenSigTimeoutTime" BU_SG_REL_ MXB SG_ 1389 LED_L_Spannung_KL56a 5000;
BA_REL_ "GenSigTimeoutTime" BU_SG_REL_ AFS SG_ 1389 LED_L_Spannung_KL56b 5000;
BA_REL_ "GenSigTimeoutTime" BU_SG_REL_ BCM1 SG_ 1389 LED_L_Spannung_KL56b 5000;
BA_REL_ "GenSigTimeoutTime" BU_SG_REL_ FCM SG_ 1389 LED_L_Spannung_KL56b 5000;
BA_REL_ "GenSigTimeoutTime" BU_SG_REL_ MXB SG_ 1389 LED_L_Spannung_KL56b 5000;
BA_REL_ "GenSigTimeoutTime" BU_SG_REL_ AFS SG_ 1389 LED_L_Spannung_TFL 5000;
BA_REL_ "GenSigTimeoutTime" BU_SG_REL_ BCM1 SG_ 1389 LED_L_Spannung_TFL 5000;
BA_REL_ "GenSigTimeoutTime" BU_SG_REL_ FCM SG_ 1389 LED_L_Spannung_TFL 5000;
BA_REL_ "GenSigTimeoutTime" BU_SG_REL_ MXB SG_ 1389 LED_L_Spannung_TFL 5000;
BA_REL_ "GenSigTimeoutTime" BU_SG_REL_ AFS SG_ 1389 LED_L_Temp_Schutz 5000;
BA_REL_ "GenSigTimeoutTime" BU_SG_REL_ BCM1 SG_ 1389 LED_L_Temp_Schutz 5000;
BA_REL_ "GenSigTimeoutTime" BU_SG_REL_ FCM SG_ 1389 LED_L_Temp_Schutz 5000;
BA_REL_ "GenSigTimeoutTime" BU_SG_REL_ MXB SG_ 1389 LED_L_Temp_Schutz 5000;
BA_REL_ "GenSigTimeoutTime" BU_SG_REL_ AFS SG_ 1389 LED_L_Temp_Mux 5000;
BA_REL_ "GenSigTimeoutTime" BU_SG_REL_ BCM1 SG_ 1389 LED_L_Temp_Mux 5000;
BA_REL_ "GenSigTimeoutTime" BU_SG_REL_ FCM SG_ 1389 LED_L_Temp_Mux 5000;
BA_REL_ "GenSigTimeoutTime" BU_SG_REL_ MXB SG_ 1389 LED_L_Temp_Mux 5000;
BA_REL_ "GenSigTimeoutTime" BU_SG_REL_ AFS SG_ 1389 LED_L_Temp_SG_Intern 5000;
BA_REL_ "GenSigTimeoutTime" BU_SG_REL_ BCM1 SG_ 1389 LED_L_Temp_SG_Intern 5000;
BA_REL_ "GenSigTimeoutTime" BU_SG_REL_ FCM SG_ 1389 LED_L_Temp_SG_Intern 5000;
BA_REL_ "GenSigTimeoutTime" BU_SG_REL_ MXB SG_ 1389 LED_L_Temp_SG_Intern 5000;
BA_REL_ "GenSigTimeoutTime" BU_SG_REL_ AFS SG_ 1389 LED_L_Temp_Kanal1_Master 5000;
BA_REL_ "GenSigTimeoutTime" BU_SG_REL_ BCM1 SG_ 1389 LED_L_Temp_Kanal1_Master 5000;
BA_REL_ "GenSigTimeoutTime" BU_SG_REL_ FCM SG_ 1389 LED_L_Temp_Kanal1_Master 5000;
BA_REL_ "GenSigTimeoutTime" BU_SG_REL_ MXB SG_ 1389 LED_L_Temp_Kanal1_Master 5000;
BA_REL_ "GenSigTimeoutTime" BU_SG_REL_ AFS SG_ 1389 LED_L_Temp_Kanal1_Master2 5000;
BA_REL_ "GenSigTimeoutTime" BU_SG_REL_ BCM1 SG_ 1389 LED_L_Temp_Kanal1_Master2 5000;
BA_REL_ "GenSigTimeoutTime" BU_SG_REL_ FCM SG_ 1389 LED_L_Temp_Kanal1_Master2 5000;
BA_REL_ "GenSigTimeoutTime" BU_SG_REL_ MXB SG_ 1389 LED_L_Temp_Kanal1_Master2 5000;
BA_REL_ "GenSigTimeoutTime" BU_SG_REL_ AFS SG_ 1389 LED_L_Temp_Kanal1_Slave 5000;
BA_REL_ "GenSigTimeoutTime" BU_SG_REL_ BCM1 SG_ 1389 LED_L_Temp_Kanal1_Slave 5000;
BA_REL_ "GenSigTimeoutTime" BU_SG_REL_ FCM SG_ 1389 LED_L_Temp_Kanal1_Slave 5000;
BA_REL_ "GenSigTimeoutTime" BU_SG_REL_ MXB SG_ 1389 LED_L_Temp_Kanal1_Slave 5000;
BA_REL_ "GenSigTimeoutTime" BU_SG_REL_ AFS SG_ 1389 LED_L_Temp_Kanal2_Master 5000;
BA_REL_ "GenSigTimeoutTime" BU_SG_REL_ BCM1 SG_ 1389 LED_L_Temp_Kanal2_Master 5000;
BA_REL_ "GenSigTimeoutTime" BU_SG_REL_ FCM SG_ 1389 LED_L_Temp_Kanal2_Master 5000;
BA_REL_ "GenSigTimeoutTime" BU_SG_REL_ MXB SG_ 1389 LED_L_Temp_Kanal2_Master 5000;
BA_REL_ "GenSigTimeoutTime" BU_SG_REL_ AFS SG_ 1389 LED_L_Temp_Kanal2_Slave 5000;
BA_REL_ "GenSigTimeoutTime" BU_SG_REL_ BCM1 SG_ 1389 LED_L_Temp_Kanal2_Slave 5000;
BA_REL_ "GenSigTimeoutTime" BU_SG_REL_ FCM SG_ 1389 LED_L_Temp_Kanal2_Slave 5000;
BA_REL_ "GenSigTimeoutTime" BU_SG_REL_ MXB SG_ 1389 LED_L_Temp_Kanal2_Slave 5000;
BA_REL_ "GenSigTimeoutTime" BU_SG_REL_ AFS SG_ 1389 LED_L_Temp_Kanal3_Master 5000;
BA_REL_ "GenSigTimeoutTime" BU_SG_REL_ BCM1 SG_ 1389 LED_L_Temp_Kanal3_Master 5000;
BA_REL_ "GenSigTimeoutTime" BU_SG_REL_ FCM SG_ 1389 LED_L_Temp_Kanal3_Master 5000;
BA_REL_ "GenSigTimeoutTime" BU_SG_REL_ MXB SG_ 1389 LED_L_Temp_Kanal3_Master 5000;
BA_REL_ "GenSigTimeoutTime" BU_SG_REL_ AFS SG_ 1389 LED_L_Temp_Kanal3_Slave 5000;
BA_REL_ "GenSigTimeoutTime" BU_SG_REL_ BCM1 SG_ 1389 LED_L_Temp_Kanal3_Slave 5000;
BA_REL_ "GenSigTimeoutTime" BU_SG_REL_ FCM SG_ 1389 LED_L_Temp_Kanal3_Slave 5000;
BA_REL_ "GenSigTimeoutTime" BU_SG_REL_ MXB SG_ 1389 LED_L_Temp_Kanal3_Slave 5000;
BA_REL_ "GenSigTimeoutTime" BU_SG_REL_ AFS SG_ 1395 LED_L_Strom_Kanal1_Master 5000;
BA_REL_ "GenSigTimeoutTime" BU_SG_REL_ BCM1 SG_ 1395 LED_L_Strom_Kanal1_Master 5000;
BA_REL_ "GenSigTimeoutTime" BU_SG_REL_ FCM SG_ 1395 LED_L_Strom_Kanal1_Master 5000;
BA_REL_ "GenSigTimeoutTime" BU_SG_REL_ MXB SG_ 1395 LED_L_Strom_Kanal1_Master 5000;
BA_REL_ "GenSigTimeoutTime" BU_SG_REL_ AFS SG_ 1395 LED_L_Strom_Kanal1_Master2 5000;
BA_REL_ "GenSigTimeoutTime" BU_SG_REL_ BCM1 SG_ 1395 LED_L_Strom_Kanal1_Master2 5000;
BA_REL_ "GenSigTimeoutTime" BU_SG_REL_ FCM SG_ 1395 LED_L_Strom_Kanal1_Master2 5000;
BA_REL_ "GenSigTimeoutTime" BU_SG_REL_ MXB SG_ 1395 LED_L_Strom_Kanal1_Master2 5000;
BA_REL_ "GenSigTimeoutTime" BU_SG_REL_ AFS SG_ 1395 LED_L_Strom_Kanal1_Slave 5000;
BA_REL_ "GenSigTimeoutTime" BU_SG_REL_ BCM1 SG_ 1395 LED_L_Strom_Kanal1_Slave 5000;
BA_REL_ "GenSigTimeoutTime" BU_SG_REL_ FCM SG_ 1395 LED_L_Strom_Kanal1_Slave 5000;
BA_REL_ "GenSigTimeoutTime" BU_SG_REL_ MXB SG_ 1395 LED_L_Strom_Kanal1_Slave 5000;
BA_REL_ "GenSigTimeoutTime" BU_SG_REL_ AFS SG_ 1395 LED_L_Strom_Kanal2_Master 5000;
BA_REL_ "GenSigTimeoutTime" BU_SG_REL_ BCM1 SG_ 1395 LED_L_Strom_Kanal2_Master 5000;
BA_REL_ "GenSigTimeoutTime" BU_SG_REL_ FCM SG_ 1395 LED_L_Strom_Kanal2_Master 5000;
BA_REL_ "GenSigTimeoutTime" BU_SG_REL_ MXB SG_ 1395 LED_L_Strom_Kanal2_Master 5000;
BA_REL_ "GenSigTimeoutTime" BU_SG_REL_ AFS SG_ 1395 LED_L_Strom_Kanal2_Slave 5000;
BA_REL_ "GenSigTimeoutTime" BU_SG_REL_ BCM1 SG_ 1395 LED_L_Strom_Kanal2_Slave 5000;
BA_REL_ "GenSigTimeoutTime" BU_SG_REL_ FCM SG_ 1395 LED_L_Strom_Kanal2_Slave 5000;
BA_REL_ "GenSigTimeoutTime" BU_SG_REL_ MXB SG_ 1395 LED_L_Strom_Kanal2_Slave 5000;
BA_REL_ "GenSigTimeoutTime" BU_SG_REL_ AFS SG_ 1395 LED_L_Strom_Kanal3_Master 5000;
BA_REL_ "GenSigTimeoutTime" BU_SG_REL_ BCM1 SG_ 1395 LED_L_Strom_Kanal3_Master 5000;
BA_REL_ "GenSigTimeoutTime" BU_SG_REL_ FCM SG_ 1395 LED_L_Strom_Kanal3_Master 5000;
BA_REL_ "GenSigTimeoutTime" BU_SG_REL_ MXB SG_ 1395 LED_L_Strom_Kanal3_Master 5000;
BA_REL_ "GenSigTimeoutTime" BU_SG_REL_ AFS SG_ 1395 LED_L_Strom_Kanal3_Slave 5000;
BA_REL_ "GenSigTimeoutTime" BU_SG_REL_ BCM1 SG_ 1395 LED_L_Strom_Kanal3_Slave 5000;
BA_REL_ "GenSigTimeoutTime" BU_SG_REL_ FCM SG_ 1395 LED_L_Strom_Kanal3_Slave 5000;
BA_REL_ "GenSigTimeoutTime" BU_SG_REL_ MXB SG_ 1395 LED_L_Strom_Kanal3_Slave 5000;
BA_REL_ "GenSigTimeoutTime" BU_SG_REL_ AFS SG_ 1395 LED_L_Tag_Nacht_Umschaltung_Sta 5000;
BA_REL_ "GenSigTimeoutTime" BU_SG_REL_ BCM1 SG_ 1395 LED_L_Tag_Nacht_Umschaltung_Sta 5000;
BA_REL_ "GenSigTimeoutTime" BU_SG_REL_ FCM SG_ 1395 LED_L_Tag_Nacht_Umschaltung_Sta 5000;
BA_REL_ "GenSigTimeoutTime" BU_SG_REL_ MXB SG_ 1395 LED_L_Tag_Nacht_Umschaltung_Sta 5000;
BA_REL_ "GenSigTimeoutTime" BU_SG_REL_ AFS SG_ 1390 LED_R_Uspg_Schutz 5000;
BA_REL_ "GenSigTimeoutTime" BU_SG_REL_ BCM1 SG_ 1390 LED_R_Uspg_Schutz 5000;
BA_REL_ "GenSigTimeoutTime" BU_SG_REL_ FCM SG_ 1390 LED_R_Uspg_Schutz 5000;
BA_REL_ "GenSigTimeoutTime" BU_SG_REL_ MXB SG_ 1390 LED_R_Uspg_Schutz 5000;
BA_REL_ "GenSigTimeoutTime" BU_SG_REL_ AFS SG_ 1390 LED_R_Spannung_KL15 5000;
BA_REL_ "GenSigTimeoutTime" BU_SG_REL_ BCM1 SG_ 1390 LED_R_Spannung_KL15 5000;
BA_REL_ "GenSigTimeoutTime" BU_SG_REL_ FCM SG_ 1390 LED_R_Spannung_KL15 5000;
BA_REL_ "GenSigTimeoutTime" BU_SG_REL_ MXB SG_ 1390 LED_R_Spannung_KL15 5000;
BA_REL_ "GenSigTimeoutTime" BU_SG_REL_ AFS SG_ 1390 LED_R_Spannung_KL56a 5000;
BA_REL_ "GenSigTimeoutTime" BU_SG_REL_ BCM1 SG_ 1390 LED_R_Spannung_KL56a 5000;
BA_REL_ "GenSigTimeoutTime" BU_SG_REL_ FCM SG_ 1390 LED_R_Spannung_KL56a 5000;
BA_REL_ "GenSigTimeoutTime" BU_SG_REL_ MXB SG_ 1390 LED_R_Spannung_KL56a 5000;
BA_REL_ "GenSigTimeoutTime" BU_SG_REL_ AFS SG_ 1390 LED_R_Spannung_KL56b 5000;
BA_REL_ "GenSigTimeoutTime" BU_SG_REL_ BCM1 SG_ 1390 LED_R_Spannung_KL56b 5000;
BA_REL_ "GenSigTimeoutTime" BU_SG_REL_ FCM SG_ 1390 LED_R_Spannung_KL56b 5000;
BA_REL_ "GenSigTimeoutTime" BU_SG_REL_ MXB SG_ 1390 LED_R_Spannung_KL56b 5000;
BA_REL_ "GenSigTimeoutTime" BU_SG_REL_ AFS SG_ 1390 LED_R_Spannung_TFL 5000;
BA_REL_ "GenSigTimeoutTime" BU_SG_REL_ BCM1 SG_ 1390 LED_R_Spannung_TFL 5000;
BA_REL_ "GenSigTimeoutTime" BU_SG_REL_ FCM SG_ 1390 LED_R_Spannung_TFL 5000;
BA_REL_ "GenSigTimeoutTime" BU_SG_REL_ MXB SG_ 1390 LED_R_Spannung_TFL 5000;
BA_REL_ "GenSigTimeoutTime" BU_SG_REL_ AFS SG_ 1390 LED_R_Temp_Schutz 5000;
BA_REL_ "GenSigTimeoutTime" BU_SG_REL_ BCM1 SG_ 1390 LED_R_Temp_Schutz 5000;
BA_REL_ "GenSigTimeoutTime" BU_SG_REL_ FCM SG_ 1390 LED_R_Temp_Schutz 5000;
BA_REL_ "GenSigTimeoutTime" BU_SG_REL_ MXB SG_ 1390 LED_R_Temp_Schutz 5000;
BA_REL_ "GenSigTimeoutTime" BU_SG_REL_ AFS SG_ 1390 LED_R_Temp_Mux 5000;
BA_REL_ "GenSigTimeoutTime" BU_SG_REL_ BCM1 SG_ 1390 LED_R_Temp_Mux 5000;
BA_REL_ "GenSigTimeoutTime" BU_SG_REL_ FCM SG_ 1390 LED_R_Temp_Mux 5000;
BA_REL_ "GenSigTimeoutTime" BU_SG_REL_ MXB SG_ 1390 LED_R_Temp_Mux 5000;
BA_REL_ "GenSigTimeoutTime" BU_SG_REL_ AFS SG_ 1390 LED_R_Temp_SG_Intern 5000;
BA_REL_ "GenSigTimeoutTime" BU_SG_REL_ BCM1 SG_ 1390 LED_R_Temp_SG_Intern 5000;
BA_REL_ "GenSigTimeoutTime" BU_SG_REL_ FCM SG_ 1390 LED_R_Temp_SG_Intern 5000;
BA_REL_ "GenSigTimeoutTime" BU_SG_REL_ MXB SG_ 1390 LED_R_Temp_SG_Intern 5000;
BA_REL_ "GenSigTimeoutTime" BU_SG_REL_ AFS SG_ 1390 LED_R_Temp_Kanal1_Master 5000;
BA_REL_ "GenSigTimeoutTime" BU_SG_REL_ BCM1 SG_ 1390 LED_R_Temp_Kanal1_Master 5000;
BA_REL_ "GenSigTimeoutTime" BU_SG_REL_ FCM SG_ 1390 LED_R_Temp_Kanal1_Master 5000;
BA_REL_ "GenSigTimeoutTime" BU_SG_REL_ MXB SG_ 1390 LED_R_Temp_Kanal1_Master 5000;
BA_REL_ "GenSigTimeoutTime" BU_SG_REL_ AFS SG_ 1390 LED_R_Temp_Kanal1_Master2 5000;
BA_REL_ "GenSigTimeoutTime" BU_SG_REL_ BCM1 SG_ 1390 LED_R_Temp_Kanal1_Master2 5000;
BA_REL_ "GenSigTimeoutTime" BU_SG_REL_ FCM SG_ 1390 LED_R_Temp_Kanal1_Master2 5000;
BA_REL_ "GenSigTimeoutTime" BU_SG_REL_ MXB SG_ 1390 LED_R_Temp_Kanal1_Master2 5000;
BA_REL_ "GenSigTimeoutTime" BU_SG_REL_ AFS SG_ 1390 LED_R_Temp_Kanal1_Slave 5000;
BA_REL_ "GenSigTimeoutTime" BU_SG_REL_ BCM1 SG_ 1390 LED_R_Temp_Kanal1_Slave 5000;
BA_REL_ "GenSigTimeoutTime" BU_SG_REL_ FCM SG_ 1390 LED_R_Temp_Kanal1_Slave 5000;
BA_REL_ "GenSigTimeoutTime" BU_SG_REL_ MXB SG_ 1390 LED_R_Temp_Kanal1_Slave 5000;
BA_REL_ "GenSigTimeoutTime" BU_SG_REL_ AFS SG_ 1390 LED_R_Temp_Kanal2_Master 5000;
BA_REL_ "GenSigTimeoutTime" BU_SG_REL_ BCM1 SG_ 1390 LED_R_Temp_Kanal2_Master 5000;
BA_REL_ "GenSigTimeoutTime" BU_SG_REL_ FCM SG_ 1390 LED_R_Temp_Kanal2_Master 5000;
BA_REL_ "GenSigTimeoutTime" BU_SG_REL_ MXB SG_ 1390 LED_R_Temp_Kanal2_Master 5000;
BA_REL_ "GenSigTimeoutTime" BU_SG_REL_ AFS SG_ 1390 LED_R_Temp_Kanal2_Slave 5000;
BA_REL_ "GenSigTimeoutTime" BU_SG_REL_ BCM1 SG_ 1390 LED_R_Temp_Kanal2_Slave 5000;
BA_REL_ "GenSigTimeoutTime" BU_SG_REL_ FCM SG_ 1390 LED_R_Temp_Kanal2_Slave 5000;
BA_REL_ "GenSigTimeoutTime" BU_SG_REL_ MXB SG_ 1390 LED_R_Temp_Kanal2_Slave 5000;
BA_REL_ "GenSigTimeoutTime" BU_SG_REL_ AFS SG_ 1390 LED_R_Temp_Kanal3_Master 5000;
BA_REL_ "GenSigTimeoutTime" BU_SG_REL_ BCM1 SG_ 1390 LED_R_Temp_Kanal3_Master 5000;
BA_REL_ "GenSigTimeoutTime" BU_SG_REL_ FCM SG_ 1390 LED_R_Temp_Kanal3_Master 5000;
BA_REL_ "GenSigTimeoutTime" BU_SG_REL_ MXB SG_ 1390 LED_R_Temp_Kanal3_Master 5000;
BA_REL_ "GenSigTimeoutTime" BU_SG_REL_ AFS SG_ 1390 LED_R_Temp_Kanal3_Slave 5000;
BA_REL_ "GenSigTimeoutTime" BU_SG_REL_ BCM1 SG_ 1390 LED_R_Temp_Kanal3_Slave 5000;
BA_REL_ "GenSigTimeoutTime" BU_SG_REL_ FCM SG_ 1390 LED_R_Temp_Kanal3_Slave 5000;
BA_REL_ "GenSigTimeoutTime" BU_SG_REL_ MXB SG_ 1390 LED_R_Temp_Kanal3_Slave 5000;
BA_REL_ "GenSigTimeoutTime" BU_SG_REL_ AFS SG_ 1396 LED_R_Strom_Kanal1_Master 5000;
BA_REL_ "GenSigTimeoutTime" BU_SG_REL_ BCM1 SG_ 1396 LED_R_Strom_Kanal1_Master 5000;
BA_REL_ "GenSigTimeoutTime" BU_SG_REL_ FCM SG_ 1396 LED_R_Strom_Kanal1_Master 5000;
BA_REL_ "GenSigTimeoutTime" BU_SG_REL_ MXB SG_ 1396 LED_R_Strom_Kanal1_Master 5000;
BA_REL_ "GenSigTimeoutTime" BU_SG_REL_ AFS SG_ 1396 LED_R_Strom_Kanal1_Master2 5000;
BA_REL_ "GenSigTimeoutTime" BU_SG_REL_ BCM1 SG_ 1396 LED_R_Strom_Kanal1_Master2 5000;
BA_REL_ "GenSigTimeoutTime" BU_SG_REL_ FCM SG_ 1396 LED_R_Strom_Kanal1_Master2 5000;
BA_REL_ "GenSigTimeoutTime" BU_SG_REL_ MXB SG_ 1396 LED_R_Strom_Kanal1_Master2 5000;
BA_REL_ "GenSigTimeoutTime" BU_SG_REL_ AFS SG_ 1396 LED_R_Strom_Kanal1_Slave 5000;
BA_REL_ "GenSigTimeoutTime" BU_SG_REL_ BCM1 SG_ 1396 LED_R_Strom_Kanal1_Slave 5000;
BA_REL_ "GenSigTimeoutTime" BU_SG_REL_ FCM SG_ 1396 LED_R_Strom_Kanal1_Slave 5000;
BA_REL_ "GenSigTimeoutTime" BU_SG_REL_ MXB SG_ 1396 LED_R_Strom_Kanal1_Slave 5000;
BA_REL_ "GenSigTimeoutTime" BU_SG_REL_ AFS SG_ 1396 LED_R_Strom_Kanal2_Master 5000;
BA_REL_ "GenSigTimeoutTime" BU_SG_REL_ BCM1 SG_ 1396 LED_R_Strom_Kanal2_Master 5000;
BA_REL_ "GenSigTimeoutTime" BU_SG_REL_ FCM SG_ 1396 LED_R_Strom_Kanal2_Master 5000;
BA_REL_ "GenSigTimeoutTime" BU_SG_REL_ MXB SG_ 1396 LED_R_Strom_Kanal2_Master 5000;
BA_REL_ "GenSigTimeoutTime" BU_SG_REL_ AFS SG_ 1396 LED_R_Strom_Kanal2_Slave 5000;
BA_REL_ "GenSigTimeoutTime" BU_SG_REL_ BCM1 SG_ 1396 LED_R_Strom_Kanal2_Slave 5000;
BA_REL_ "GenSigTimeoutTime" BU_SG_REL_ FCM SG_ 1396 LED_R_Strom_Kanal2_Slave 5000;
BA_REL_ "GenSigTimeoutTime" BU_SG_REL_ MXB SG_ 1396 LED_R_Strom_Kanal2_Slave 5000;
BA_REL_ "GenSigTimeoutTime" BU_SG_REL_ AFS SG_ 1396 LED_R_Strom_Kanal3_Master 5000;
BA_REL_ "GenSigTimeoutTime" BU_SG_REL_ BCM1 SG_ 1396 LED_R_Strom_Kanal3_Master 5000;
BA_REL_ "GenSigTimeoutTime" BU_SG_REL_ FCM SG_ 1396 LED_R_Strom_Kanal3_Master 5000;
BA_REL_ "GenSigTimeoutTime" BU_SG_REL_ MXB SG_ 1396 LED_R_Strom_Kanal3_Master 5000;
BA_REL_ "GenSigTimeoutTime" BU_SG_REL_ AFS SG_ 1396 LED_R_Strom_Kanal3_Slave 5000;
BA_REL_ "GenSigTimeoutTime" BU_SG_REL_ BCM1 SG_ 1396 LED_R_Strom_Kanal3_Slave 5000;
BA_REL_ "GenSigTimeoutTime" BU_SG_REL_ FCM SG_ 1396 LED_R_Strom_Kanal3_Slave 5000;
BA_REL_ "GenSigTimeoutTime" BU_SG_REL_ MXB SG_ 1396 LED_R_Strom_Kanal3_Slave 5000;
BA_REL_ "GenSigTimeoutTime" BU_SG_REL_ AFS SG_ 1396 LED_R_Tag_Nacht_Umschaltung_Sta 5000;
BA_REL_ "GenSigTimeoutTime" BU_SG_REL_ BCM1 SG_ 1396 LED_R_Tag_Nacht_Umschaltung_Sta 5000;
BA_REL_ "GenSigTimeoutTime" BU_SG_REL_ FCM SG_ 1396 LED_R_Tag_Nacht_Umschaltung_Sta 5000;
BA_REL_ "GenSigTimeoutTime" BU_SG_REL_ MXB SG_ 1396 LED_R_Tag_Nacht_Umschaltung_Sta 5000;
BA_REL_ "GenSigTimeoutTime" BU_SG_REL_ LED_DK3_LM_R SG_ 2589283616 LED_R_DABL_LED_01_Anf 2000;
BA_REL_ "GenSigTimeoutTime" BU_SG_REL_ LLP_R SG_ 2589283616 LED_R_DABL_LED_01_Anf 2000;
BA_REL_ "GenSigTimeoutTime" BU_SG_REL_ LED_DK3_LM_R SG_ 2589283616 LED_R_DABL_LED_02_Anf 2000;
BA_REL_ "GenSigTimeoutTime" BU_SG_REL_ LLP_R SG_ 2589283616 LED_R_DABL_LED_02_Anf 2000;
BA_REL_ "GenSigTimeoutTime" BU_SG_REL_ LED_DK3_LM_R SG_ 2589283616 LED_R_DABL_LED_03_Anf 2000;
BA_REL_ "GenSigTimeoutTime" BU_SG_REL_ LLP_R SG_ 2589283616 LED_R_DABL_LED_03_Anf 2000;
BA_REL_ "GenSigTimeoutTime" BU_SG_REL_ LED_DK3_LM_R SG_ 2589283616 LED_R_DABL_LED_04_Anf 2000;
BA_REL_ "GenSigTimeoutTime" BU_SG_REL_ LLP_R SG_ 2589283616 LED_R_DABL_LED_04_Anf 2000;
BA_REL_ "GenSigTimeoutTime" BU_SG_REL_ LED_DK3_LM_R SG_ 2589283616 LED_R_DABL_LED_05_Anf 2000;
BA_REL_ "GenSigTimeoutTime" BU_SG_REL_ LLP_R SG_ 2589283616 LED_R_DABL_LED_05_Anf 2000;
BA_REL_ "GenSigTimeoutTime" BU_SG_REL_ LED_DK3_LM_R SG_ 2589283616 LED_R_DABL_LED_06_Anf 2000;
BA_REL_ "GenSigTimeoutTime" BU_SG_REL_ LLP_R SG_ 2589283616 LED_R_DABL_LED_06_Anf 2000;
BA_REL_ "GenSigTimeoutTime" BU_SG_REL_ LED_DK3_LM_R SG_ 2589283616 LED_R_DABL_LED_07_Anf 2000;
BA_REL_ "GenSigTimeoutTime" BU_SG_REL_ LLP_R SG_ 2589283616 LED_R_DABL_LED_07_Anf 2000;
BA_REL_ "GenSigTimeoutTime" BU_SG_REL_ LED_DK3_LM_R SG_ 2589283616 LED_R_DABL_LED_08_Anf 2000;
BA_REL_ "GenSigTimeoutTime" BU_SG_REL_ LLP_R SG_ 2589283616 LED_R_DABL_LED_08_Anf 2000;
BA_REL_ "GenSigTimeoutTime" BU_SG_REL_ LED_DK3_LM_R SG_ 2589283616 LED_R_DABL_LED_09_Anf 2000;
BA_REL_ "GenSigTimeoutTime" BU_SG_REL_ LLP_R SG_ 2589283616 LED_R_DABL_LED_09_Anf 2000;
BA_REL_ "GenSigTimeoutTime" BU_SG_REL_ LED_DK3_LM_R SG_ 2589283616 LED_R_DABL_LED_10_Anf 2000;
BA_REL_ "GenSigTimeoutTime" BU_SG_REL_ LLP_R SG_ 2589283616 LED_R_DABL_LED_10_Anf 2000;
BA_REL_ "GenSigTimeoutTime" BU_SG_REL_ LED_DK3_LM_R SG_ 2463978601 LED_R_DABL_LED_11_Anf 2000;
BA_REL_ "GenSigTimeoutTime" BU_SG_REL_ LLP_R SG_ 2463978601 LED_R_DABL_LED_11_Anf 2000;
BA_REL_ "GenSigTimeoutTime" BU_SG_REL_ LED_DK3_LM_R SG_ 2463978601 LED_R_DABL_LED_12_Anf 2000;
BA_REL_ "GenSigTimeoutTime" BU_SG_REL_ LLP_R SG_ 2463978601 LED_R_DABL_LED_12_Anf 2000;
BA_REL_ "GenSigTimeoutTime" BU_SG_REL_ LED_DK3_LM_R SG_ 2463978601 LED_R_DABL_LED_13_Anf 2000;
BA_REL_ "GenSigTimeoutTime" BU_SG_REL_ LLP_R SG_ 2463978601 LED_R_DABL_LED_13_Anf 2000;
BA_REL_ "GenSigTimeoutTime" BU_SG_REL_ LED_DK3_LM_R SG_ 2463978601 LED_R_DABL_LED_14_Anf 2000;
BA_REL_ "GenSigTimeoutTime" BU_SG_REL_ LLP_R SG_ 2463978601 LED_R_DABL_LED_14_Anf 2000;
BA_REL_ "GenSigTimeoutTime" BU_SG_REL_ LED_DK3_LM_R SG_ 2463978601 LED_R_DABL_LED_15_Anf 2000;
BA_REL_ "GenSigTimeoutTime" BU_SG_REL_ LLP_R SG_ 2463978601 LED_R_DABL_LED_15_Anf 2000;
BA_REL_ "GenSigTimeoutTime" BU_SG_REL_ LED_DK3_LM_R SG_ 2463978601 LED_R_DABL_LED_16_Anf 2000;
BA_REL_ "GenSigTimeoutTime" BU_SG_REL_ LLP_R SG_ 2463978601 LED_R_DABL_LED_16_Anf 2000;
BA_REL_ "GenSigTimeoutTime" BU_SG_REL_ LED_DK3_LM_R SG_ 2463978601 LED_R_DABL_LED_17_Anf 2000;
BA_REL_ "GenSigTimeoutTime" BU_SG_REL_ LLP_R SG_ 2463978601 LED_R_DABL_LED_17_Anf 2000;
BA_REL_ "GenSigTimeoutTime" BU_SG_REL_ LED_DK3_LM_R SG_ 2463978601 LED_R_DABL_LED_18_Anf 2000;
BA_REL_ "GenSigTimeoutTime" BU_SG_REL_ LLP_R SG_ 2463978601 LED_R_DABL_LED_18_Anf 2000;
BA_REL_ "GenSigTimeoutTime" BU_SG_REL_ LED_DK3_LM_R SG_ 2463978601 LED_R_DABL_LED_19_Anf 2000;
BA_REL_ "GenSigTimeoutTime" BU_SG_REL_ LLP_R SG_ 2463978601 LED_R_DABL_LED_19_Anf 2000;
BA_REL_ "GenSigTimeoutTime" BU_SG_REL_ LED_DK3_LM_R SG_ 2463978601 LED_R_DABL_LED_20_Anf 2000;
BA_REL_ "GenSigTimeoutTime" BU_SG_REL_ LLP_R SG_ 2463978601 LED_R_DABL_LED_20_Anf 2000;
BA_REL_ "GenSigTimeoutTime" BU_SG_REL_ LED_DK3_LM_R SG_ 837 LED_R_SABL_LED_01_Anf 2000;
BA_REL_ "GenSigTimeoutTime" BU_SG_REL_ LLP_R SG_ 837 LED_R_SABL_LED_01_Anf 2000;
BA_REL_ "GenSigTimeoutTime" BU_SG_REL_ LED_DK3_LM_R SG_ 837 LED_R_SABL_LED_02_Anf 2000;
BA_REL_ "GenSigTimeoutTime" BU_SG_REL_ LLP_R SG_ 837 LED_R_SABL_LED_02_Anf 2000;
BA_REL_ "GenSigTimeoutTime" BU_SG_REL_ LED_DK3_LM_R SG_ 837 LED_R_SABL_LED_03_Anf 2000;
BA_REL_ "GenSigTimeoutTime" BU_SG_REL_ LLP_R SG_ 837 LED_R_SABL_LED_03_Anf 2000;
BA_REL_ "GenSigTimeoutTime" BU_SG_REL_ LED_DK3_LM_R SG_ 837 LED_R_SABL_LED_04_Anf 2000;
BA_REL_ "GenSigTimeoutTime" BU_SG_REL_ LLP_R SG_ 837 LED_R_SABL_LED_04_Anf 2000;
BA_REL_ "GenSigTimeoutTime" BU_SG_REL_ LED_DK3_LM_R SG_ 837 LED_R_SABL_LED_05_Anf 2000;
BA_REL_ "GenSigTimeoutTime" BU_SG_REL_ LLP_R SG_ 837 LED_R_SABL_LED_05_Anf 2000;
BA_REL_ "GenSigTimeoutTime" BU_SG_REL_ LED_DK3_LM_R SG_ 837 LED_R_SABL_LED_06_Anf 2000;
BA_REL_ "GenSigTimeoutTime" BU_SG_REL_ LLP_R SG_ 837 LED_R_SABL_LED_06_Anf 2000;
BA_REL_ "GenSigTimeoutTime" BU_SG_REL_ LED_DK3_LM_R SG_ 837 LED_R_SABL_LED_07_Anf 2000;
BA_REL_ "GenSigTimeoutTime" BU_SG_REL_ LLP_R SG_ 837 LED_R_SABL_LED_07_Anf 2000;
BA_REL_ "GenSigTimeoutTime" BU_SG_REL_ LED_DK3_LM_R SG_ 837 LED_R_SABL_LED_08_Anf 2000;
BA_REL_ "GenSigTimeoutTime" BU_SG_REL_ LLP_R SG_ 837 LED_R_SABL_LED_08_Anf 2000;
BA_REL_ "GenSigTimeoutTime" BU_SG_REL_ LED_DK3_LM_R SG_ 837 LED_R_SABL_LED_09_Anf 2000;
BA_REL_ "GenSigTimeoutTime" BU_SG_REL_ LLP_R SG_ 837 LED_R_SABL_LED_09_Anf 2000;
BA_REL_ "GenSigTimeoutTime" BU_SG_REL_ LED_DK3_LM_R SG_ 837 LED_R_SABL_LED_10_Anf 2000;
BA_REL_ "GenSigTimeoutTime" BU_SG_REL_ LLP_R SG_ 837 LED_R_SABL_LED_10_Anf 2000;
BA_REL_ "GenSigTimeoutTime" BU_SG_REL_ LCM_L SG_ 404 LED_L_Abblendl_Anf 500;
BA_REL_ "GenSigTimeoutTime" BU_SG_REL_ LED_DK3_LM_L SG_ 404 LED_L_Abblendl_Anf 500;
BA_REL_ "GenSigTimeoutTime" BU_SG_REL_ LED_LM_L SG_ 404 LED_L_Abblendl_Anf 500;
BA_REL_ "GenSigTimeoutTime" BU_SG_REL_ LLP_L SG_ 404 LED_L_Abblendl_Anf 500;
BA_REL_ "GenSigTimeoutTime" BU_SG_REL_ LED_DK3_LM_L SG_ 404 LED_L_Abblendl_Schaltart 500;
BA_REL_ "GenSigTimeoutTime" BU_SG_REL_ LED_LM_L SG_ 404 LED_L_Abblendl_Schaltart 500;
BA_REL_ "GenSigTimeoutTime" BU_SG_REL_ LLP_L SG_ 404 LED_L_Abblendl_Schaltart 500;
BA_REL_ "GenSigTimeoutTime" BU_SG_REL_ LCM_R SG_ 404 LED_R_Abblendl_Anf 500;
BA_REL_ "GenSigTimeoutTime" BU_SG_REL_ LED_DK3_LM_R SG_ 404 LED_R_Abblendl_Anf 500;
BA_REL_ "GenSigTimeoutTime" BU_SG_REL_ LED_LM_R SG_ 404 LED_R_Abblendl_Anf 500;
BA_REL_ "GenSigTimeoutTime" BU_SG_REL_ LLP_R SG_ 404 LED_R_Abblendl_Anf 500;
BA_REL_ "GenSigTimeoutTime" BU_SG_REL_ LED_DK3_LM_R SG_ 404 LED_R_Abblendl_Schaltart 500;
BA_REL_ "GenSigTimeoutTime" BU_SG_REL_ LED_LM_R SG_ 404 LED_R_Abblendl_Schaltart 500;
BA_REL_ "GenSigTimeoutTime" BU_SG_REL_ LLP_R SG_ 404 LED_R_Abblendl_Schaltart 500;
BA_REL_ "GenSigTimeoutTime" BU_SG_REL_ LED_DK3_LM_L SG_ 404 LED_L_Fernl_LH_Anf 500;
BA_REL_ "GenSigTimeoutTime" BU_SG_REL_ LED_LM_L SG_ 404 LED_L_Fernl_LH_Anf 500;
BA_REL_ "GenSigTimeoutTime" BU_SG_REL_ LLP_L SG_ 404 LED_L_Fernl_LH_Anf 500;
BA_REL_ "GenSigTimeoutTime" BU_SG_REL_ LED_DK3_LM_L SG_ 404 LED_L_Fernl_LH_Schaltart 500;
BA_REL_ "GenSigTimeoutTime" BU_SG_REL_ LED_LM_L SG_ 404 LED_L_Fernl_LH_Schaltart 500;
BA_REL_ "GenSigTimeoutTime" BU_SG_REL_ LLP_L SG_ 404 LED_L_Fernl_LH_Schaltart 500;
BA_REL_ "GenSigTimeoutTime" BU_SG_REL_ LED_DK3_LM_R SG_ 404 LED_R_Fernl_LH_Anf 500;
BA_REL_ "GenSigTimeoutTime" BU_SG_REL_ LED_LM_R SG_ 404 LED_R_Fernl_LH_Anf 500;
BA_REL_ "GenSigTimeoutTime" BU_SG_REL_ LLP_R SG_ 404 LED_R_Fernl_LH_Anf 500;
BA_REL_ "GenSigTimeoutTime" BU_SG_REL_ LED_DK3_LM_R SG_ 404 LED_R_Fernl_LH_Schaltart 500;
BA_REL_ "GenSigTimeoutTime" BU_SG_REL_ LED_LM_R SG_ 404 LED_R_Fernl_LH_Schaltart 500;
BA_REL_ "GenSigTimeoutTime" BU_SG_REL_ LLP_R SG_ 404 LED_R_Fernl_LH_Schaltart 500;
BA_REL_ "GenSigTimeoutTime" BU_SG_REL_ LED_DK3_LM_L SG_ 404 LED_L_Nebel_All_Anf 500;
BA_REL_ "GenSigTimeoutTime" BU_SG_REL_ LED_LM_L SG_ 404 LED_L_Nebel_All_Anf 500;
BA_REL_ "GenSigTimeoutTime" BU_SG_REL_ LLP_L SG_ 404 LED_L_Nebel_All_Anf 500;
BA_REL_ "GenSigTimeoutTime" BU_SG_REL_ LED_DK3_LM_L SG_ 404 LED_L_Nebel_All_Schaltart 500;
BA_REL_ "GenSigTimeoutTime" BU_SG_REL_ LED_LM_L SG_ 404 LED_L_Nebel_All_Schaltart 500;
BA_REL_ "GenSigTimeoutTime" BU_SG_REL_ LLP_L SG_ 404 LED_L_Nebel_All_Schaltart 500;
BA_REL_ "GenSigTimeoutTime" BU_SG_REL_ LED_DK3_LM_R SG_ 404 LED_R_Nebel_All_Anf 500;
BA_REL_ "GenSigTimeoutTime" BU_SG_REL_ LED_LM_R SG_ 404 LED_R_Nebel_All_Anf 500;
BA_REL_ "GenSigTimeoutTime" BU_SG_REL_ LLP_R SG_ 404 LED_R_Nebel_All_Anf 500;
BA_REL_ "GenSigTimeoutTime" BU_SG_REL_ LED_DK3_LM_R SG_ 404 LED_R_Nebel_All_Schaltart 500;
BA_REL_ "GenSigTimeoutTime" BU_SG_REL_ LED_LM_R SG_ 404 LED_R_Nebel_All_Schaltart 500;
BA_REL_ "GenSigTimeoutTime" BU_SG_REL_ LLP_R SG_ 404 LED_R_Nebel_All_Schaltart 500;
BA_REL_ "GenSigTimeoutTime" BU_SG_REL_ LED_LM_L SG_ 404 LED_Sta_Diag 500;
BA_REL_ "GenSigTimeoutTime" BU_SG_REL_ LED_LM_R SG_ 404 LED_Sta_Diag 500;
BA_REL_ "GenSigTimeoutTime" BU_SG_REL_ LED_DK3_LM_L SG_ 404 LED_L_Zus_Fernl_LH_Anf 500;
BA_REL_ "GenSigTimeoutTime" BU_SG_REL_ LED_LM_L SG_ 404 LED_L_Zus_Fernl_LH_Anf 500;
BA_REL_ "GenSigTimeoutTime" BU_SG_REL_ LLP_L SG_ 404 LED_L_Zus_Fernl_LH_Anf 500;
BA_REL_ "GenSigTimeoutTime" BU_SG_REL_ LED_DK3_LM_L SG_ 404 LED_L_Zus_Fernl_LH_Schaltart 500;
BA_REL_ "GenSigTimeoutTime" BU_SG_REL_ LED_LM_L SG_ 404 LED_L_Zus_Fernl_LH_Schaltart 500;
BA_REL_ "GenSigTimeoutTime" BU_SG_REL_ LLP_L SG_ 404 LED_L_Zus_Fernl_LH_Schaltart 500;
BA_REL_ "GenSigTimeoutTime" BU_SG_REL_ LED_DK3_LM_R SG_ 404 LED_R_Zus_Fernl_LH_Anf 500;
BA_REL_ "GenSigTimeoutTime" BU_SG_REL_ LED_LM_R SG_ 404 LED_R_Zus_Fernl_LH_Anf 500;
BA_REL_ "GenSigTimeoutTime" BU_SG_REL_ LLP_R SG_ 404 LED_R_Zus_Fernl_LH_Anf 500;
BA_REL_ "GenSigTimeoutTime" BU_SG_REL_ LED_DK3_LM_R SG_ 404 LED_R_Zus_Fernl_LH_Schaltart 500;
BA_REL_ "GenSigTimeoutTime" BU_SG_REL_ LED_LM_R SG_ 404 LED_R_Zus_Fernl_LH_Schaltart 500;
BA_REL_ "GenSigTimeoutTime" BU_SG_REL_ LLP_R SG_ 404 LED_R_Zus_Fernl_LH_Schaltart 500;
BA_REL_ "GenSigTimeoutTime" BU_SG_REL_ LED_DK3_LM_L SG_ 405 LED_L_Abbiegel_Anf 500;
BA_REL_ "GenSigTimeoutTime" BU_SG_REL_ LED_LM_L SG_ 405 LED_L_Abbiegel_Anf 500;
BA_REL_ "GenSigTimeoutTime" BU_SG_REL_ LLP_L SG_ 405 LED_L_Abbiegel_Anf 500;
BA_REL_ "GenSigTimeoutTime" BU_SG_REL_ LED_DK3_LM_L SG_ 405 LED_L_Abbiegel_Schaltart 500;
BA_REL_ "GenSigTimeoutTime" BU_SG_REL_ LED_LM_L SG_ 405 LED_L_Abbiegel_Schaltart 500;
BA_REL_ "GenSigTimeoutTime" BU_SG_REL_ LLP_L SG_ 405 LED_L_Abbiegel_Schaltart 500;
BA_REL_ "GenSigTimeoutTime" BU_SG_REL_ LED_DK3_LM_R SG_ 405 LED_R_Abbiegel_Anf 500;
BA_REL_ "GenSigTimeoutTime" BU_SG_REL_ LED_LM_R SG_ 405 LED_R_Abbiegel_Anf 500;
BA_REL_ "GenSigTimeoutTime" BU_SG_REL_ LLP_R SG_ 405 LED_R_Abbiegel_Anf 500;
BA_REL_ "GenSigTimeoutTime" BU_SG_REL_ LED_DK3_LM_R SG_ 405 LED_R_Abbiegel_Schaltart 500;
BA_REL_ "GenSigTimeoutTime" BU_SG_REL_ LED_LM_R SG_ 405 LED_R_Abbiegel_Schaltart 500;
BA_REL_ "GenSigTimeoutTime" BU_SG_REL_ LLP_R SG_ 405 LED_R_Abbiegel_Schaltart 500;
BA_REL_ "GenSigTimeoutTime" BU_SG_REL_ LED_DK3_LM_L SG_ 405 LED_L_Autobahnl_Anf 500;
BA_REL_ "GenSigTimeoutTime" BU_SG_REL_ LED_LM_L SG_ 405 LED_L_Autobahnl_Anf 500;
BA_REL_ "GenSigTimeoutTime" BU_SG_REL_ LLP_L SG_ 405 LED_L_Autobahnl_Anf 500;
BA_REL_ "GenSigTimeoutTime" BU_SG_REL_ LED_DK3_LM_L SG_ 405 LED_L_Autobahnl_Schaltart 500;
BA_REL_ "GenSigTimeoutTime" BU_SG_REL_ LED_LM_L SG_ 405 LED_L_Autobahnl_Schaltart 500;
BA_REL_ "GenSigTimeoutTime" BU_SG_REL_ LLP_L SG_ 405 LED_L_Autobahnl_Schaltart 500;
BA_REL_ "GenSigTimeoutTime" BU_SG_REL_ LED_DK3_LM_R SG_ 405 LED_R_Autobahnl_Anf 500;
BA_REL_ "GenSigTimeoutTime" BU_SG_REL_ LED_LM_R SG_ 405 LED_R_Autobahnl_Anf 500;
BA_REL_ "GenSigTimeoutTime" BU_SG_REL_ LLP_R SG_ 405 LED_R_Autobahnl_Anf 500;
BA_REL_ "GenSigTimeoutTime" BU_SG_REL_ LED_DK3_LM_R SG_ 405 LED_R_Autobahnl_Schaltart 500;
BA_REL_ "GenSigTimeoutTime" BU_SG_REL_ LED_LM_R SG_ 405 LED_R_Autobahnl_Schaltart 500;
BA_REL_ "GenSigTimeoutTime" BU_SG_REL_ LLP_R SG_ 405 LED_R_Autobahnl_Schaltart 500;
BA_REL_ "GenSigTimeoutTime" BU_SG_REL_ LED_DK3_LM_L SG_ 405 LED_L_Eco_Mode_1_Anf 500;
BA_REL_ "GenSigTimeoutTime" BU_SG_REL_ LED_LM_L SG_ 405 LED_L_Eco_Mode_1_Anf 500;
BA_REL_ "GenSigTimeoutTime" BU_SG_REL_ LLP_L SG_ 405 LED_L_Eco_Mode_1_Anf 500;
BA_REL_ "GenSigTimeoutTime" BU_SG_REL_ LED_DK3_LM_L SG_ 405 LED_L_Eco_Mode_1_Schaltart 500;
BA_REL_ "GenSigTimeoutTime" BU_SG_REL_ LED_LM_L SG_ 405 LED_L_Eco_Mode_1_Schaltart 500;
BA_REL_ "GenSigTimeoutTime" BU_SG_REL_ LLP_L SG_ 405 LED_L_Eco_Mode_1_Schaltart 500;
BA_REL_ "GenSigTimeoutTime" BU_SG_REL_ LED_DK3_LM_R SG_ 405 LED_R_Eco_Mode_1_Anf 500;
BA_REL_ "GenSigTimeoutTime" BU_SG_REL_ LED_LM_R SG_ 405 LED_R_Eco_Mode_1_Anf 500;
BA_REL_ "GenSigTimeoutTime" BU_SG_REL_ LLP_R SG_ 405 LED_R_Eco_Mode_1_Anf 500;
BA_REL_ "GenSigTimeoutTime" BU_SG_REL_ LED_DK3_LM_R SG_ 405 LED_R_Eco_Mode_1_Schaltart 500;
BA_REL_ "GenSigTimeoutTime" BU_SG_REL_ LED_LM_R SG_ 405 LED_R_Eco_Mode_1_Schaltart 500;
BA_REL_ "GenSigTimeoutTime" BU_SG_REL_ LLP_R SG_ 405 LED_R_Eco_Mode_1_Schaltart 500;
BA_REL_ "GenSigTimeoutTime" BU_SG_REL_ LED_DK3_LM_L SG_ 405 LED_L_Eco_Mode_2_Anf 500;
BA_REL_ "GenSigTimeoutTime" BU_SG_REL_ LED_LM_L SG_ 405 LED_L_Eco_Mode_2_Anf 500;
BA_REL_ "GenSigTimeoutTime" BU_SG_REL_ LLP_L SG_ 405 LED_L_Eco_Mode_2_Anf 500;
BA_REL_ "GenSigTimeoutTime" BU_SG_REL_ LED_DK3_LM_L SG_ 405 LED_L_Eco_Mode_2_Schaltart 500;
BA_REL_ "GenSigTimeoutTime" BU_SG_REL_ LED_LM_L SG_ 405 LED_L_Eco_Mode_2_Schaltart 500;
BA_REL_ "GenSigTimeoutTime" BU_SG_REL_ LLP_L SG_ 405 LED_L_Eco_Mode_2_Schaltart 500;
BA_REL_ "GenSigTimeoutTime" BU_SG_REL_ LED_DK3_LM_R SG_ 405 LED_R_Eco_Mode_2_Anf 500;
BA_REL_ "GenSigTimeoutTime" BU_SG_REL_ LED_LM_R SG_ 405 LED_R_Eco_Mode_2_Anf 500;
BA_REL_ "GenSigTimeoutTime" BU_SG_REL_ LLP_R SG_ 405 LED_R_Eco_Mode_2_Anf 500;
BA_REL_ "GenSigTimeoutTime" BU_SG_REL_ LED_DK3_LM_R SG_ 405 LED_R_Eco_Mode_2_Schaltart 500;
BA_REL_ "GenSigTimeoutTime" BU_SG_REL_ LED_LM_R SG_ 405 LED_R_Eco_Mode_2_Schaltart 500;
BA_REL_ "GenSigTimeoutTime" BU_SG_REL_ LLP_R SG_ 405 LED_R_Eco_Mode_2_Schaltart 500;
BA_REL_ "GenSigTimeoutTime" BU_SG_REL_ LED_DK3_LM_L SG_ 405 LED_L_Rennl_Anf 500;
BA_REL_ "GenSigTimeoutTime" BU_SG_REL_ LED_LM_L SG_ 405 LED_L_Rennl_Anf 500;
BA_REL_ "GenSigTimeoutTime" BU_SG_REL_ LLP_L SG_ 405 LED_L_Rennl_Anf 500;
BA_REL_ "GenSigTimeoutTime" BU_SG_REL_ LED_DK3_LM_L SG_ 405 LED_L_Rennl_Schaltart 500;
BA_REL_ "GenSigTimeoutTime" BU_SG_REL_ LED_LM_L SG_ 405 LED_L_Rennl_Schaltart 500;
BA_REL_ "GenSigTimeoutTime" BU_SG_REL_ LLP_L SG_ 405 LED_L_Rennl_Schaltart 500;
BA_REL_ "GenSigTimeoutTime" BU_SG_REL_ LED_DK3_LM_R SG_ 405 LED_R_Rennl_Anf 500;
BA_REL_ "GenSigTimeoutTime" BU_SG_REL_ LED_LM_R SG_ 405 LED_R_Rennl_Anf 500;
BA_REL_ "GenSigTimeoutTime" BU_SG_REL_ LLP_R SG_ 405 LED_R_Rennl_Anf 500;
BA_REL_ "GenSigTimeoutTime" BU_SG_REL_ LED_DK3_LM_R SG_ 405 LED_R_Rennl_Schaltart 500;
BA_REL_ "GenSigTimeoutTime" BU_SG_REL_ LED_LM_R SG_ 405 LED_R_Rennl_Schaltart 500;
BA_REL_ "GenSigTimeoutTime" BU_SG_REL_ LLP_R SG_ 405 LED_R_Rennl_Schaltart 500;
BA_REL_ "GenSigTimeoutTime" BU_SG_REL_ LED_DK3_LM_L SG_ 405 LED_L_Stadtl_Anf 500;
BA_REL_ "GenSigTimeoutTime" BU_SG_REL_ LED_LM_L SG_ 405 LED_L_Stadtl_Anf 500;
BA_REL_ "GenSigTimeoutTime" BU_SG_REL_ LLP_L SG_ 405 LED_L_Stadtl_Anf 500;
BA_REL_ "GenSigTimeoutTime" BU_SG_REL_ LED_DK3_LM_L SG_ 405 LED_L_Stadtl_Schaltart 500;
BA_REL_ "GenSigTimeoutTime" BU_SG_REL_ LED_LM_L SG_ 405 LED_L_Stadtl_Schaltart 500;
BA_REL_ "GenSigTimeoutTime" BU_SG_REL_ LLP_L SG_ 405 LED_L_Stadtl_Schaltart 500;
BA_REL_ "GenSigTimeoutTime" BU_SG_REL_ LED_DK3_LM_R SG_ 405 LED_R_Stadtl_Anf 500;
BA_REL_ "GenSigTimeoutTime" BU_SG_REL_ LED_LM_R SG_ 405 LED_R_Stadtl_Anf 500;
BA_REL_ "GenSigTimeoutTime" BU_SG_REL_ LLP_R SG_ 405 LED_R_Stadtl_Anf 500;
BA_REL_ "GenSigTimeoutTime" BU_SG_REL_ LED_DK3_LM_R SG_ 405 LED_R_Stadtl_Schaltart 500;
BA_REL_ "GenSigTimeoutTime" BU_SG_REL_ LED_LM_R SG_ 405 LED_R_Stadtl_Schaltart 500;
BA_REL_ "GenSigTimeoutTime" BU_SG_REL_ LLP_R SG_ 405 LED_R_Stadtl_Schaltart 500;
BA_REL_ "GenSigTimeoutTime" BU_SG_REL_ LED_DK3_LM_L SG_ 405 LED_L_TFL_Anf 500;
BA_REL_ "GenSigTimeoutTime" BU_SG_REL_ LED_LM_L SG_ 405 LED_L_TFL_Anf 500;
BA_REL_ "GenSigTimeoutTime" BU_SG_REL_ LLP_L SG_ 405 LED_L_TFL_Anf 500;
BA_REL_ "GenSigTimeoutTime" BU_SG_REL_ LED_DK3_LM_L SG_ 405 LED_L_TFL_Schaltart 500;
BA_REL_ "GenSigTimeoutTime" BU_SG_REL_ LED_LM_L SG_ 405 LED_L_TFL_Schaltart 500;
BA_REL_ "GenSigTimeoutTime" BU_SG_REL_ LLP_L SG_ 405 LED_L_TFL_Schaltart 500;
BA_REL_ "GenSigTimeoutTime" BU_SG_REL_ LED_DK3_LM_R SG_ 405 LED_R_TFL_Anf 500;
BA_REL_ "GenSigTimeoutTime" BU_SG_REL_ LED_LM_R SG_ 405 LED_R_TFL_Anf 500;
BA_REL_ "GenSigTimeoutTime" BU_SG_REL_ LLP_R SG_ 405 LED_R_TFL_Anf 500;
BA_REL_ "GenSigTimeoutTime" BU_SG_REL_ LED_DK3_LM_R SG_ 405 LED_R_TFL_Schaltart 500;
BA_REL_ "GenSigTimeoutTime" BU_SG_REL_ LED_LM_R SG_ 405 LED_R_TFL_Schaltart 500;
BA_REL_ "GenSigTimeoutTime" BU_SG_REL_ LLP_R SG_ 405 LED_R_TFL_Schaltart 500;
BA_REL_ "GenSigTimeoutTime" BU_SG_REL_ LED_DK3_LM_L SG_ 405 LED_L_Touristenl_Anf 500;
BA_REL_ "GenSigTimeoutTime" BU_SG_REL_ LED_LM_L SG_ 405 LED_L_Touristenl_Anf 500;
BA_REL_ "GenSigTimeoutTime" BU_SG_REL_ LLP_L SG_ 405 LED_L_Touristenl_Anf 500;
BA_REL_ "GenSigTimeoutTime" BU_SG_REL_ LED_DK3_LM_L SG_ 405 LED_L_Touristenl_Schaltart 500;
BA_REL_ "GenSigTimeoutTime" BU_SG_REL_ LED_LM_L SG_ 405 LED_L_Touristenl_Schaltart 500;
BA_REL_ "GenSigTimeoutTime" BU_SG_REL_ LLP_L SG_ 405 LED_L_Touristenl_Schaltart 500;
BA_REL_ "GenSigTimeoutTime" BU_SG_REL_ LED_DK3_LM_R SG_ 405 LED_R_Touristenl_Anf 500;
BA_REL_ "GenSigTimeoutTime" BU_SG_REL_ LED_LM_R SG_ 405 LED_R_Touristenl_Anf 500;
BA_REL_ "GenSigTimeoutTime" BU_SG_REL_ LLP_R SG_ 405 LED_R_Touristenl_Anf 500;
BA_REL_ "GenSigTimeoutTime" BU_SG_REL_ LED_DK3_LM_R SG_ 405 LED_R_Touristenl_Schaltart 500;
BA_REL_ "GenSigTimeoutTime" BU_SG_REL_ LED_LM_R SG_ 405 LED_R_Touristenl_Schaltart 500;
BA_REL_ "GenSigTimeoutTime" BU_SG_REL_ LLP_R SG_ 405 LED_R_Touristenl_Schaltart 500;
BA_REL_ "GenSigTimeoutTime" BU_SG_REL_ LED_DK3_LM_L SG_ 405 LED_ECE_SAE_Umschaltung_Anf 500;
BA_REL_ "GenSigTimeoutTime" BU_SG_REL_ LED_DK3_LM_R SG_ 405 LED_ECE_SAE_Umschaltung_Anf 500;
BA_REL_ "GenSigTimeoutTime" BU_SG_REL_ LED_LM_L SG_ 405 LED_ECE_SAE_Umschaltung_Anf 500;
BA_REL_ "GenSigTimeoutTime" BU_SG_REL_ LED_LM_R SG_ 405 LED_ECE_SAE_Umschaltung_Anf 500;
BA_REL_ "GenSigTimeoutTime" BU_SG_REL_ LLP_L SG_ 405 LED_ECE_SAE_Umschaltung_Anf 500;
BA_REL_ "GenSigTimeoutTime" BU_SG_REL_ LLP_R SG_ 405 LED_ECE_SAE_Umschaltung_Anf 500;
BA_REL_ "GenSigTimeoutTime" BU_SG_REL_ LED_DK3_LM_L SG_ 405 LED_Tag_Nacht_Umschaltung_Anf 500;
BA_REL_ "GenSigTimeoutTime" BU_SG_REL_ LED_DK3_LM_R SG_ 405 LED_Tag_Nacht_Umschaltung_Anf 500;
BA_REL_ "GenSigTimeoutTime" BU_SG_REL_ LED_LM_L SG_ 405 LED_Tag_Nacht_Umschaltung_Anf 500;
BA_REL_ "GenSigTimeoutTime" BU_SG_REL_ LED_LM_R SG_ 405 LED_Tag_Nacht_Umschaltung_Anf 500;
BA_REL_ "GenSigTimeoutTime" BU_SG_REL_ LLP_L SG_ 405 LED_Tag_Nacht_Umschaltung_Anf 500;
BA_REL_ "GenSigTimeoutTime" BU_SG_REL_ LLP_R SG_ 405 LED_Tag_Nacht_Umschaltung_Anf 500;
BA_REL_ "GenSigTimeoutTime" BU_SG_REL_ LED_LM_L SG_ 405 LED_Sta_Diag 500;
BA_REL_ "GenSigTimeoutTime" BU_SG_REL_ LED_LM_R SG_ 405 LED_Sta_Diag 500;
BA_REL_ "GenSigTimeoutTime" BU_SG_REL_ LED_DK3_LM_L SG_ 405 LED_L_Abbiegel_Dimmung 500;
BA_REL_ "GenSigTimeoutTime" BU_SG_REL_ LED_LM_L SG_ 405 LED_L_Abbiegel_Dimmung 500;
BA_REL_ "GenSigTimeoutTime" BU_SG_REL_ LLP_L SG_ 405 LED_L_Abbiegel_Dimmung 500;
BA_REL_ "GenSigTimeoutTime" BU_SG_REL_ LED_DK3_LM_R SG_ 405 LED_R_Abbiegel_Dimmung 500;
BA_REL_ "GenSigTimeoutTime" BU_SG_REL_ LED_LM_R SG_ 405 LED_R_Abbiegel_Dimmung 500;
BA_REL_ "GenSigTimeoutTime" BU_SG_REL_ LLP_R SG_ 405 LED_R_Abbiegel_Dimmung 500;
BA_REL_ "GenSigTimeoutTime" BU_SG_REL_ LED_DK3_LM_L SG_ 351 LED_Soll_Fkt2_CRC 500;
BA_REL_ "GenSigTimeoutTime" BU_SG_REL_ LED_DK3_LM_R SG_ 351 LED_Soll_Fkt2_CRC 500;
BA_REL_ "GenSigTimeoutTime" BU_SG_REL_ LLP_L SG_ 351 LED_Soll_Fkt2_CRC 500;
BA_REL_ "GenSigTimeoutTime" BU_SG_REL_ LLP_R SG_ 351 LED_Soll_Fkt2_CRC 500;
BA_REL_ "GenSigTimeoutTime" BU_SG_REL_ LED_DK3_LM_L SG_ 351 LED_Soll_Fkt2_BZ 500;
BA_REL_ "GenSigTimeoutTime" BU_SG_REL_ LED_DK3_LM_R SG_ 351 LED_Soll_Fkt2_BZ 500;
BA_REL_ "GenSigTimeoutTime" BU_SG_REL_ LLP_L SG_ 351 LED_Soll_Fkt2_BZ 500;
BA_REL_ "GenSigTimeoutTime" BU_SG_REL_ LLP_R SG_ 351 LED_Soll_Fkt2_BZ 500;
BA_REL_ "GenSigTimeoutTime" BU_SG_REL_ LED_DK3_LM_L SG_ 351 LED_L_Abblendl_Anf 500;
BA_REL_ "GenSigTimeoutTime" BU_SG_REL_ LLP_L SG_ 351 LED_L_Abblendl_Anf 500;
BA_REL_ "GenSigTimeoutTime" BU_SG_REL_ LED_DK3_LM_L SG_ 351 LED_L_Abblendl_Schaltart 500;
BA_REL_ "GenSigTimeoutTime" BU_SG_REL_ LLP_L SG_ 351 LED_L_Abblendl_Schaltart 500;
BA_REL_ "GenSigTimeoutTime" BU_SG_REL_ LED_DK3_LM_R SG_ 351 LED_R_Abblendl_Anf 500;
BA_REL_ "GenSigTimeoutTime" BU_SG_REL_ LLP_R SG_ 351 LED_R_Abblendl_Anf 500;
BA_REL_ "GenSigTimeoutTime" BU_SG_REL_ LED_DK3_LM_R SG_ 351 LED_R_Abblendl_Schaltart 500;
BA_REL_ "GenSigTimeoutTime" BU_SG_REL_ LLP_R SG_ 351 LED_R_Abblendl_Schaltart 500;
BA_REL_ "GenSigTimeoutTime" BU_SG_REL_ LED_DK3_LM_L SG_ 351 LED_L_Fernl_LH_Anf 500;
BA_REL_ "GenSigTimeoutTime" BU_SG_REL_ LLP_L SG_ 351 LED_L_Fernl_LH_Anf 500;
BA_REL_ "GenSigTimeoutTime" BU_SG_REL_ LED_DK3_LM_L SG_ 351 LED_L_Fernl_LH_Schaltart 500;
BA_REL_ "GenSigTimeoutTime" BU_SG_REL_ LLP_L SG_ 351 LED_L_Fernl_LH_Schaltart 500;
BA_REL_ "GenSigTimeoutTime" BU_SG_REL_ LED_DK3_LM_R SG_ 351 LED_R_Fernl_LH_Anf 500;
BA_REL_ "GenSigTimeoutTime" BU_SG_REL_ LLP_R SG_ 351 LED_R_Fernl_LH_Anf 500;
BA_REL_ "GenSigTimeoutTime" BU_SG_REL_ LED_DK3_LM_R SG_ 351 LED_R_Fernl_LH_Schaltart 500;
BA_REL_ "GenSigTimeoutTime" BU_SG_REL_ LLP_R SG_ 351 LED_R_Fernl_LH_Schaltart 500;
BA_REL_ "GenSigTimeoutTime" BU_SG_REL_ LED_DK3_LM_L SG_ 351 LED_L_Nebel_All_Anf 500;
BA_REL_ "GenSigTimeoutTime" BU_SG_REL_ LLP_L SG_ 351 LED_L_Nebel_All_Anf 500;
BA_REL_ "GenSigTimeoutTime" BU_SG_REL_ LED_DK3_LM_L SG_ 351 LED_L_Nebel_All_Schaltart 500;
BA_REL_ "GenSigTimeoutTime" BU_SG_REL_ LLP_L SG_ 351 LED_L_Nebel_All_Schaltart 500;
BA_REL_ "GenSigTimeoutTime" BU_SG_REL_ LED_DK3_LM_R SG_ 351 LED_R_Nebel_All_Anf 500;
BA_REL_ "GenSigTimeoutTime" BU_SG_REL_ LLP_R SG_ 351 LED_R_Nebel_All_Anf 500;
BA_REL_ "GenSigTimeoutTime" BU_SG_REL_ LED_DK3_LM_R SG_ 351 LED_R_Nebel_All_Schaltart 500;
BA_REL_ "GenSigTimeoutTime" BU_SG_REL_ LLP_R SG_ 351 LED_R_Nebel_All_Schaltart 500;
BA_REL_ "GenSigTimeoutTime" BU_SG_REL_ LED_DK3_LM_L SG_ 351 LED_Sta_Diag 500;
BA_REL_ "GenSigTimeoutTime" BU_SG_REL_ LED_DK3_LM_R SG_ 351 LED_Sta_Diag 500;
BA_REL_ "GenSigTimeoutTime" BU_SG_REL_ LLP_L SG_ 351 LED_Sta_Diag 500;
BA_REL_ "GenSigTimeoutTime" BU_SG_REL_ LLP_R SG_ 351 LED_Sta_Diag 500;
BA_REL_ "GenSigTimeoutTime" BU_SG_REL_ LED_DK3_LM_L SG_ 351 LED_L_Zus_Fernl_LH_Anf 500;
BA_REL_ "GenSigTimeoutTime" BU_SG_REL_ LLP_L SG_ 351 LED_L_Zus_Fernl_LH_Anf 500;
BA_REL_ "GenSigTimeoutTime" BU_SG_REL_ LED_DK3_LM_L SG_ 351 LED_L_Zus_Fernl_LH_Schaltart 500;
BA_REL_ "GenSigTimeoutTime" BU_SG_REL_ LLP_L SG_ 351 LED_L_Zus_Fernl_LH_Schaltart 500;
BA_REL_ "GenSigTimeoutTime" BU_SG_REL_ LED_DK3_LM_R SG_ 351 LED_R_Zus_Fernl_LH_Anf 500;
BA_REL_ "GenSigTimeoutTime" BU_SG_REL_ LLP_R SG_ 351 LED_R_Zus_Fernl_LH_Anf 500;
BA_REL_ "GenSigTimeoutTime" BU_SG_REL_ LED_DK3_LM_R SG_ 351 LED_R_Zus_Fernl_LH_Schaltart 500;
BA_REL_ "GenSigTimeoutTime" BU_SG_REL_ LLP_R SG_ 351 LED_R_Zus_Fernl_LH_Schaltart 500;
BA_REL_ "GenSigTimeoutTime" BU_SG_REL_ LED_DK3_LM_L SG_ 351 BCM1_CH_aktiv 500;
BA_REL_ "GenSigTimeoutTime" BU_SG_REL_ LED_DK3_LM_R SG_ 351 BCM1_CH_aktiv 500;
BA_REL_ "GenSigTimeoutTime" BU_SG_REL_ LLP_L SG_ 351 BCM1_CH_aktiv 500;
BA_REL_ "GenSigTimeoutTime" BU_SG_REL_ LLP_R SG_ 351 BCM1_CH_aktiv 500;
BA_REL_ "GenSigTimeoutTime" BU_SG_REL_ LED_DK3_LM_L SG_ 351 BCM1_LH_aktiv 500;
BA_REL_ "GenSigTimeoutTime" BU_SG_REL_ LED_DK3_LM_R SG_ 351 BCM1_LH_aktiv 500;
BA_REL_ "GenSigTimeoutTime" BU_SG_REL_ LLP_L SG_ 351 BCM1_LH_aktiv 500;
BA_REL_ "GenSigTimeoutTime" BU_SG_REL_ LLP_R SG_ 351 BCM1_LH_aktiv 500;
BA_REL_ "GenSigTimeoutTime" BU_SG_REL_ AFS SG_ 920 FLL_SchMot 1000;
BA_REL_ "GenSigTimeoutTime" BU_SG_REL_ BCM1 SG_ 920 FLL_SchMot 1000;
BA_REL_ "GenSigTimeoutTime" BU_SG_REL_ FCM SG_ 920 FLL_SchMot 1000;
BA_REL_ "GenSigTimeoutTime" BU_SG_REL_ MXB SG_ 920 FLL_SchMot 1000;
BA_REL_ "GenSigTimeoutTime" BU_SG_REL_ AFS SG_ 920 FLL_RSchMot 1000;
BA_REL_ "GenSigTimeoutTime" BU_SG_REL_ BCM1 SG_ 920 FLL_RSchMot 1000;
BA_REL_ "GenSigTimeoutTime" BU_SG_REL_ FCM SG_ 920 FLL_RSchMot 1000;
BA_REL_ "GenSigTimeoutTime" BU_SG_REL_ MXB SG_ 920 FLL_RSchMot 1000;
BA_REL_ "GenSigTimeoutTime" BU_SG_REL_ AFS SG_ 920 FLL_SM_KS_Gnd 1000;
BA_REL_ "GenSigTimeoutTime" BU_SG_REL_ BCM1 SG_ 920 FLL_SM_KS_Gnd 1000;
BA_REL_ "GenSigTimeoutTime" BU_SG_REL_ FCM SG_ 920 FLL_SM_KS_Gnd 1000;
BA_REL_ "GenSigTimeoutTime" BU_SG_REL_ MXB SG_ 920 FLL_SM_KS_Gnd 1000;
BA_REL_ "GenSigTimeoutTime" BU_SG_REL_ AFS SG_ 920 FLL_RSM_KS_Gnd 1000;
BA_REL_ "GenSigTimeoutTime" BU_SG_REL_ BCM1 SG_ 920 FLL_RSM_KS_Gnd 1000;
BA_REL_ "GenSigTimeoutTime" BU_SG_REL_ FCM SG_ 920 FLL_RSM_KS_Gnd 1000;
BA_REL_ "GenSigTimeoutTime" BU_SG_REL_ MXB SG_ 920 FLL_RSM_KS_Gnd 1000;
BA_REL_ "GenSigTimeoutTime" BU_SG_REL_ AFS SG_ 920 FLL_SM_UeSpg 1000;
BA_REL_ "GenSigTimeoutTime" BU_SG_REL_ BCM1 SG_ 920 FLL_SM_UeSpg 1000;
BA_REL_ "GenSigTimeoutTime" BU_SG_REL_ FCM SG_ 920 FLL_SM_UeSpg 1000;
BA_REL_ "GenSigTimeoutTime" BU_SG_REL_ MXB SG_ 920 FLL_SM_UeSpg 1000;
BA_REL_ "GenSigTimeoutTime" BU_SG_REL_ AFS SG_ 920 FLL_RSM_UeSpg 1000;
BA_REL_ "GenSigTimeoutTime" BU_SG_REL_ BCM1 SG_ 920 FLL_RSM_UeSpg 1000;
BA_REL_ "GenSigTimeoutTime" BU_SG_REL_ FCM SG_ 920 FLL_RSM_UeSpg 1000;
BA_REL_ "GenSigTimeoutTime" BU_SG_REL_ MXB SG_ 920 FLL_RSM_UeSpg 1000;
BA_REL_ "GenSigTimeoutTime" BU_SG_REL_ AFS SG_ 920 FLL_SM_USpg 1000;
BA_REL_ "GenSigTimeoutTime" BU_SG_REL_ BCM1 SG_ 920 FLL_SM_USpg 1000;
BA_REL_ "GenSigTimeoutTime" BU_SG_REL_ FCM SG_ 920 FLL_SM_USpg 1000;
BA_REL_ "GenSigTimeoutTime" BU_SG_REL_ MXB SG_ 920 FLL_SM_USpg 1000;
BA_REL_ "GenSigTimeoutTime" BU_SG_REL_ AFS SG_ 920 FLL_RSM_USpg 1000;
BA_REL_ "GenSigTimeoutTime" BU_SG_REL_ BCM1 SG_ 920 FLL_RSM_USpg 1000;
BA_REL_ "GenSigTimeoutTime" BU_SG_REL_ FCM SG_ 920 FLL_RSM_USpg 1000;
BA_REL_ "GenSigTimeoutTime" BU_SG_REL_ MXB SG_ 920 FLL_RSM_USpg 1000;
BA_REL_ "GenSigTimeoutTime" BU_SG_REL_ AFS SG_ 920 FLL_SM_UeTemp 1000;
BA_REL_ "GenSigTimeoutTime" BU_SG_REL_ BCM1 SG_ 920 FLL_SM_UeTemp 1000;
BA_REL_ "GenSigTimeoutTime" BU_SG_REL_ FCM SG_ 920 FLL_SM_UeTemp 1000;
BA_REL_ "GenSigTimeoutTime" BU_SG_REL_ MXB SG_ 920 FLL_SM_UeTemp 1000;
BA_REL_ "GenSigTimeoutTime" BU_SG_REL_ AFS SG_ 920 FLL_RSM_UeTemp 1000;
BA_REL_ "GenSigTimeoutTime" BU_SG_REL_ BCM1 SG_ 920 FLL_RSM_UeTemp 1000;
BA_REL_ "GenSigTimeoutTime" BU_SG_REL_ FCM SG_ 920 FLL_RSM_UeTemp 1000;
BA_REL_ "GenSigTimeoutTime" BU_SG_REL_ MXB SG_ 920 FLL_RSM_UeTemp 1000;
BA_REL_ "GenSigTimeoutTime" BU_SG_REL_ AFS SG_ 920 FLL_SM_TempPre 1000;
BA_REL_ "GenSigTimeoutTime" BU_SG_REL_ BCM1 SG_ 920 FLL_SM_TempPre 1000;
BA_REL_ "GenSigTimeoutTime" BU_SG_REL_ FCM SG_ 920 FLL_SM_TempPre 1000;
BA_REL_ "GenSigTimeoutTime" BU_SG_REL_ MXB SG_ 920 FLL_SM_TempPre 1000;
BA_REL_ "GenSigTimeoutTime" BU_SG_REL_ AFS SG_ 920 FLL_RSM_TempPre 1000;
BA_REL_ "GenSigTimeoutTime" BU_SG_REL_ BCM1 SG_ 920 FLL_RSM_TempPre 1000;
BA_REL_ "GenSigTimeoutTime" BU_SG_REL_ FCM SG_ 920 FLL_RSM_TempPre 1000;
BA_REL_ "GenSigTimeoutTime" BU_SG_REL_ MXB SG_ 920 FLL_RSM_TempPre 1000;
BA_REL_ "GenSigTimeoutTime" BU_SG_REL_ AFS SG_ 920 FLL_AFS_Unpl 1000;
BA_REL_ "GenSigTimeoutTime" BU_SG_REL_ BCM1 SG_ 920 FLL_AFS_Unpl 1000;
BA_REL_ "GenSigTimeoutTime" BU_SG_REL_ FCM SG_ 920 FLL_AFS_Unpl 1000;
BA_REL_ "GenSigTimeoutTime" BU_SG_REL_ MXB SG_ 920 FLL_AFS_Unpl 1000;
BA_REL_ "GenSigTimeoutTime" BU_SG_REL_ AFS SG_ 920 FLL_RAFS_Unpl 1000;
BA_REL_ "GenSigTimeoutTime" BU_SG_REL_ BCM1 SG_ 920 FLL_RAFS_Unpl 1000;
BA_REL_ "GenSigTimeoutTime" BU_SG_REL_ FCM SG_ 920 FLL_RAFS_Unpl 1000;
BA_REL_ "GenSigTimeoutTime" BU_SG_REL_ MXB SG_ 920 FLL_RAFS_Unpl 1000;
BA_REL_ "GenSigTimeoutTime" BU_SG_REL_ AFS SG_ 922 FLR_SchMot 1000;
BA_REL_ "GenSigTimeoutTime" BU_SG_REL_ BCM1 SG_ 922 FLR_SchMot 1000;
BA_REL_ "GenSigTimeoutTime" BU_SG_REL_ FCM SG_ 922 FLR_SchMot 1000;
BA_REL_ "GenSigTimeoutTime" BU_SG_REL_ MXB SG_ 922 FLR_SchMot 1000;
BA_REL_ "GenSigTimeoutTime" BU_SG_REL_ AFS SG_ 922 FLR_RSchMot 1000;
BA_REL_ "GenSigTimeoutTime" BU_SG_REL_ BCM1 SG_ 922 FLR_RSchMot 1000;
BA_REL_ "GenSigTimeoutTime" BU_SG_REL_ FCM SG_ 922 FLR_RSchMot 1000;
BA_REL_ "GenSigTimeoutTime" BU_SG_REL_ MXB SG_ 922 FLR_RSchMot 1000;
BA_REL_ "GenSigTimeoutTime" BU_SG_REL_ AFS SG_ 922 FLR_SM_KS_Gnd 1000;
BA_REL_ "GenSigTimeoutTime" BU_SG_REL_ BCM1 SG_ 922 FLR_SM_KS_Gnd 1000;
BA_REL_ "GenSigTimeoutTime" BU_SG_REL_ FCM SG_ 922 FLR_SM_KS_Gnd 1000;
BA_REL_ "GenSigTimeoutTime" BU_SG_REL_ MXB SG_ 922 FLR_SM_KS_Gnd 1000;
BA_REL_ "GenSigTimeoutTime" BU_SG_REL_ AFS SG_ 922 FLR_RSM_KS_Gnd 1000;
BA_REL_ "GenSigTimeoutTime" BU_SG_REL_ BCM1 SG_ 922 FLR_RSM_KS_Gnd 1000;
BA_REL_ "GenSigTimeoutTime" BU_SG_REL_ FCM SG_ 922 FLR_RSM_KS_Gnd 1000;
BA_REL_ "GenSigTimeoutTime" BU_SG_REL_ MXB SG_ 922 FLR_RSM_KS_Gnd 1000;
BA_REL_ "GenSigTimeoutTime" BU_SG_REL_ AFS SG_ 922 FLR_SM_UeSpg 1000;
BA_REL_ "GenSigTimeoutTime" BU_SG_REL_ BCM1 SG_ 922 FLR_SM_UeSpg 1000;
BA_REL_ "GenSigTimeoutTime" BU_SG_REL_ FCM SG_ 922 FLR_SM_UeSpg 1000;
BA_REL_ "GenSigTimeoutTime" BU_SG_REL_ MXB SG_ 922 FLR_SM_UeSpg 1000;
BA_REL_ "GenSigTimeoutTime" BU_SG_REL_ AFS SG_ 922 FLR_RSM_UeSpg 1000;
BA_REL_ "GenSigTimeoutTime" BU_SG_REL_ BCM1 SG_ 922 FLR_RSM_UeSpg 1000;
BA_REL_ "GenSigTimeoutTime" BU_SG_REL_ FCM SG_ 922 FLR_RSM_UeSpg 1000;
BA_REL_ "GenSigTimeoutTime" BU_SG_REL_ MXB SG_ 922 FLR_RSM_UeSpg 1000;
BA_REL_ "GenSigTimeoutTime" BU_SG_REL_ AFS SG_ 922 FLR_SM_USpg 1000;
BA_REL_ "GenSigTimeoutTime" BU_SG_REL_ BCM1 SG_ 922 FLR_SM_USpg 1000;
BA_REL_ "GenSigTimeoutTime" BU_SG_REL_ FCM SG_ 922 FLR_SM_USpg 1000;
BA_REL_ "GenSigTimeoutTime" BU_SG_REL_ MXB SG_ 922 FLR_SM_USpg 1000;
BA_REL_ "GenSigTimeoutTime" BU_SG_REL_ AFS SG_ 922 FLR_RSM_USpg 1000;
BA_REL_ "GenSigTimeoutTime" BU_SG_REL_ BCM1 SG_ 922 FLR_RSM_USpg 1000;
BA_REL_ "GenSigTimeoutTime" BU_SG_REL_ FCM SG_ 922 FLR_RSM_USpg 1000;
BA_REL_ "GenSigTimeoutTime" BU_SG_REL_ MXB SG_ 922 FLR_RSM_USpg 1000;
BA_REL_ "GenSigTimeoutTime" BU_SG_REL_ AFS SG_ 922 FLR_SM_UeTemp 1000;
BA_REL_ "GenSigTimeoutTime" BU_SG_REL_ BCM1 SG_ 922 FLR_SM_UeTemp 1000;
BA_REL_ "GenSigTimeoutTime" BU_SG_REL_ FCM SG_ 922 FLR_SM_UeTemp 1000;
BA_REL_ "GenSigTimeoutTime" BU_SG_REL_ MXB SG_ 922 FLR_SM_UeTemp 1000;
BA_REL_ "GenSigTimeoutTime" BU_SG_REL_ AFS SG_ 922 FLR_RSM_UeTemp 1000;
BA_REL_ "GenSigTimeoutTime" BU_SG_REL_ BCM1 SG_ 922 FLR_RSM_UeTemp 1000;
BA_REL_ "GenSigTimeoutTime" BU_SG_REL_ FCM SG_ 922 FLR_RSM_UeTemp 1000;
BA_REL_ "GenSigTimeoutTime" BU_SG_REL_ MXB SG_ 922 FLR_RSM_UeTemp 1000;
BA_REL_ "GenSigTimeoutTime" BU_SG_REL_ AFS SG_ 922 FLR_SM_TempPre 1000;
BA_REL_ "GenSigTimeoutTime" BU_SG_REL_ BCM1 SG_ 922 FLR_SM_TempPre 1000;
BA_REL_ "GenSigTimeoutTime" BU_SG_REL_ FCM SG_ 922 FLR_SM_TempPre 1000;
BA_REL_ "GenSigTimeoutTime" BU_SG_REL_ MXB SG_ 922 FLR_SM_TempPre 1000;
BA_REL_ "GenSigTimeoutTime" BU_SG_REL_ AFS SG_ 922 FLR_RSM_TempPre 1000;
BA_REL_ "GenSigTimeoutTime" BU_SG_REL_ BCM1 SG_ 922 FLR_RSM_TempPre 1000;
BA_REL_ "GenSigTimeoutTime" BU_SG_REL_ FCM SG_ 922 FLR_RSM_TempPre 1000;
BA_REL_ "GenSigTimeoutTime" BU_SG_REL_ MXB SG_ 922 FLR_RSM_TempPre 1000;
BA_REL_ "GenSigTimeoutTime" BU_SG_REL_ AFS SG_ 922 FLR_AFS_Unpl 1000;
BA_REL_ "GenSigTimeoutTime" BU_SG_REL_ BCM1 SG_ 922 FLR_AFS_Unpl 1000;
BA_REL_ "GenSigTimeoutTime" BU_SG_REL_ FCM SG_ 922 FLR_AFS_Unpl 1000;
BA_REL_ "GenSigTimeoutTime" BU_SG_REL_ MXB SG_ 922 FLR_AFS_Unpl 1000;
BA_REL_ "GenSigTimeoutTime" BU_SG_REL_ AFS SG_ 922 FLR_RAFS_Unpl 1000;
BA_REL_ "GenSigTimeoutTime" BU_SG_REL_ BCM1 SG_ 922 FLR_RAFS_Unpl 1000;
BA_REL_ "GenSigTimeoutTime" BU_SG_REL_ FCM SG_ 922 FLR_RAFS_Unpl 1000;
BA_REL_ "GenSigTimeoutTime" BU_SG_REL_ MXB SG_ 922 FLR_RAFS_Unpl 1000;
BA_REL_ "GenSigTimeoutTime" BU_SG_REL_ AFS_LMod_L SG_ 400 SOL_SollPos_L 500;
BA_REL_ "GenSigTimeoutTime" BU_SG_REL_ GLW_LMod_L SG_ 400 SOL_SollPos_L 500;
BA_REL_ "GenSigTimeoutTime" BU_SG_REL_ LCM_L SG_ 400 SOL_SollPos_L 500;
BA_REL_ "GenSigTimeoutTime" BU_SG_REL_ LLP_L SG_ 400 SOL_SollPos_L 500;
BA_REL_ "GenSigTimeoutTime" BU_SG_REL_ LWR_MXB_L SG_ 400 SOL_SollPos_L 500;
BA_REL_ "GenSigTimeoutTime" BU_SG_REL_ AFS_LMod_L SG_ 400 SOL_FehlPos_L 500;
BA_REL_ "GenSigTimeoutTime" BU_SG_REL_ GLW_LMod_L SG_ 400 SOL_FehlPos_L 500;
BA_REL_ "GenSigTimeoutTime" BU_SG_REL_ LCM_L SG_ 400 SOL_FehlPos_L 500;
BA_REL_ "GenSigTimeoutTime" BU_SG_REL_ LLP_L SG_ 400 SOL_FehlPos_L 500;
BA_REL_ "GenSigTimeoutTime" BU_SG_REL_ LWR_MXB_L SG_ 400 SOL_FehlPos_L 500;
BA_REL_ "GenSigTimeoutTime" BU_SG_REL_ AFS_LMod_L SG_ 400 SOL_RefLauf_L 500;
BA_REL_ "GenSigTimeoutTime" BU_SG_REL_ GLW_LMod_L SG_ 400 SOL_RefLauf_L 500;
BA_REL_ "GenSigTimeoutTime" BU_SG_REL_ LCM_L SG_ 400 SOL_RefLauf_L 500;
BA_REL_ "GenSigTimeoutTime" BU_SG_REL_ LLP_L SG_ 400 SOL_RefLauf_L 500;
BA_REL_ "GenSigTimeoutTime" BU_SG_REL_ LWR_MXB_L SG_ 400 SOL_RefLauf_L 500;
BA_REL_ "GenSigTimeoutTime" BU_SG_REL_ AFS_LMod_L SG_ 400 SOL_StGlTest_L 500;
BA_REL_ "GenSigTimeoutTime" BU_SG_REL_ GLW_LMod_L SG_ 400 SOL_StGlTest_L 500;
BA_REL_ "GenSigTimeoutTime" BU_SG_REL_ LCM_L SG_ 400 SOL_StGlTest_L 500;
BA_REL_ "GenSigTimeoutTime" BU_SG_REL_ LLP_L SG_ 400 SOL_StGlTest_L 500;
BA_REL_ "GenSigTimeoutTime" BU_SG_REL_ LWR_MXB_L SG_ 400 SOL_StGlTest_L 500;
BA_REL_ "GenSigTimeoutTime" BU_SG_REL_ AFS_LMod_L SG_ 400 SOL_Fehlloesch_L 500;
BA_REL_ "GenSigTimeoutTime" BU_SG_REL_ GLW_LMod_L SG_ 400 SOL_Fehlloesch_L 500;
BA_REL_ "GenSigTimeoutTime" BU_SG_REL_ LWR_MXB_L SG_ 400 SOL_Fehlloesch_L 500;
BA_REL_ "GenSigTimeoutTime" BU_SG_REL_ AFS_LMod_L SG_ 400 MO_StartStopp_Motorstopp 500;
BA_REL_ "GenSigTimeoutTime" BU_SG_REL_ AFS_LMod_R SG_ 400 MO_StartStopp_Motorstopp 500;
BA_REL_ "GenSigTimeoutTime" BU_SG_REL_ GLW_LMod_L SG_ 400 MO_StartStopp_Motorstopp 500;
BA_REL_ "GenSigTimeoutTime" BU_SG_REL_ GLW_LMod_R SG_ 400 MO_StartStopp_Motorstopp 500;
BA_REL_ "GenSigTimeoutTime" BU_SG_REL_ LED_DK3_LM_L SG_ 400 MO_StartStopp_Motorstopp 500;
BA_REL_ "GenSigTimeoutTime" BU_SG_REL_ LED_DK3_LM_R SG_ 400 MO_StartStopp_Motorstopp 500;
BA_REL_ "GenSigTimeoutTime" BU_SG_REL_ LED_LM_L SG_ 400 MO_StartStopp_Motorstopp 500;
BA_REL_ "GenSigTimeoutTime" BU_SG_REL_ LED_LM_R SG_ 400 MO_StartStopp_Motorstopp 500;
BA_REL_ "GenSigTimeoutTime" BU_SG_REL_ LLP_L SG_ 400 MO_StartStopp_Motorstopp 500;
BA_REL_ "GenSigTimeoutTime" BU_SG_REL_ LLP_R SG_ 400 MO_StartStopp_Motorstopp 500;
BA_REL_ "GenSigTimeoutTime" BU_SG_REL_ LWR_MXB_L SG_ 400 MO_StartStopp_Motorstopp 500;
BA_REL_ "GenSigTimeoutTime" BU_SG_REL_ LWR_MXB_R SG_ 400 MO_StartStopp_Motorstopp 500;
BA_REL_ "GenSigTimeoutTime" BU_SG_REL_ MXB_LM_L SG_ 400 MO_StartStopp_Motorstopp 500;
BA_REL_ "GenSigTimeoutTime" BU_SG_REL_ MXB_LM_R SG_ 400 MO_StartStopp_Motorstopp 500;
BA_REL_ "GenSigTimeoutTime" BU_SG_REL_ AFS_LMod_L SG_ 400 MO_StartStopp_Wiederstart 500;
BA_REL_ "GenSigTimeoutTime" BU_SG_REL_ AFS_LMod_R SG_ 400 MO_StartStopp_Wiederstart 500;
BA_REL_ "GenSigTimeoutTime" BU_SG_REL_ GLW_LMod_L SG_ 400 MO_StartStopp_Wiederstart 500;
BA_REL_ "GenSigTimeoutTime" BU_SG_REL_ GLW_LMod_R SG_ 400 MO_StartStopp_Wiederstart 500;
BA_REL_ "GenSigTimeoutTime" BU_SG_REL_ LED_DK3_LM_L SG_ 400 MO_StartStopp_Wiederstart 500;
BA_REL_ "GenSigTimeoutTime" BU_SG_REL_ LED_DK3_LM_R SG_ 400 MO_StartStopp_Wiederstart 500;
BA_REL_ "GenSigTimeoutTime" BU_SG_REL_ LED_LM_L SG_ 400 MO_StartStopp_Wiederstart 500;
BA_REL_ "GenSigTimeoutTime" BU_SG_REL_ LED_LM_R SG_ 400 MO_StartStopp_Wiederstart 500;
BA_REL_ "GenSigTimeoutTime" BU_SG_REL_ LLP_L SG_ 400 MO_StartStopp_Wiederstart 500;
BA_REL_ "GenSigTimeoutTime" BU_SG_REL_ LLP_R SG_ 400 MO_StartStopp_Wiederstart 500;
BA_REL_ "GenSigTimeoutTime" BU_SG_REL_ LWR_MXB_L SG_ 400 MO_StartStopp_Wiederstart 500;
BA_REL_ "GenSigTimeoutTime" BU_SG_REL_ LWR_MXB_R SG_ 400 MO_StartStopp_Wiederstart 500;
BA_REL_ "GenSigTimeoutTime" BU_SG_REL_ MXB_LM_L SG_ 400 MO_StartStopp_Wiederstart 500;
BA_REL_ "GenSigTimeoutTime" BU_SG_REL_ MXB_LM_R SG_ 400 MO_StartStopp_Wiederstart 500;
BA_REL_ "GenSigTimeoutTime" BU_SG_REL_ AFS_LMod_L SG_ 400 SOL_Tieftemp_Flag 500;
BA_REL_ "GenSigTimeoutTime" BU_SG_REL_ AFS_LMod_R SG_ 400 SOL_Tieftemp_Flag 500;
BA_REL_ "GenSigTimeoutTime" BU_SG_REL_ GLW_LMod_L SG_ 400 SOL_Tieftemp_Flag 500;
BA_REL_ "GenSigTimeoutTime" BU_SG_REL_ GLW_LMod_R SG_ 400 SOL_Tieftemp_Flag 500;
BA_REL_ "GenSigTimeoutTime" BU_SG_REL_ LCM_L SG_ 400 SOL_Tieftemp_Flag 500;
BA_REL_ "GenSigTimeoutTime" BU_SG_REL_ LCM_R SG_ 400 SOL_Tieftemp_Flag 500;
BA_REL_ "GenSigTimeoutTime" BU_SG_REL_ LLP_L SG_ 400 SOL_Tieftemp_Flag 500;
BA_REL_ "GenSigTimeoutTime" BU_SG_REL_ LLP_R SG_ 400 SOL_Tieftemp_Flag 500;
BA_REL_ "GenSigTimeoutTime" BU_SG_REL_ LWR_MXB_L SG_ 400 SOL_Tieftemp_Flag 500;
BA_REL_ "GenSigTimeoutTime" BU_SG_REL_ LWR_MXB_R SG_ 400 SOL_Tieftemp_Flag 500;
BA_REL_ "GenSigTimeoutTime" BU_SG_REL_ AFS_LMod_R SG_ 400 SOL_SollPos_R 500;
BA_REL_ "GenSigTimeoutTime" BU_SG_REL_ GLW_LMod_R SG_ 400 SOL_SollPos_R 500;
BA_REL_ "GenSigTimeoutTime" BU_SG_REL_ LCM_R SG_ 400 SOL_SollPos_R 500;
BA_REL_ "GenSigTimeoutTime" BU_SG_REL_ LLP_R SG_ 400 SOL_SollPos_R 500;
BA_REL_ "GenSigTimeoutTime" BU_SG_REL_ LWR_MXB_R SG_ 400 SOL_SollPos_R 500;
BA_REL_ "GenSigTimeoutTime" BU_SG_REL_ AFS_LMod_R SG_ 400 SOL_FehlPos_R 500;
BA_REL_ "GenSigTimeoutTime" BU_SG_REL_ GLW_LMod_R SG_ 400 SOL_FehlPos_R 500;
BA_REL_ "GenSigTimeoutTime" BU_SG_REL_ LCM_R SG_ 400 SOL_FehlPos_R 500;
BA_REL_ "GenSigTimeoutTime" BU_SG_REL_ LLP_R SG_ 400 SOL_FehlPos_R 500;
BA_REL_ "GenSigTimeoutTime" BU_SG_REL_ LWR_MXB_R SG_ 400 SOL_FehlPos_R 500;
BA_REL_ "GenSigTimeoutTime" BU_SG_REL_ AFS_LMod_R SG_ 400 SOL_RefLauf_R 500;
BA_REL_ "GenSigTimeoutTime" BU_SG_REL_ GLW_LMod_R SG_ 400 SOL_RefLauf_R 500;
BA_REL_ "GenSigTimeoutTime" BU_SG_REL_ LCM_R SG_ 400 SOL_RefLauf_R 500;
BA_REL_ "GenSigTimeoutTime" BU_SG_REL_ LLP_R SG_ 400 SOL_RefLauf_R 500;
BA_REL_ "GenSigTimeoutTime" BU_SG_REL_ LWR_MXB_R SG_ 400 SOL_RefLauf_R 500;
BA_REL_ "GenSigTimeoutTime" BU_SG_REL_ AFS_LMod_R SG_ 400 SOL_StGlTest_R 500;
BA_REL_ "GenSigTimeoutTime" BU_SG_REL_ GLW_LMod_R SG_ 400 SOL_StGlTest_R 500;
BA_REL_ "GenSigTimeoutTime" BU_SG_REL_ LCM_R SG_ 400 SOL_StGlTest_R 500;
BA_REL_ "GenSigTimeoutTime" BU_SG_REL_ LLP_R SG_ 400 SOL_StGlTest_R 500;
BA_REL_ "GenSigTimeoutTime" BU_SG_REL_ LWR_MXB_R SG_ 400 SOL_StGlTest_R 500;
BA_REL_ "GenSigTimeoutTime" BU_SG_REL_ AFS_LMod_R SG_ 400 SOL_Fehlloesch_R 500;
BA_REL_ "GenSigTimeoutTime" BU_SG_REL_ GLW_LMod_R SG_ 400 SOL_Fehlloesch_R 500;
BA_REL_ "GenSigTimeoutTime" BU_SG_REL_ LWR_MXB_R SG_ 400 SOL_Fehlloesch_R 500;
BA_REL_ "GenSigTimeoutTime" BU_SG_REL_ AFS_LMod_L SG_ 400 SOL_Sta_Diag 500;
BA_REL_ "GenSigTimeoutTime" BU_SG_REL_ AFS_LMod_R SG_ 400 SOL_Sta_Diag 500;
BA_REL_ "GenSigTimeoutTime" BU_SG_REL_ GLW_LMod_L SG_ 400 SOL_Sta_Diag 500;
BA_REL_ "GenSigTimeoutTime" BU_SG_REL_ GLW_LMod_R SG_ 400 SOL_Sta_Diag 500;
BA_REL_ "GenSigTimeoutTime" BU_SG_REL_ LWR_MXB_L SG_ 400 SOL_Sta_Diag 500;
BA_REL_ "GenSigTimeoutTime" BU_SG_REL_ LWR_MXB_R SG_ 400 SOL_Sta_Diag 500;
BA_REL_ "GenSigTimeoutTime" BU_SG_REL_ MXB_LM_L SG_ 400 SOL_Sta_Diag 500;
BA_REL_ "GenSigTimeoutTime" BU_SG_REL_ MXB_LM_R SG_ 400 SOL_Sta_Diag 500;
BA_REL_ "GenSigTimeoutTime" BU_SG_REL_ AFS SG_ 406 SLL_IstPos 500;
BA_REL_ "GenSigTimeoutTime" BU_SG_REL_ BCM1 SG_ 406 SLL_IstPos 500;
BA_REL_ "GenSigTimeoutTime" BU_SG_REL_ FCM SG_ 406 SLL_IstPos 500;
BA_REL_ "GenSigTimeoutTime" BU_SG_REL_ MXB SG_ 406 SLL_IstPos 500;
BA_REL_ "GenSigTimeoutTime" BU_SG_REL_ AFS SG_ 406 SLL_StaStStWiederstart 500;
BA_REL_ "GenSigTimeoutTime" BU_SG_REL_ BCM1 SG_ 406 SLL_StaStStWiederstart 500;
BA_REL_ "GenSigTimeoutTime" BU_SG_REL_ FCM SG_ 406 SLL_StaStStWiederstart 500;
BA_REL_ "GenSigTimeoutTime" BU_SG_REL_ LED_LM_L SG_ 406 SLL_StaStStWiederstart 500;
BA_REL_ "GenSigTimeoutTime" BU_SG_REL_ MXB SG_ 406 SLL_StaStStWiederstart 500;
BA_REL_ "GenSigTimeoutTime" BU_SG_REL_ MXB_LM_L SG_ 406 SLL_StaStStWiederstart 500;
BA_REL_ "GenSigTimeoutTime" BU_SG_REL_ AFS SG_ 406 SLL_StaStStMotorstopp 500;
BA_REL_ "GenSigTimeoutTime" BU_SG_REL_ BCM1 SG_ 406 SLL_StaStStMotorstopp 500;
BA_REL_ "GenSigTimeoutTime" BU_SG_REL_ FCM SG_ 406 SLL_StaStStMotorstopp 500;
BA_REL_ "GenSigTimeoutTime" BU_SG_REL_ LED_LM_L SG_ 406 SLL_StaStStMotorstopp 500;
BA_REL_ "GenSigTimeoutTime" BU_SG_REL_ MXB SG_ 406 SLL_StaStStMotorstopp 500;
BA_REL_ "GenSigTimeoutTime" BU_SG_REL_ MXB_LM_L SG_ 406 SLL_StaStStMotorstopp 500;
BA_REL_ "GenSigTimeoutTime" BU_SG_REL_ AFS SG_ 406 SLL_IstPosMot 500;
BA_REL_ "GenSigTimeoutTime" BU_SG_REL_ BCM1 SG_ 406 SLL_IstPosMot 500;
BA_REL_ "GenSigTimeoutTime" BU_SG_REL_ FCM SG_ 406 SLL_IstPosMot 500;
BA_REL_ "GenSigTimeoutTime" BU_SG_REL_ MXB SG_ 406 SLL_IstPosMot 500;
BA_REL_ "GenSigTimeoutTime" BU_SG_REL_ AFS SG_ 406 SLL_StaVerst 500;
BA_REL_ "GenSigTimeoutTime" BU_SG_REL_ BCM1 SG_ 406 SLL_StaVerst 500;
BA_REL_ "GenSigTimeoutTime" BU_SG_REL_ FCM SG_ 406 SLL_StaVerst 500;
BA_REL_ "GenSigTimeoutTime" BU_SG_REL_ MXB SG_ 406 SLL_StaVerst 500;
BA_REL_ "GenSigTimeoutTime" BU_SG_REL_ AFS SG_ 406 SLL_StaFehPos 500;
BA_REL_ "GenSigTimeoutTime" BU_SG_REL_ BCM1 SG_ 406 SLL_StaFehPos 500;
BA_REL_ "GenSigTimeoutTime" BU_SG_REL_ FCM SG_ 406 SLL_StaFehPos 500;
BA_REL_ "GenSigTimeoutTime" BU_SG_REL_ MXB SG_ 406 SLL_StaFehPos 500;
BA_REL_ "GenSigTimeoutTime" BU_SG_REL_ AFS SG_ 406 SLL_StaReflauf 500;
BA_REL_ "GenSigTimeoutTime" BU_SG_REL_ BCM1 SG_ 406 SLL_StaReflauf 500;
BA_REL_ "GenSigTimeoutTime" BU_SG_REL_ FCM SG_ 406 SLL_StaReflauf 500;
BA_REL_ "GenSigTimeoutTime" BU_SG_REL_ MXB SG_ 406 SLL_StaReflauf 500;
BA_REL_ "GenSigTimeoutTime" BU_SG_REL_ AFS SG_ 406 SLL_StaStGlTst 500;
BA_REL_ "GenSigTimeoutTime" BU_SG_REL_ BCM1 SG_ 406 SLL_StaStGlTst 500;
BA_REL_ "GenSigTimeoutTime" BU_SG_REL_ FCM SG_ 406 SLL_StaStGlTst 500;
BA_REL_ "GenSigTimeoutTime" BU_SG_REL_ MXB SG_ 406 SLL_StaStGlTst 500;
BA_REL_ "GenSigTimeoutTime" BU_SG_REL_ AFS SG_ 406 SLL_BestFehlosch 500;
BA_REL_ "GenSigTimeoutTime" BU_SG_REL_ BCM1 SG_ 406 SLL_BestFehlosch 500;
BA_REL_ "GenSigTimeoutTime" BU_SG_REL_ FCM SG_ 406 SLL_BestFehlosch 500;
BA_REL_ "GenSigTimeoutTime" BU_SG_REL_ MXB SG_ 406 SLL_BestFehlosch 500;
BA_REL_ "GenSigTimeoutTime" BU_SG_REL_ AFS SG_ 406 SLL_StaAFSElMod 500;
BA_REL_ "GenSigTimeoutTime" BU_SG_REL_ BCM1 SG_ 406 SLL_StaAFSElMod 500;
BA_REL_ "GenSigTimeoutTime" BU_SG_REL_ FCM SG_ 406 SLL_StaAFSElMod 500;
BA_REL_ "GenSigTimeoutTime" BU_SG_REL_ MXB SG_ 406 SLL_StaAFSElMod 500;
BA_REL_ "GenSigTimeoutTime" BU_SG_REL_ AFS SG_ 406 SLL_StaTieftempFlag 500;
BA_REL_ "GenSigTimeoutTime" BU_SG_REL_ BCM1 SG_ 406 SLL_StaTieftempFlag 500;
BA_REL_ "GenSigTimeoutTime" BU_SG_REL_ FCM SG_ 406 SLL_StaTieftempFlag 500;
BA_REL_ "GenSigTimeoutTime" BU_SG_REL_ MXB SG_ 406 SLL_StaTieftempFlag 500;
BA_REL_ "GenSigTimeoutTime" BU_SG_REL_ AFS SG_ 408 SLR_IstPos 500;
BA_REL_ "GenSigTimeoutTime" BU_SG_REL_ BCM1 SG_ 408 SLR_IstPos 500;
BA_REL_ "GenSigTimeoutTime" BU_SG_REL_ FCM SG_ 408 SLR_IstPos 500;
BA_REL_ "GenSigTimeoutTime" BU_SG_REL_ MXB SG_ 408 SLR_IstPos 500;
BA_REL_ "GenSigTimeoutTime" BU_SG_REL_ AFS SG_ 408 SLR_StaStStWiederstart 500;
BA_REL_ "GenSigTimeoutTime" BU_SG_REL_ BCM1 SG_ 408 SLR_StaStStWiederstart 500;
BA_REL_ "GenSigTimeoutTime" BU_SG_REL_ FCM SG_ 408 SLR_StaStStWiederstart 500;
BA_REL_ "GenSigTimeoutTime" BU_SG_REL_ LED_LM_R SG_ 408 SLR_StaStStWiederstart 500;
BA_REL_ "GenSigTimeoutTime" BU_SG_REL_ MXB SG_ 408 SLR_StaStStWiederstart 500;
BA_REL_ "GenSigTimeoutTime" BU_SG_REL_ MXB_LM_R SG_ 408 SLR_StaStStWiederstart 500;
BA_REL_ "GenSigTimeoutTime" BU_SG_REL_ AFS SG_ 408 SLR_StaStStMotorstopp 500;
BA_REL_ "GenSigTimeoutTime" BU_SG_REL_ BCM1 SG_ 408 SLR_StaStStMotorstopp 500;
BA_REL_ "GenSigTimeoutTime" BU_SG_REL_ FCM SG_ 408 SLR_StaStStMotorstopp 500;
BA_REL_ "GenSigTimeoutTime" BU_SG_REL_ LED_LM_R SG_ 408 SLR_StaStStMotorstopp 500;
BA_REL_ "GenSigTimeoutTime" BU_SG_REL_ MXB SG_ 408 SLR_StaStStMotorstopp 500;
BA_REL_ "GenSigTimeoutTime" BU_SG_REL_ MXB_LM_R SG_ 408 SLR_StaStStMotorstopp 500;
BA_REL_ "GenSigTimeoutTime" BU_SG_REL_ AFS SG_ 408 SLR_IstPosMot 500;
BA_REL_ "GenSigTimeoutTime" BU_SG_REL_ BCM1 SG_ 408 SLR_IstPosMot 500;
BA_REL_ "GenSigTimeoutTime" BU_SG_REL_ FCM SG_ 408 SLR_IstPosMot 500;
BA_REL_ "GenSigTimeoutTime" BU_SG_REL_ MXB SG_ 408 SLR_IstPosMot 500;
BA_REL_ "GenSigTimeoutTime" BU_SG_REL_ AFS SG_ 408 SLR_StaVerst 500;
BA_REL_ "GenSigTimeoutTime" BU_SG_REL_ BCM1 SG_ 408 SLR_StaVerst 500;
BA_REL_ "GenSigTimeoutTime" BU_SG_REL_ FCM SG_ 408 SLR_StaVerst 500;
BA_REL_ "GenSigTimeoutTime" BU_SG_REL_ MXB SG_ 408 SLR_StaVerst 500;
BA_REL_ "GenSigTimeoutTime" BU_SG_REL_ AFS SG_ 408 SLR_StaFehPos 500;
BA_REL_ "GenSigTimeoutTime" BU_SG_REL_ BCM1 SG_ 408 SLR_StaFehPos 500;
BA_REL_ "GenSigTimeoutTime" BU_SG_REL_ FCM SG_ 408 SLR_StaFehPos 500;
BA_REL_ "GenSigTimeoutTime" BU_SG_REL_ MXB SG_ 408 SLR_StaFehPos 500;
BA_REL_ "GenSigTimeoutTime" BU_SG_REL_ AFS SG_ 408 SLR_StaReflauf 500;
BA_REL_ "GenSigTimeoutTime" BU_SG_REL_ BCM1 SG_ 408 SLR_StaReflauf 500;
BA_REL_ "GenSigTimeoutTime" BU_SG_REL_ FCM SG_ 408 SLR_StaReflauf 500;
BA_REL_ "GenSigTimeoutTime" BU_SG_REL_ MXB SG_ 408 SLR_StaReflauf 500;
BA_REL_ "GenSigTimeoutTime" BU_SG_REL_ AFS SG_ 408 SLR_StaStGlTst 500;
BA_REL_ "GenSigTimeoutTime" BU_SG_REL_ BCM1 SG_ 408 SLR_StaStGlTst 500;
BA_REL_ "GenSigTimeoutTime" BU_SG_REL_ FCM SG_ 408 SLR_StaStGlTst 500;
BA_REL_ "GenSigTimeoutTime" BU_SG_REL_ MXB SG_ 408 SLR_StaStGlTst 500;
BA_REL_ "GenSigTimeoutTime" BU_SG_REL_ AFS SG_ 408 SLR_BestFehlosch 500;
BA_REL_ "GenSigTimeoutTime" BU_SG_REL_ BCM1 SG_ 408 SLR_BestFehlosch 500;
BA_REL_ "GenSigTimeoutTime" BU_SG_REL_ FCM SG_ 408 SLR_BestFehlosch 500;
BA_REL_ "GenSigTimeoutTime" BU_SG_REL_ MXB SG_ 408 SLR_BestFehlosch 500;
BA_REL_ "GenSigTimeoutTime" BU_SG_REL_ AFS SG_ 408 SLR_StaAFSElMod 500;
BA_REL_ "GenSigTimeoutTime" BU_SG_REL_ BCM1 SG_ 408 SLR_StaAFSElMod 500;
BA_REL_ "GenSigTimeoutTime" BU_SG_REL_ FCM SG_ 408 SLR_StaAFSElMod 500;
BA_REL_ "GenSigTimeoutTime" BU_SG_REL_ MXB SG_ 408 SLR_StaAFSElMod 500;
BA_REL_ "GenSigTimeoutTime" BU_SG_REL_ AFS SG_ 408 SLR_StaTieftempFlag 500;
BA_REL_ "GenSigTimeoutTime" BU_SG_REL_ BCM1 SG_ 408 SLR_StaTieftempFlag 500;
BA_REL_ "GenSigTimeoutTime" BU_SG_REL_ FCM SG_ 408 SLR_StaTieftempFlag 500;
BA_REL_ "GenSigTimeoutTime" BU_SG_REL_ MXB SG_ 408 SLR_StaTieftempFlag 500;
BA_REL_ "GenSigTimeoutTime" BU_SG_REL_ LCM_L SG_ 958 MO_StartStopp_Wiederstart 1000;
BA_REL_ "GenSigTimeoutTime" BU_SG_REL_ LCM_R SG_ 958 MO_StartStopp_Wiederstart 1000;
BA_REL_ "GenSigTimeoutTime" BU_SG_REL_ LLP_L SG_ 958 MO_StartStopp_Wiederstart 1000;
BA_REL_ "GenSigTimeoutTime" BU_SG_REL_ LLP_R SG_ 958 MO_StartStopp_Wiederstart 1000;
BA_REL_ "GenSigTimeoutTime" BU_SG_REL_ LCM_L SG_ 958 MO_StartStopp_Motorstopp 1000;
BA_REL_ "GenSigTimeoutTime" BU_SG_REL_ LCM_R SG_ 958 MO_StartStopp_Motorstopp 1000;
BA_REL_ "GenSigTimeoutTime" BU_SG_REL_ LLP_L SG_ 958 MO_StartStopp_Motorstopp 1000;
BA_REL_ "GenSigTimeoutTime" BU_SG_REL_ LLP_R SG_ 958 MO_StartStopp_Motorstopp 1000;
BA_REL_ "GenSigTimeoutTime" BU_SG_REL_ LCM_L SG_ 958 MO_Kl_75 1000;
BA_REL_ "GenSigTimeoutTime" BU_SG_REL_ LCM_R SG_ 958 MO_Kl_75 1000;
BA_REL_ "GenSigTimeoutTime" BU_SG_REL_ LLP_L SG_ 958 MO_Kl_75 1000;
BA_REL_ "GenSigTimeoutTime" BU_SG_REL_ LLP_R SG_ 958 MO_Kl_75 1000;
BA_REL_ "GenSigTimeoutTime" BU_SG_REL_ BCM1 SG_ 994 MXB_Allgemein_li_defekt 5000;
BA_REL_ "GenSigTimeoutTime" BU_SG_REL_ BCM1 SG_ 994 MXB_Allgemein_re_defekt 5000;
BA_REL_ "GenSigTimeoutTime" BU_SG_REL_ BCM1 SG_ 994 MXB_Fernlicht_li_defekt 5000;
BA_REL_ "GenSigTimeoutTime" BU_SG_REL_ BCM1 SG_ 994 MXB_Fernlicht_re_defekt 5000;
BA_REL_ "GenSigTimeoutTime" BU_SG_REL_ BCM1 SG_ 994 MXB_Fernlicht_Status 5000;
BA_REL_ "GenSigTimeoutTime" BU_SG_REL_ BCM1 SG_ 994 MXB_Sicherheitspos_li_Anf 5000;
BA_REL_ "GenSigTimeoutTime" BU_SG_REL_ BCM1 SG_ 994 MXB_Sicherheitspos_re_Anf 5000;
BA_REL_ "GenSigTimeoutTime" BU_SG_REL_ BCM1 SG_ 994 MXB_Verfuegbarkeit 5000;
BA_REL_ "GenSigTimeoutTime" BU_SG_REL_ BCM1 SG_ 994 Kamera_Sensor_blockiert 5000;
BA_REL_ "GenSigTimeoutTime" BU_SG_REL_ BCM1 SG_ 994 AFS_Allwetterlicht_Unterdrueck 5000;
BA_REL_ "GenSigTimeoutTime" BU_SG_REL_ BCM1 SG_ 994 AFS_Autobahnlicht_Unterdrueckung 5000;
BA_REL_ "GenSigTimeoutTime" BU_SG_REL_ BCM1 SG_ 994 AFS_Blinkermode_BVS 5000;
BA_REL_ "GenSigTimeoutTime" BU_SG_REL_ BCM1 SG_ 994 AFS_Fehlertext_BVS 5000;
BA_REL_ "GenSigTimeoutTime" BU_SG_REL_ BCM1 SG_ 994 AFS_Lampe_BVS 5000;
BA_REL_ "GenSigTimeoutTime" BU_SG_REL_ BCM1 SG_ 994 AFS_Stadtlicht_Unterdrueckung 5000;
BA_REL_ "GenSigTimeoutTime" BU_SG_REL_ BCM1 SG_ 994 MXB_Z_Fernlicht_L_Anf 5000;
BA_REL_ "GenSigTimeoutTime" BU_SG_REL_ BCM1 SG_ 994 MXB_Z_Fernlicht_L_Schaltart 5000;
BA_REL_ "GenSigTimeoutTime" BU_SG_REL_ BCM1 SG_ 994 MXB_Z_Fernlicht_R_Anf 5000;
BA_REL_ "GenSigTimeoutTime" BU_SG_REL_ BCM1 SG_ 994 MXB_Z_Fernlicht_R_Schaltart 5000;
BA_REL_ "GenSigTimeoutTime" BU_SG_REL_ BCM1 SG_ 2463978604 MXB_Blickwinkel_L 1000;
BA_REL_ "GenSigTimeoutTime" BU_SG_REL_ BCM1 SG_ 2463978604 MXB_Blickwinkel_R 1000;
BA_REL_ "GenSigTimeoutTime" BU_SG_REL_ BCM1 SG_ 2463978604 MXB_Baustellenlicht_L_Anf 1000;
BA_REL_ "GenSigTimeoutTime" BU_SG_REL_ BCM1 SG_ 2463978604 MXB_Baustellenlicht_R_Anf 1000;
BA_REL_ "GenSigTimeoutTime" BU_SG_REL_ BCM1 SG_ 2463978604 MXB_AWL_Sichtweitenanpassung 1000;
BA_REL_ "GenSigTimeoutTime" BU_SG_REL_ AFS SG_ 1358 MXB_L_Fernl_MXB_Def_1 2000;
BA_REL_ "GenSigTimeoutTime" BU_SG_REL_ FCM SG_ 1358 MXB_L_Fernl_MXB_Def_1 2000;
BA_REL_ "GenSigTimeoutTime" BU_SG_REL_ MXB SG_ 1358 MXB_L_Fernl_MXB_Def_1 2000;
BA_REL_ "GenSigTimeoutTime" BU_SG_REL_ AFS SG_ 1358 MXB_L_Fernl_MXB_Def_2 2000;
BA_REL_ "GenSigTimeoutTime" BU_SG_REL_ FCM SG_ 1358 MXB_L_Fernl_MXB_Def_2 2000;
BA_REL_ "GenSigTimeoutTime" BU_SG_REL_ MXB SG_ 1358 MXB_L_Fernl_MXB_Def_2 2000;
BA_REL_ "GenSigTimeoutTime" BU_SG_REL_ AFS SG_ 1358 MXB_L_Fernl_MXB_Def_3 2000;
BA_REL_ "GenSigTimeoutTime" BU_SG_REL_ FCM SG_ 1358 MXB_L_Fernl_MXB_Def_3 2000;
BA_REL_ "GenSigTimeoutTime" BU_SG_REL_ MXB SG_ 1358 MXB_L_Fernl_MXB_Def_3 2000;
BA_REL_ "GenSigTimeoutTime" BU_SG_REL_ AFS SG_ 1358 MXB_L_Fernl_MXB_Def_4 2000;
BA_REL_ "GenSigTimeoutTime" BU_SG_REL_ FCM SG_ 1358 MXB_L_Fernl_MXB_Def_4 2000;
BA_REL_ "GenSigTimeoutTime" BU_SG_REL_ MXB SG_ 1358 MXB_L_Fernl_MXB_Def_4 2000;
BA_REL_ "GenSigTimeoutTime" BU_SG_REL_ AFS SG_ 1358 MXB_L_Fernl_MXB_Def_5 2000;
BA_REL_ "GenSigTimeoutTime" BU_SG_REL_ FCM SG_ 1358 MXB_L_Fernl_MXB_Def_5 2000;
BA_REL_ "GenSigTimeoutTime" BU_SG_REL_ MXB SG_ 1358 MXB_L_Fernl_MXB_Def_5 2000;
BA_REL_ "GenSigTimeoutTime" BU_SG_REL_ AFS SG_ 1358 MXB_L_Fernl_MXB_Def_6 2000;
BA_REL_ "GenSigTimeoutTime" BU_SG_REL_ FCM SG_ 1358 MXB_L_Fernl_MXB_Def_6 2000;
BA_REL_ "GenSigTimeoutTime" BU_SG_REL_ MXB SG_ 1358 MXB_L_Fernl_MXB_Def_6 2000;
BA_REL_ "GenSigTimeoutTime" BU_SG_REL_ AFS SG_ 1358 MXB_L_Fernl_MXB_Def_7 2000;
BA_REL_ "GenSigTimeoutTime" BU_SG_REL_ FCM SG_ 1358 MXB_L_Fernl_MXB_Def_7 2000;
BA_REL_ "GenSigTimeoutTime" BU_SG_REL_ MXB SG_ 1358 MXB_L_Fernl_MXB_Def_7 2000;
BA_REL_ "GenSigTimeoutTime" BU_SG_REL_ AFS SG_ 1358 MXB_L_Fernl_MXB_Def_Err_Gultig 2000;
BA_REL_ "GenSigTimeoutTime" BU_SG_REL_ FCM SG_ 1358 MXB_L_Fernl_MXB_Def_Err_Gultig 2000;
BA_REL_ "GenSigTimeoutTime" BU_SG_REL_ MXB SG_ 1358 MXB_L_Fernl_MXB_Def_Err_Gultig 2000;
BA_REL_ "GenSigTimeoutTime" BU_SG_REL_ AFS SG_ 1358 MXB_L_Allg_Elektr_Def_1 2000;
BA_REL_ "GenSigTimeoutTime" BU_SG_REL_ FCM SG_ 1358 MXB_L_Allg_Elektr_Def_1 2000;
BA_REL_ "GenSigTimeoutTime" BU_SG_REL_ MXB SG_ 1358 MXB_L_Allg_Elektr_Def_1 2000;
BA_REL_ "GenSigTimeoutTime" BU_SG_REL_ AFS SG_ 1358 MXB_L_Allg_Elektr_Def_2 2000;
BA_REL_ "GenSigTimeoutTime" BU_SG_REL_ FCM SG_ 1358 MXB_L_Allg_Elektr_Def_2 2000;
BA_REL_ "GenSigTimeoutTime" BU_SG_REL_ MXB SG_ 1358 MXB_L_Allg_Elektr_Def_2 2000;
BA_REL_ "GenSigTimeoutTime" BU_SG_REL_ AFS SG_ 1358 MXB_L_Allg_Elektr_Def_3 2000;
BA_REL_ "GenSigTimeoutTime" BU_SG_REL_ FCM SG_ 1358 MXB_L_Allg_Elektr_Def_3 2000;
BA_REL_ "GenSigTimeoutTime" BU_SG_REL_ MXB SG_ 1358 MXB_L_Allg_Elektr_Def_3 2000;
BA_REL_ "GenSigTimeoutTime" BU_SG_REL_ AFS SG_ 1358 MXB_L_Allg_Elektr_Def_4 2000;
BA_REL_ "GenSigTimeoutTime" BU_SG_REL_ FCM SG_ 1358 MXB_L_Allg_Elektr_Def_4 2000;
BA_REL_ "GenSigTimeoutTime" BU_SG_REL_ MXB SG_ 1358 MXB_L_Allg_Elektr_Def_4 2000;
BA_REL_ "GenSigTimeoutTime" BU_SG_REL_ AFS SG_ 1358 MXB_L_Allg_Elektr_Def_5 2000;
BA_REL_ "GenSigTimeoutTime" BU_SG_REL_ FCM SG_ 1358 MXB_L_Allg_Elektr_Def_5 2000;
BA_REL_ "GenSigTimeoutTime" BU_SG_REL_ MXB SG_ 1358 MXB_L_Allg_Elektr_Def_5 2000;
BA_REL_ "GenSigTimeoutTime" BU_SG_REL_ AFS SG_ 1358 MXB_L_Allg_Elektr_Def_6 2000;
BA_REL_ "GenSigTimeoutTime" BU_SG_REL_ FCM SG_ 1358 MXB_L_Allg_Elektr_Def_6 2000;
BA_REL_ "GenSigTimeoutTime" BU_SG_REL_ MXB SG_ 1358 MXB_L_Allg_Elektr_Def_6 2000;
BA_REL_ "GenSigTimeoutTime" BU_SG_REL_ AFS SG_ 1358 MXB_L_Allg_Elektr_Def_7 2000;
BA_REL_ "GenSigTimeoutTime" BU_SG_REL_ FCM SG_ 1358 MXB_L_Allg_Elektr_Def_7 2000;
BA_REL_ "GenSigTimeoutTime" BU_SG_REL_ MXB SG_ 1358 MXB_L_Allg_Elektr_Def_7 2000;
BA_REL_ "GenSigTimeoutTime" BU_SG_REL_ AFS SG_ 1358 MXB_L_Allg_Elektr_Def_8 2000;
BA_REL_ "GenSigTimeoutTime" BU_SG_REL_ FCM SG_ 1358 MXB_L_Allg_Elektr_Def_8 2000;
BA_REL_ "GenSigTimeoutTime" BU_SG_REL_ MXB SG_ 1358 MXB_L_Allg_Elektr_Def_8 2000;
BA_REL_ "GenSigTimeoutTime" BU_SG_REL_ AFS SG_ 1358 MXB_L_Allg_Elektr_Def_Err_Gultig 2000;
BA_REL_ "GenSigTimeoutTime" BU_SG_REL_ FCM SG_ 1358 MXB_L_Allg_Elektr_Def_Err_Gultig 2000;
BA_REL_ "GenSigTimeoutTime" BU_SG_REL_ MXB SG_ 1358 MXB_L_Allg_Elektr_Def_Err_Gultig 2000;
BA_REL_ "GenSigTimeoutTime" BU_SG_REL_ AFS SG_ 1358 MXB_L_Luefter_1_Def_1 2000;
BA_REL_ "GenSigTimeoutTime" BU_SG_REL_ FCM SG_ 1358 MXB_L_Luefter_1_Def_1 2000;
BA_REL_ "GenSigTimeoutTime" BU_SG_REL_ MXB SG_ 1358 MXB_L_Luefter_1_Def_1 2000;
BA_REL_ "GenSigTimeoutTime" BU_SG_REL_ AFS SG_ 1358 MXB_L_Luefter_1_Def_2 2000;
BA_REL_ "GenSigTimeoutTime" BU_SG_REL_ FCM SG_ 1358 MXB_L_Luefter_1_Def_2 2000;
BA_REL_ "GenSigTimeoutTime" BU_SG_REL_ MXB SG_ 1358 MXB_L_Luefter_1_Def_2 2000;
BA_REL_ "GenSigTimeoutTime" BU_SG_REL_ AFS SG_ 1358 MXB_L_Luefter_1_Def_3 2000;
BA_REL_ "GenSigTimeoutTime" BU_SG_REL_ FCM SG_ 1358 MXB_L_Luefter_1_Def_3 2000;
BA_REL_ "GenSigTimeoutTime" BU_SG_REL_ MXB SG_ 1358 MXB_L_Luefter_1_Def_3 2000;
BA_REL_ "GenSigTimeoutTime" BU_SG_REL_ AFS SG_ 1358 MXB_L_Luefter_1_Def_4 2000;
BA_REL_ "GenSigTimeoutTime" BU_SG_REL_ FCM SG_ 1358 MXB_L_Luefter_1_Def_4 2000;
BA_REL_ "GenSigTimeoutTime" BU_SG_REL_ MXB SG_ 1358 MXB_L_Luefter_1_Def_4 2000;
BA_REL_ "GenSigTimeoutTime" BU_SG_REL_ AFS SG_ 1358 MXB_L_Luefter_2_Def_1 2000;
BA_REL_ "GenSigTimeoutTime" BU_SG_REL_ FCM SG_ 1358 MXB_L_Luefter_2_Def_1 2000;
BA_REL_ "GenSigTimeoutTime" BU_SG_REL_ MXB SG_ 1358 MXB_L_Luefter_2_Def_1 2000;
BA_REL_ "GenSigTimeoutTime" BU_SG_REL_ AFS SG_ 1358 MXB_L_Luefter_2_Def_2 2000;
BA_REL_ "GenSigTimeoutTime" BU_SG_REL_ FCM SG_ 1358 MXB_L_Luefter_2_Def_2 2000;
BA_REL_ "GenSigTimeoutTime" BU_SG_REL_ MXB SG_ 1358 MXB_L_Luefter_2_Def_2 2000;
BA_REL_ "GenSigTimeoutTime" BU_SG_REL_ AFS SG_ 1358 MXB_L_Luefter_2_Def_3 2000;
BA_REL_ "GenSigTimeoutTime" BU_SG_REL_ FCM SG_ 1358 MXB_L_Luefter_2_Def_3 2000;
BA_REL_ "GenSigTimeoutTime" BU_SG_REL_ MXB SG_ 1358 MXB_L_Luefter_2_Def_3 2000;
BA_REL_ "GenSigTimeoutTime" BU_SG_REL_ AFS SG_ 1358 MXB_L_Luefter_2_Def_4 2000;
BA_REL_ "GenSigTimeoutTime" BU_SG_REL_ FCM SG_ 1358 MXB_L_Luefter_2_Def_4 2000;
BA_REL_ "GenSigTimeoutTime" BU_SG_REL_ MXB SG_ 1358 MXB_L_Luefter_2_Def_4 2000;
BA_REL_ "GenSigTimeoutTime" BU_SG_REL_ AFS SG_ 1358 MXB_L_Luefter_1_Def_Err_Gultig 2000;
BA_REL_ "GenSigTimeoutTime" BU_SG_REL_ FCM SG_ 1358 MXB_L_Luefter_1_Def_Err_Gultig 2000;
BA_REL_ "GenSigTimeoutTime" BU_SG_REL_ MXB SG_ 1358 MXB_L_Luefter_1_Def_Err_Gultig 2000;
BA_REL_ "GenSigTimeoutTime" BU_SG_REL_ AFS SG_ 1358 MXB_L_Luefter_2_Def_Err_Gultig 2000;
BA_REL_ "GenSigTimeoutTime" BU_SG_REL_ FCM SG_ 1358 MXB_L_Luefter_2_Def_Err_Gultig 2000;
BA_REL_ "GenSigTimeoutTime" BU_SG_REL_ MXB SG_ 1358 MXB_L_Luefter_2_Def_Err_Gultig 2000;
BA_REL_ "GenSigTimeoutTime" BU_SG_REL_ AFS SG_ 1358 MXB_L_Allg_Elektr_Def 2000;
BA_REL_ "GenSigTimeoutTime" BU_SG_REL_ BCM1 SG_ 1358 MXB_L_Allg_Elektr_Def 2000;
BA_REL_ "GenSigTimeoutTime" BU_SG_REL_ FCM SG_ 1358 MXB_L_Allg_Elektr_Def 2000;
BA_REL_ "GenSigTimeoutTime" BU_SG_REL_ MXB SG_ 1358 MXB_L_Allg_Elektr_Def 2000;
BA_REL_ "GenSigTimeoutTime" BU_SG_REL_ AFS SG_ 1358 MXB_L_Fernl_MXB_Def 2000;
BA_REL_ "GenSigTimeoutTime" BU_SG_REL_ BCM1 SG_ 1358 MXB_L_Fernl_MXB_Def 2000;
BA_REL_ "GenSigTimeoutTime" BU_SG_REL_ FCM SG_ 1358 MXB_L_Fernl_MXB_Def 2000;
BA_REL_ "GenSigTimeoutTime" BU_SG_REL_ MXB SG_ 1358 MXB_L_Fernl_MXB_Def 2000;
VAL_ 1389 LED_L_Uspg_Schutz 0 "Unterspannungsschutz_nicht_aktiv" 1 "Unterspannungsschutz_aktiv" ;
VAL_ 1389 LED_L_Spannung_KL15 126 "Init" 127 "Fehler" ;
VAL_ 1389 LED_L_Spannung_KL56a 126 "Init" 127 "Fehler" ;
VAL_ 1389 LED_L_Spannung_KL56b 126 "Init" 127 "Fehler" ;
VAL_ 1389 LED_L_Spannung_TFL 126 "Init" 127 "Fehler" ;
VAL_ 1389 LED_L_Temp_Schutz 0 "Temperaturschutz_nicht_aktiv" 1 "Temperaturschutz_aktiv" ;
VAL_ 1389 LED_L_Temp_Mux 0 "Temp_SG_intern" 1 "Temp_Kanal1_Master" 2 "Temp_Kanal1_Master2" 3 "Temp_Kanal1_Slave" 4 "Temp_Kanal2_Master" 5 "Temp_Kanal2_Slave" 6 "Temp_Kanal3_Master" 7 "Temp_Kanal3_Slave" ;
VAL_ 1389 LED_L_Temp_SG_Intern 0 "Init" 255 "Fehler" ;
VAL_ 1389 LED_L_Temp_Kanal1_Master 0 "Init" 255 "Fehler" ;
VAL_ 1389 LED_L_Temp_Kanal1_Master2 0 "Init" 255 "Fehler" ;
VAL_ 1389 LED_L_Temp_Kanal1_Slave 0 "Init" 255 "Fehler" ;
VAL_ 1389 LED_L_Temp_Kanal2_Master 0 "Init" 255 "Fehler" ;
VAL_ 1389 LED_L_Temp_Kanal2_Slave 0 "Init" 255 "Fehler" ;
VAL_ 1389 LED_L_Temp_Kanal3_Master 0 "Init" 255 "Fehler" ;
VAL_ 1389 LED_L_Temp_Kanal3_Slave 0 "Init" 255 "Fehler" ;
VAL_ 1395 LED_L_Strom_Kanal1_Master 510 "Init" 511 "Kanal_nicht_genutzt" ;
VAL_ 1395 LED_L_Strom_Kanal1_Master2 510 "Init" 511 "Kanal_nicht_genutzt" ;
VAL_ 1395 LED_L_Strom_Kanal1_Slave 510 "Init" 511 "Kanal_nicht_genutzt" ;
VAL_ 1395 LED_L_Strom_Kanal2_Master 510 "Init" 511 "Kanal_nicht_genutzt" ;
VAL_ 1395 LED_L_Strom_Kanal2_Slave 510 "Init" 511 "Kanal_nicht_genutzt" ;
VAL_ 1395 LED_L_Strom_Kanal3_Master 510 "Init" 511 "Kanal_nicht_genutzt" ;
VAL_ 1395 LED_L_Strom_Kanal3_Slave 510 "Init" 511 "Kanal_nicht_genutzt" ;
VAL_ 1395 LED_L_Tag_Nacht_Umschaltung_Sta 0 "Tagbetrieb" 1 "Nachtbetrieb" ;
VAL_ 1390 LED_R_Uspg_Schutz 0 "Unterspannungsschutz_nicht_aktiv" 1 "Unterspannungsschutz_aktiv" ;
VAL_ 1390 LED_R_Spannung_KL15 126 "Init" 127 "Fehler" ;
VAL_ 1390 LED_R_Spannung_KL56a 126 "Init" 127 "Fehler" ;
VAL_ 1390 LED_R_Spannung_KL56b 126 "Init" 127 "Fehler" ;
VAL_ 1390 LED_R_Spannung_TFL 126 "Init" 127 "Fehler" ;
VAL_ 1390 LED_R_Temp_Schutz 0 "Temperaturschutz_nicht_aktiv" 1 "Temperaturschutz_aktiv" ;
VAL_ 1390 LED_R_Temp_Mux 0 "Temp_SG_intern" 1 "Temp_Kanal1_Master" 2 "Temp_Kanal1_Master2" 3 "Temp_Kanal1_Slave" 4 "Temp_Kanal2_Master" 5 "Temp_Kanal2_Slave" 6 "Temp_Kanal3_Master" 7 "Temp_Kanal3_Slave" ;
VAL_ 1390 LED_R_Temp_SG_Intern 0 "Init" 255 "Fehler" ;
VAL_ 1390 LED_R_Temp_Kanal1_Master 0 "Init" 255 "Fehler" ;
VAL_ 1390 LED_R_Temp_Kanal1_Master2 0 "Init" 255 "Fehler" ;
VAL_ 1390 LED_R_Temp_Kanal1_Slave 0 "Init" 255 "Fehler" ;
VAL_ 1390 LED_R_Temp_Kanal2_Master 0 "Init" 255 "Fehler" ;
VAL_ 1390 LED_R_Temp_Kanal2_Slave 0 "Init" 255 "Fehler" ;
VAL_ 1390 LED_R_Temp_Kanal3_Master 0 "Init" 255 "Fehler" ;
VAL_ 1390 LED_R_Temp_Kanal3_Slave 0 "Init" 255 "Fehler" ;
VAL_ 1396 LED_R_Strom_Kanal1_Master 510 "Init" 511 "Kanal_nicht_genutzt" ;
VAL_ 1396 LED_R_Strom_Kanal1_Master2 510 "Init" 511 "Kanal_nicht_genutzt" ;
VAL_ 1396 LED_R_Strom_Kanal1_Slave 510 "Init" 511 "Kanal_nicht_genutzt" ;
VAL_ 1396 LED_R_Strom_Kanal2_Master 510 "Init" 511 "Kanal_nicht_genutzt" ;
VAL_ 1396 LED_R_Strom_Kanal2_Slave 510 "Init" 511 "Kanal_nicht_genutzt" ;
VAL_ 1396 LED_R_Strom_Kanal3_Master 510 "Init" 511 "Kanal_nicht_genutzt" ;
VAL_ 1396 LED_R_Strom_Kanal3_Slave 510 "Init" 511 "Kanal_nicht_genutzt" ;
VAL_ 1396 LED_R_Tag_Nacht_Umschaltung_Sta 0 "Tagbetrieb" 1 "Nachtbetrieb" ;
VAL_ 404 LED_L_Abblendl_Anf 0 "nicht_angefordert" 1 "angefordert" ;
VAL_ 404 LED_L_Abblendl_Schaltart 0 "Schalten_hart" 1 "Schalten_mit_Rampe" ;
VAL_ 404 LED_R_Abblendl_Anf 0 "nicht_angefordert" 1 "angefordert" ;
VAL_ 404 LED_R_Abblendl_Schaltart 0 "Schalten_hart" 1 "Schalten_mit_Rampe" ;
VAL_ 404 LED_L_Fernl_LH_Anf 0 "nicht_angefordert" 1 "angefordert" ;
VAL_ 404 LED_L_Fernl_LH_Schaltart 0 "Schalten_hart" 1 "Schalten_mit_Rampe" ;
VAL_ 404 LED_R_Fernl_LH_Anf 0 "nicht_angefordert" 1 "angefordert" ;
VAL_ 404 LED_R_Fernl_LH_Schaltart 0 "Schalten_hart" 1 "Schalten_mit_Rampe" ;
VAL_ 404 LED_L_Nebel_All_Anf 0 "nicht_angefordert" 1 "angefordert" ;
VAL_ 404 LED_L_Nebel_All_Schaltart 0 "Schalten_hart" 1 "Schalten_mit_Rampe" ;
VAL_ 404 LED_R_Nebel_All_Anf 0 "nicht_angefordert" 1 "angefordert" ;
VAL_ 404 LED_R_Nebel_All_Schaltart 0 "Schalten_hart" 1 "Schalten_mit_Rampe" ;
VAL_ 404 LED_Sta_Diag 0 "Init" 5 "Diagnose_VAS_Tester_laeuft" 10 "Diagnose_nicht_eingeleitet" 15 "Codierung_eingeleitet" ;
VAL_ 404 LED_L_Zus_Fernl_LH_Anf 0 "nicht_angefordert" 1 "angefordert" ;
VAL_ 404 LED_L_Zus_Fernl_LH_Schaltart 0 "Schalten_hart" 1 "Schalten_mit_Rampe" ;
VAL_ 404 LED_R_Zus_Fernl_LH_Anf 0 "nicht_angefordert" 1 "angefordert" ;
VAL_ 404 LED_R_Zus_Fernl_LH_Schaltart 0 "Schalten_hart" 1 "Schalten_mit_Rampe" ;
VAL_ 405 LED_L_Abbiegel_Anf 0 "nicht_angefordert" 1 "angefordert" ;
VAL_ 405 LED_L_Abbiegel_Schaltart 0 "Schalten_hart" 1 "Schalten_mit_Rampe" ;
VAL_ 405 LED_R_Abbiegel_Anf 0 "nicht_angefordert" 1 "angefordert" ;
VAL_ 405 LED_R_Abbiegel_Schaltart 0 "Schalten_hart" 1 "Schalten_mit_Rampe" ;
VAL_ 405 LED_L_Autobahnl_Anf 0 "nicht_angefordert" 1 "angefordert" ;
VAL_ 405 LED_L_Autobahnl_Schaltart 0 "Schalten_hart" 1 "Schalten_mit_Rampe" ;
VAL_ 405 LED_R_Autobahnl_Anf 0 "nicht_angefordert" 1 "angefordert" ;
VAL_ 405 LED_R_Autobahnl_Schaltart 0 "Schalten_hart" 1 "Schalten_mit_Rampe" ;
VAL_ 405 LED_L_Eco_Mode_1_Anf 0 "nicht_angefordert" 1 "angefordert" ;
VAL_ 405 LED_L_Eco_Mode_1_Schaltart 0 "Schalten_hart" 1 "Schalten_mit_Rampe" ;
VAL_ 405 LED_R_Eco_Mode_1_Anf 0 "nicht_angefordert" 1 "angefordert" ;
VAL_ 405 LED_R_Eco_Mode_1_Schaltart 0 "Schalten_hart" 1 "Schalten_mit_Rampe" ;
VAL_ 405 LED_L_Eco_Mode_2_Anf 0 "nicht_angefordert" 1 "angefordert" ;
VAL_ 405 LED_L_Eco_Mode_2_Schaltart 0 "Schalten_hart" 1 "Schalten_mit_Rampe" ;
VAL_ 405 LED_R_Eco_Mode_2_Anf 0 "nicht_angefordert" 1 "angefordert" ;
VAL_ 405 LED_R_Eco_Mode_2_Schaltart 0 "Schalten_hart" 1 "Schalten_mit_Rampe" ;
VAL_ 405 LED_L_Rennl_Anf 0 "nicht_angefordert" 1 "angefordert" ;
VAL_ 405 LED_L_Rennl_Schaltart 0 "Schalten_hart" 1 "Schalten_mit_Rampe" ;
VAL_ 405 LED_R_Rennl_Anf 0 "nicht_angefordert" 1 "angefordert" ;
VAL_ 405 LED_R_Rennl_Schaltart 0 "Schalten_hart" 1 "Schalten_mit_Rampe" ;
VAL_ 405 LED_L_Stadtl_Anf 0 "nicht_angefordert" 1 "angefordert" ;
VAL_ 405 LED_L_Stadtl_Schaltart 0 "Schalten_hart" 1 "Schalten_mit_Rampe" ;
VAL_ 405 LED_R_Stadtl_Anf 0 "nicht_angefordert" 1 "angefordert" ;
VAL_ 405 LED_R_Stadtl_Schaltart 0 "Schalten_hart" 1 "Schalten_mit_Rampe" ;
VAL_ 405 LED_L_TFL_Anf 0 "TFL_aus_PO_aus" 1 "TFL_aus_PO_an" 2 "TFL_an_PO_aus" 3 "TFL_an_PO_an" ;
VAL_ 405 LED_L_TFL_Schaltart 0 "Schalten_hart" 1 "Schalten_mit_Rampe" ;
VAL_ 405 LED_R_TFL_Anf 0 "TFL_aus_PO_aus" 1 "TFL_aus_PO_an" 2 "TFL_an_PO_aus" 3 "TFL_an_PO_an" ;
VAL_ 405 LED_R_TFL_Schaltart 0 "Schalten_hart" 1 "Schalten_mit_Rampe" ;
VAL_ 405 LED_L_Touristenl_Anf 0 "nicht_angefordert" 1 "angefordert" ;
VAL_ 405 LED_L_Touristenl_Schaltart 0 "Schalten_hart" 1 "Schalten_mit_Rampe" ;
VAL_ 405 LED_R_Touristenl_Anf 0 "nicht_angefordert" 1 "angefordert" ;
VAL_ 405 LED_R_Touristenl_Schaltart 0 "Schalten_hart" 1 "Schalten_mit_Rampe" ;
VAL_ 405 LED_ECE_SAE_Umschaltung_Anf 0 "Anforderung_ECE" 1 "Anforderung_SAE" ;
VAL_ 405 LED_Tag_Nacht_Umschaltung_Anf 0 "nicht_angefordert" 1 "angefordert" ;
VAL_ 405 LED_Sta_Diag 0 "Init" 5 "Diagnose_VAS_Tester_laeuft" 10 "Diagnose_nicht_eingeleitet" 15 "Codierung_eingeleitet" ;
VAL_ 405 LED_L_Abbiegel_Dimmung 255 "Fehler" ;
VAL_ 405 LED_R_Abbiegel_Dimmung 255 "Fehler" ;
VAL_ 351 LED_L_Abblendl_Anf 0 "nicht_angefordert" 1 "angefordert" ;
VAL_ 351 LED_L_Abblendl_Schaltart 0 "Schalten_hart" 1 "Schalten_mit_Rampe" ;
VAL_ 351 LED_R_Abblendl_Anf 0 "nicht_angefordert" 1 "angefordert" ;
VAL_ 351 LED_R_Abblendl_Schaltart 0 "Schalten_hart" 1 "Schalten_mit_Rampe" ;
VAL_ 351 LED_L_Fernl_LH_Anf 0 "nicht_angefordert" 1 "angefordert" ;
VAL_ 351 LED_L_Fernl_LH_Schaltart 0 "Schalten_hart" 1 "Schalten_mit_Rampe" ;
VAL_ 351 LED_R_Fernl_LH_Anf 0 "nicht_angefordert" 1 "angefordert" ;
VAL_ 351 LED_R_Fernl_LH_Schaltart 0 "Schalten_hart" 1 "Schalten_mit_Rampe" ;
VAL_ 351 LED_L_Nebel_All_Anf 0 "nicht_angefordert" 1 "angefordert" ;
VAL_ 351 LED_L_Nebel_All_Schaltart 0 "Schalten_hart" 1 "Schalten_mit_Rampe" ;
VAL_ 351 LED_R_Nebel_All_Anf 0 "nicht_angefordert" 1 "angefordert" ;
VAL_ 351 LED_R_Nebel_All_Schaltart 0 "Schalten_hart" 1 "Schalten_mit_Rampe" ;
VAL_ 351 LED_Sta_Diag 0 "Init" 5 "Diagnose_VAS_Tester_laeuft" 10 "Diagnose_nicht_eingeleitet" 15 "Codierung_eingeleitet" ;
VAL_ 351 LED_L_Zus_Fernl_LH_Anf 0 "nicht_angefordert" 1 "angefordert" ;
VAL_ 351 LED_L_Zus_Fernl_LH_Schaltart 0 "Schalten_hart" 1 "Schalten_mit_Rampe" ;
VAL_ 351 LED_R_Zus_Fernl_LH_Anf 0 "nicht_angefordert" 1 "angefordert" ;
VAL_ 351 LED_R_Zus_Fernl_LH_Schaltart 0 "Schalten_hart" 1 "Schalten_mit_Rampe" ;
VAL_ 351 BCM1_CH_aktiv 0 "Inaktiv" 1 "Aktiv" ;
VAL_ 351 BCM1_LH_aktiv 0 "Inaktiv" 1 "Aktiv" ;
VAL_ 920 FLL_SchMot 0 "kein_Fehler" 1 "Fehler" ;
VAL_ 920 FLL_RSchMot 0 "Fehlermoeglichkeit_geprueft" 1 "Fehlermoeglichkeit_nicht_geprueft" ;
VAL_ 920 FLL_SM_KS_Gnd 0 "kein_Fehler" 1 "Fehler" ;
VAL_ 920 FLL_RSM_KS_Gnd 0 "Fehlermoeglichkeit_geprueft" 1 "Fehlermoeglichkeit_nicht_geprueft" ;
VAL_ 920 FLL_SM_UeSpg 0 "kein_Fehler" 1 "Fehler" ;
VAL_ 920 FLL_RSM_UeSpg 0 "Fehlermoeglichkeit_geprueft" 1 "Fehlermoeglichkeit_nicht_geprueft" ;
VAL_ 920 FLL_SM_USpg 0 "kein_Fehler" 1 "Fehler" ;
VAL_ 920 FLL_RSM_USpg 0 "Fehlermoeglichkeit_geprueft" 1 "Fehlermoeglichkeit_nicht_geprueft" ;
VAL_ 920 FLL_SM_UeTemp 0 "kein_Fehler" 1 "Fehler" ;
VAL_ 920 FLL_RSM_UeTemp 0 "Fehlermoeglichkeit_geprueft" 1 "Fehlermoeglichkeit_nicht_geprueft" ;
VAL_ 920 FLL_SM_TempPre 0 "kein_Fehler" 1 "Temp_Pre_Alarm" ;
VAL_ 920 FLL_RSM_TempPre 0 "Fehlermoeglichkeit_geprueft" 1 "Fehlermoeglichkeit_nicht_geprueft" ;
VAL_ 920 FLL_AFS_Unpl 0 "kein_Fehler" ;
VAL_ 920 FLL_RAFS_Unpl 0 "Fehlermoeglichkeit_geprueft" 1 "Fehlermoeglichkeit_nicht_geprueft" ;
VAL_ 922 FLR_SchMot 0 "kein_Fehler" 1 "Fehler" ;
VAL_ 922 FLR_RSchMot 0 "Fehlermoeglichkeit_geprueft" 1 "Fehlermoeglichkeit_nicht_geprueft" ;
VAL_ 922 FLR_SM_KS_Gnd 0 "kein_Fehler" 1 "Fehler" ;
VAL_ 922 FLR_RSM_KS_Gnd 0 "Fehlermoeglichkeit_geprueft" 1 "Fehlermoeglichkeit_nicht_geprueft" ;
VAL_ 922 FLR_SM_UeSpg 0 "kein_Fehler" 1 "Fehler" ;
VAL_ 922 FLR_RSM_UeSpg 0 "Fehlermoeglichkeit_geprueft" 1 "Fehlermoeglichkeit_nicht_geprueft" ;
VAL_ 922 FLR_SM_USpg 0 "kein_Fehler" 1 "Fehler" ;
VAL_ 922 FLR_RSM_USpg 0 "Fehlermoeglichkeit_geprueft" 1 "Fehlermoeglichkeit_nicht_geprueft" ;
VAL_ 922 FLR_SM_UeTemp 0 "kein_Fehler" 1 "Fehler" ;
VAL_ 922 FLR_RSM_UeTemp 0 "Fehlermoeglichkeit_geprueft" 1 "Fehlermoeglichkeit_nicht_geprueft" ;
VAL_ 922 FLR_SM_TempPre 0 "kein_Fehler" 1 "Temp_Pre_Alarm" ;
VAL_ 922 FLR_RSM_TempPre 0 "Fehlermoeglichkeit_geprueft" 1 "Fehlermoeglichkeit_nicht_geprueft" ;
VAL_ 922 FLR_AFS_Unpl 0 "kein_Fehler" ;
VAL_ 922 FLR_RAFS_Unpl 0 "Fehlermoeglichkeit_geprueft" 1 "Fehlermoeglichkeit_nicht_geprueft" ;
VAL_ 400 SOL_SollPos_L 4092 "reserviert" 4093 "Blockgrenze_unten" 4094 "Init" 4095 "Fehler" ;
VAL_ 400 SOL_FehlPos_L 0 "Fehlerfallpos_nicht_anfahren" 1 "Fehlerfallpos_anfahren" ;
VAL_ 400 SOL_RefLauf_L 0 "Referenzlauf_nicht_angefordert" 1 "Referenzlauf_angefordert" ;
VAL_ 400 SOL_StGlTest_L 0 "Stellgliedtest_nicht_angefordert" 1 "Stellgliedtest_angefordert" ;
VAL_ 400 SOL_Fehlloesch_L 0 "Fehlerloeschen_nicht_angefordert" 1 "Fehlerloeschen_angefordert" ;
VAL_ 400 MO_StartStopp_Motorstopp 0 "Motor_Stop_inaktiv" 1 "Motor_Stop_aktiv" ;
VAL_ 400 MO_StartStopp_Wiederstart 0 "Wiederstart_inaktiv" 1 "Wiederstart_aktiv" ;
VAL_ 400 SOL_Tieftemp_Flag 0 "keine_Tieftemperatur" 1 "Tieftemperatur" ;
VAL_ 400 SOL_SollPos_R 4092 "reserviert" 4093 "Blockgrenze_unten" 4094 "Init" 4095 "Fehler" ;
VAL_ 400 SOL_FehlPos_R 0 "Fehlerfallpos_nicht_anfahren" 1 "Fehlerfallpos_anfahren" ;
VAL_ 400 SOL_RefLauf_R 0 "Referenzlauf_nicht_angefordert" 1 "Referenzlauf_angefordert" ;
VAL_ 400 SOL_StGlTest_R 0 "Stellgliedtest_nicht_angefordert" 1 "Stellgliedtest_angefordert" ;
VAL_ 400 SOL_Fehlloesch_R 0 "Fehlerloeschen_nicht_angefordert" 1 "Fehlerloeschen_angefordert" ;
VAL_ 400 SOL_Sta_Diag 0 "Init" 5 "Diagnose_VAS_Tester_laeuft" 10 "Diagnose_nicht_eingeleitet" 15 "Codierung_eingeleitet" ;
VAL_ 406 SLL_IstPos 4093 "Blockgrenze_unten" 4094 "Init" 4095 "Fehler" ;
VAL_ 406 SLL_StaStStWiederstart 0 "Wiederstart_nicht_aktiv" 1 "Wiederstart_aktiv" ;
VAL_ 406 SLL_StaStStMotorstopp 0 "Motorstopp_nicht_aktiv" 1 "Motorstopp_aktiv" ;
VAL_ 406 SLL_IstPosMot 254 "Wert_unbekannt" 255 "Fehler" ;
VAL_ 406 SLL_StaVerst 0 "Schrittmotor_steht_still" 1 "Schrittmotor_verstellt" ;
VAL_ 406 SLL_StaFehPos 0 "Fehlerpos_nicht_angefahren" 1 "Fehlerpos_angefahren" ;
VAL_ 406 SLL_StaReflauf 0 "RefLauf_noch_nicht_erfolgt" 1 "RefLauf_erfolgt" ;
VAL_ 406 SLL_StaStGlTst 0 "Stellgliedtest_nicht_angefordert" 1 "Stellgliedtest_laeuft" ;
VAL_ 406 SLL_BestFehlosch 0 "Fehlerloesch_nicht_angef" 1 "Fehlerspeicher_geloescht" ;
VAL_ 406 SLL_StaAFSElMod 0 "Normalbetrieb" 1 "Betrieb_mit_red_Verstellgeschw" ;
VAL_ 406 SLL_StaTieftempFlag 0 "keine_Tieftemperatur" 1 "Tieftemperatur" ;
VAL_ 408 SLR_IstPos 4093 "Blockgrenze_unten" 4094 "Init" 4095 "Fehler" ;
VAL_ 408 SLR_StaStStWiederstart 0 "Wiederstart_nicht_aktiv" 1 "Wiederstart_aktiv" ;
VAL_ 408 SLR_StaStStMotorstopp 0 "Motorstopp_nicht_aktiv" 1 "Motorstopp_aktiv" ;
VAL_ 408 SLR_IstPosMot 254 "Wert_unbekannt" 255 "Fehler" ;
VAL_ 408 SLR_StaVerst 0 "Schrittmotor_steht_still" 1 "Schrittmotor_verstellt" ;
VAL_ 408 SLR_StaFehPos 0 "Fehlerpos_nicht_angefahren" 1 "Fehlerpos_angefahren" ;
VAL_ 408 SLR_StaReflauf 0 "RefLauf_noch_nicht_erfolgt" 1 "RefLauf_erfolgt" ;
VAL_ 408 SLR_StaStGlTst 0 "Stellgliedtest_nicht_angefordert" 1 "Stellgliedtest_laeuft" ;
VAL_ 408 SLR_BestFehlosch 0 "Fehlerloesch_nicht_angef" 1 "Fehlerspeicher_geloescht" ;
VAL_ 408 SLR_StaAFSElMod 0 "Normalbetrieb" 1 "Betrieb_mit_red_Verstellgeschw" ;
VAL_ 408 SLR_StaTieftempFlag 0 "keine_Tieftemperatur" 1 "Tieftemperatur" ;
VAL_ 958 MO_StartStopp_Status 0 "System_in_diesem_KL15_Zyklus_nicht_verfuegbar" 1 "System_aktiv_keine_Freigabe_durch_StartStop_Koordinator" 2 "System_aktiv_alle_Freigaben_liegen_vor" 3 "System_aktiv_mindestens_eine_Freigabe_fehlt" ;
VAL_ 958 MO_StartStopp_Wiederstart 0 "Wiederstart_inaktiv" 1 "Wiederstart_aktiv" ;
VAL_ 958 MO_StartStopp_Motorstopp 0 "Motor_Stop_inaktiv" 1 "Motor_Stop_aktiv" ;
VAL_ 958 MO_Freig_Reku 0 "Rekuperations-Modus aus" 1 "Empfehlung Spannungsanhebung" 2 "Empfehlung Spannungsabsenkung" 3 "Rekuperationsmodus aktiv, Spannungsvariation nicht notwendig" ;
VAL_ 958 MO_Kl_75 0 "Aus" 1 "Ein" ;
VAL_ 958 MO_Kl_50 0 "aus" 1 "KL50_ein_Startausfuehrung_Fahrer" ;
VAL_ 958 MO_Gangposition 0 "Gang_N" 1 "Gang_1" 2 "Gang_2" 3 "Gang_3" 4 "Gang_4" 5 "Gang_5" 6 "Gang_6" 7 "Gang_7" 8 "Gang_8" 9 "Automat_P" 10 "Automat_Vorwaerts_S" 11 "Automat_Vorwaerts_D/E" 12 "Zwischenstellung" 13 "Gang_R" 14 "Istgang_nicht_definiert" 15 "Fehler" ;
VAL_ 958 MO_StartStopp_Fahrerwunsch 0 "Init" 1 "Stoppverbot_durch_Fahrer" 2 "Stoppfreigabe_durch_Fahrer" 3 "Stoppanforderung_durch_Fahrer" ;
VAL_ 958 MO_HYB_Fahrbereitschaft 0 "keine_Fahrbereitschaft" 1 "Fahrbereitschaft" ;
VAL_ 958 MO_Ext_E_Fahrt_aktiv 0 "Rueckmeldung_E_Taster_aus" 1 "Rueckmeldung_E_Taster_ein" ;
VAL_ 958 MO_Fahrer_bremst 0 "kein_Bremsen" 1 "Bremse_betaetigt" ;
VAL_ 958 MO_QBit_Fahrer_bremst 0 "gueltiger_Wert" 1 "Ersatz_Init_oder_Fehlerwert" ;
VAL_ 958 MO_BLS 0 "kein_Bremsen" 1 "Bremse_betaetigt" ;
VAL_ 958 MO_Konsistenz_Bremsped 0 "Bremspedalinformation_plausibel" 1 "Bremspedalinformation_unplausibel" ;
VAL_ 958 MO_KomFehler_ESP 0 "kein_Fehler" 1 "Fehler" ;
VAL_ 958 MO_Klima_Eingr 0 "kein Eingriff" 1 "Klimakompressor ausschalten" 2 "Klimakompressor Leistungsreduzierung" 3 "Klimakompressor aufgrund der Heissleuchtenvorwarnung ausschalten" ;
VAL_ 958 MO_Aussp_Anlass 0 "Anlasser_darf_angesteuert_werden" 1 "Anlasser_ausspuren__Ansteuerung_nicht_moeglich" ;
VAL_ 958 MO_Freig_Anlass 0 "Start_nicht_zulaessig" 1 "Startfreigabe" ;
VAL_ 958 MO_Kuppl_schalter 0 "Schalter_sagt_ausgekuppelt" 1 "Schalter_sagt_eingekuppelt" ;
VAL_ 958 MO_Interlock 0 "Interlockschalter_nicht_betaetigt" 1 "Interlockschalter_betaetigt" ;
VAL_ 958 MO_Motor_laeuft 0 "Motor_laeuft_nicht" 1 "Motor_laeuft_autark_und_stabil_und_darf_mechanisch_belastet_werden" ;
VAL_ 958 MO_Kickdown 0 "kein_Kickdown" 1 "Kickdown" ;
VAL_ 958 MO_QBit_KL_75 0 "gueltiger_Wert" 1 "Ersatz_Init_oder_Fehlerwert" ;
VAL_ 958 MO_EKlKomLeiRed 0 "keine_Leistungsbegr" 1 "Leistungsbegr_75" 2 "Leistungsbegr_50" 3 "Leistungsbegr_25" ;
VAL_ 958 MO_Handshake_STH 0 "keine EKP-Ansteuerung durch STH-Anforderung" 1 "EKP-Ansteuerung durch STH-Anforderung" ;
VAL_ 958 MO_BKV_Unterdruckwarnung 0 "Unterdruckhaushalt_iO" 1 "Unterdruckhaushalt_niO" ;
VAL_ 958 MO_Freigabe_Segeln 0 "Segelbetrieb_nicht_freigegeben" 1 "Segelbetrieb_freigegeben" ;
VAL_ 958 MO_PTC_Status 0 "nicht_unterstuetzt" 1 "Stufe_0" 2 "Stufe_1" 3 "Stufe_2" 4 "Stufe_3" 7 "PTC_am_BCM" ;
VAL_ 958 MO_QBit_Gangposition 0 "gueltiger_Wert" 1 "Ersatz_Init_oder_Fehlerwert" ;
VAL_ 958 MO_Signalquelle_Gangposition 0 "Sensorsignal" 1 "Modellsignal" ;
VAL_ 958 MO_Remotestart_Betrieb 0 "MSG_nicht_bereit_fuer_RS_Betrieb" 1 "MSG_bereit_fuer_oder_im_RS_Betrieb" ;
VAL_ 958 MO_Remotestart_moeglich 0 "Remotestart_nicht_moeglich" 1 "Remotestart_moeglich" ;
VAL_ 958 MO_FMAus_aktiv 0 "inaktiv" 1 "Segeln_mit_Motor_aus_aktiv" ;
VAL_ 958 MO_FMAus_Startvariante 0 "kein_Motorstart" 1 "Motorstart_elektrischer_Starter" 2 "GetriebeAnschleppstart" 3 "GetriebeNotAnschleppstart" ;
VAL_ 958 MO_BMS_NV_Anf_stuetzen 0 "nicht_notwendig" 1 "notwendig" ;
VAL_ 958 MO_Zylinderabschaltung 0 "Vollmotorbetrieb_VMB" 1 "Uebergang_HMB_in_VMB" 2 "Uebergang_VMB_in_HMB" 3 "Halbmotorbetrieb_HMB" ;
VAL_ 958 MO_HYB_VM_aktiv 0 "VM_nicht_aktiv" 1 "VM_aktiv" ;
VAL_ 958 MO_StartVorauss_erfuellt 0 "Signal_nicht_bedient" 1 "StartVorauss_nicht_ueberpruefbar" 2 "StartVorauss_nicht_erfuellt" 3 "StartVorauss_erfuellt" ;
VAL_ 994 MXB_Allgemein_li_defekt 0 "kein_Fehler" 1 "Fehler" ;
VAL_ 994 MXB_Allgemein_re_defekt 0 "kein_Fehler" 1 "Fehler" ;
VAL_ 994 MXB_Sicherheitspos_li_Anf 0 "nicht_angefordert" 1 "angefordert" ;
VAL_ 994 MXB_Sicherheitspos_re_Anf 0 "nicht_angefordert" 1 "angefordert" ;
VAL_ 994 MXB_Z_Fernlicht_L_Anf 0 "Zusatzfernlicht_links_aus" 1 "Zusatzfernlicht_links_ein" ;
VAL_ 994 MXB_Z_Fernlicht_L_Schaltart 0 "Schalten_hart" 1 "Schalten_mit_Rampe" ;
VAL_ 994 MXB_Z_Fernlicht_R_Anf 0 "Zusatzfernlicht_rechts_aus" 1 "Zusatzfernlicht_rechts_ein" ;
VAL_ 994 MXB_Z_Fernlicht_R_Schaltart 0 "Schalten_hart" 1 "Schalten_mit_Rampe" ;
VAL_ 2463978604 MXB_Blickwinkel_L 254 "Init" 255 "Fehler" ;
VAL_ 2463978604 MXB_Blickwinkel_R 254 "Init" 255 "Fehler" ;
VAL_ 2463978604 MXB_Baustellenlicht_L_Anf 0 "keine_Anforderung" 1 "Anforderung" ;
VAL_ 2463978604 MXB_Baustellenlicht_R_Anf 0 "keine_Anforderung" 1 "Anforderung" ;
VAL_ 2463978604 MXB_AWL_Sichtweitenanpassung 255 "Fehler" ;
VAL_ 1358 MXB_L_Fernl_MXB_Def_1 0 "kein_Fehler" 1 "Fehler" ;
VAL_ 1358 MXB_L_Fernl_MXB_Def_2 0 "kein_Fehler" 1 "Fehler" ;
VAL_ 1358 MXB_L_Fernl_MXB_Def_3 0 "kein_Fehler" 1 "Fehler" ;
VAL_ 1358 MXB_L_Fernl_MXB_Def_4 0 "kein_Fehler" 1 "Fehler" ;
VAL_ 1358 MXB_L_Fernl_MXB_Def_5 0 "kein_Fehler" 1 "Fehler" ;
VAL_ 1358 MXB_L_Fernl_MXB_Def_6 0 "kein_Fehler" 1 "Fehler" ;
VAL_ 1358 MXB_L_Fernl_MXB_Def_7 0 "kein_Fehler" 1 "Fehler" ;
VAL_ 1358 MXB_L_Fernl_MXB_Def_Err_Gultig 0 "Fehler_nicht_gueltig" 1 "Fehler_gueltig" ;
VAL_ 1358 MXB_L_Allg_Elektr_Def_1 0 "kein_Fehler" 1 "Fehler" ;
VAL_ 1358 MXB_L_Allg_Elektr_Def_2 0 "kein_Fehler" 1 "Fehler" ;
VAL_ 1358 MXB_L_Allg_Elektr_Def_3 0 "kein_Fehler" 1 "Fehler" ;
VAL_ 1358 MXB_L_Allg_Elektr_Def_4 0 "kein_Fehler" 1 "Fehler" ;
VAL_ 1358 MXB_L_Allg_Elektr_Def_5 0 "kein_Fehler" 1 "Fehler" ;
VAL_ 1358 MXB_L_Allg_Elektr_Def_6 0 "kein_Fehler" 1 "Fehler" ;
VAL_ 1358 MXB_L_Allg_Elektr_Def_7 0 "kein_Fehler" 1 "Fehler" ;
VAL_ 1358 MXB_L_Allg_Elektr_Def_8 0 "kein_Fehler" 1 "Fehler" ;
VAL_ 1358 MXB_L_Allg_Elektr_Def_Err_Gultig 0 "Fehler_nicht_gueltig" 1 "Fehler_gueltig" ;
VAL_ 1358 MXB_L_Luefter_1_Def_1 0 "kein_Fehler" 1 "Fehler" ;
VAL_ 1358 MXB_L_Luefter_1_Def_2 0 "kein_Fehler" 1 "Fehler" ;
VAL_ 1358 MXB_L_Luefter_1_Def_3 0 "kein_Fehler" 1 "Fehler" ;
VAL_ 1358 MXB_L_Luefter_1_Def_4 0 "kein_Fehler" 1 "Fehler" ;
VAL_ 1358 MXB_L_Luefter_2_Def_1 0 "kein_Fehler" 1 "Fehler" ;
VAL_ 1358 MXB_L_Luefter_2_Def_2 0 "kein_Fehler" 1 "Fehler" ;
VAL_ 1358 MXB_L_Luefter_2_Def_3 0 "kein_Fehler" 1 "Fehler" ;
VAL_ 1358 MXB_L_Luefter_2_Def_4 0 "kein_Fehler" 1 "Fehler" ;
VAL_ 1358 MXB_L_Luefter_1_Def_Err_Gultig 0 "Fehler_nicht_gueltig" 1 "Fehler_gueltig" ;
VAL_ 1358 MXB_L_Luefter_2_Def_Err_Gultig 0 "Fehler_nicht_gueltig" 1 "Fehler_gueltig" ;
VAL_ 1358 MXB_L_Allg_Elektr_Def 0 "Init" ;
VAL_ 1358 MXB_L_Fernl_MXB_Def 0 "Init" ;
